VERSION ""

NS_ :

BS_:

BU_: ADAS ADASBUS_Virtual_ECU FCM GW PKC

BO_ 821 BCM_0x335: 8 GW
 SG_ BCM_335_CheckSum : 7|8@0+ (1,0) [0|255] ""  ADAS,FCM,PKC
 SG_ BCM_335_AliveCounter : 11|4@0+ (1,0) [0|14] ""  ADAS,FCM,PKC
 SG_ BCM_WiprInSrvPosn : 12|1@0+ (1,0) [0|1] ""  ADASBUS_Virtual_ECU
 SG_ BCM_IntLampTiSetSts : 15|3@0+ (1,0) [0|7] ""  ADASBUS_Virtual_ECU
 SG_ BCM_WaterPosnSnsrSwtSts : 16|1@0+ (1,0) [0|1] ""  ADASBUS_Virtual_ECU
 SG_ BCM_FrntFogLampOutpCmd : 17|1@0+ (1,0) [0|1] ""  ADAS
 SG_ BCM_LicPlateLampOutpCmd : 18|1@0+ (1,0) [0|1] ""  ADASBUS_Virtual_ECU
 SG_ BCM_EnaSts_ADB : 19|1@0+ (1,0) [0|1] ""  ADAS
 SG_ BCM_PwrSaveOutpCmd : 20|1@0+ (1,0) [0|1] ""  ADASBUS_Virtual_ECU
 SG_ BCM_ExtLampSwtSts : 23|3@0+ (1,0) [0|7] ""  ADAS,FCM
 SG_ BCM_HornOutpCmd : 24|1@0+ (1,0) [0|1] ""  ADASBUS_Virtual_ECU
 SG_ BCM_HornSwtSts : 25|1@0+ (1,0) [0|1] ""  ADASBUS_Virtual_ECU
 SG_ BCM_WelLampOutpCmd : 26|1@0+ (1,0) [0|1] ""  ADASBUS_Virtual_ECU
 SG_ BCM_FolwMeHomeSts : 27|1@0+ (1,0) [0|1] ""  ADASBUS_Virtual_ECU
 SG_ BCM_FrntFogLampSwtSts : 28|1@0+ (1,0) [0|1] ""  ADAS
 SG_ BCM_ReFogLampSwtSts : 29|1@0+ (1,0) [0|1] ""  ADAS,FCM
 SG_ BCM_ReWiprBackSwtSts : 30|1@0+ (1,0) [0|1] ""  ADAS
 SG_ BCM_RainClsSunroofSetSts : 31|1@0+ (1,0) [0|0] ""  ADASBUS_Virtual_ECU
 SG_ BCM_MirrLockAutoSetSts : 32|1@0+ (1,0) [0|1] ""  ADASBUS_Virtual_ECU
 SG_ BCM_FrntWshrOutpCmd : 33|1@0+ (1,0) [0|1] ""  ADASBUS_Virtual_ECU
 SG_ BCM_DangerAlrmLampSwtSts : 34|1@0+ (1,0) [0|1] ""  ADAS,PKC
 SG_ BCM_ReDefrstHeatgCmd : 35|1@0+ (1,0) [0|1] ""  ADASBUS_Virtual_ECU
 SG_ BCM_RvsLampOutpCmd : 36|1@0+ (1,0) [0|1] ""  ADAS
 SG_ BCM_IntLampOutpCmd : 37|1@0+ (1,0) [0|1] ""  ADASBUS_Virtual_ECU
 SG_ BCM_LeTrunLampOutpCmd : 38|1@0+ (1,0) [0|1] ""  ADAS
 SG_ BCM_RiTrunLampOutpCmd : 39|1@0+ (1,0) [0|1] ""  ADAS
 SG_ BCM_ReWiprOutpCmd : 40|1@0+ (1,0) [0|1] ""  ADAS
 SG_ BCM_ReWshrOutpCmd : 41|1@0+ (1,0) [0|1] ""  ADASBUS_Virtual_ECU
 SG_ BCM_BrkLampSwtSts : 42|1@0+ (1,0) [0|1] ""  ADAS
 SG_ BCM_HiBeamOutpCmd : 43|1@0+ (1,0) [0|1] ""  ADAS,FCM
 SG_ BCM_LoBeamOutpCmd : 44|1@0+ (1,0) [0|1] ""  ADAS,FCM
 SG_ BCM_PosnLampOutpCmd : 46|2@0+ (1,0) [0|3] ""  ADAS
 SG_ BCM_BrkLampOutpCmd : 47|1@0+ (1,0) [0|1] ""  ADAS
 SG_ BCM_ReFogLampOutpCmd : 48|1@0+ (1,0) [0|1] ""  ADAS
 SG_ BCM_FrntWiprSpd : 54|6@0+ (1,0) [0|63] "time/m"  ADAS,FCM
 SG_ BCM_EnaReq_ADB : 55|1@0+ (1,0) [0|1] ""  ADAS
 SG_ BCM_VehAmbBri : 63|8@0+ (100,0) [0|25400] "lx"  ADAS

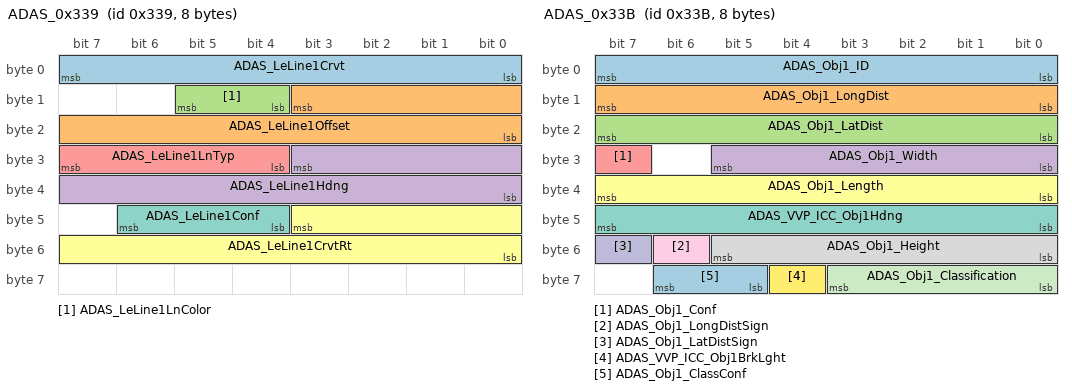
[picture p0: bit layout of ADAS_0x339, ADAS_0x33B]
BO_ 825 ADAS_0x339: 8 ADAS
 SG_ ADAS_LeLine1Crvt : 7|8@0+ (50,-3150) [-3150|3200] "m"  GW
 SG_ ADAS_LeLine1Offset : 11|12@0+ (0.0125,0) [0|50] "m"  GW
 SG_ ADAS_LeLine1LnColor : 13|2@0+ (1,0) [0|3] ""  GW
 SG_ ADAS_LeLine1Hdng : 27|12@0+ (0.05,0) [0|180] "deg"  GW
 SG_ ADAS_LeLine1LnTyp : 31|4@0+ (1,0) [0|15] ""  GW
 SG_ ADAS_LeLine1CrvtRt : 43|12@0+ (0.05,0) [0|180] "xx"  GW
 SG_ ADAS_LeLine1Conf : 46|3@0+ (1,0) [0|7] ""  GW

BO_ 827 ADAS_0x33B: 8 ADAS
 SG_ ADAS_Obj1_ID : 7|8@0+ (1,0) [0|255] ""  GW
 SG_ ADAS_Obj1_LongDist : 15|8@0+ (0.2,0) [0|51] "m"  GW
 SG_ ADAS_Obj1_LatDist : 23|8@0+ (0.2,0) [0|51] "m"  GW
 SG_ ADAS_Obj1_Width : 29|6@0+ (0.1,0) [0|6.3] "m"  GW
 SG_ ADAS_Obj1_Conf : 31|1@0+ (1,0) [0|1] ""  GW
 SG_ ADAS_Obj1_Length : 39|8@0+ (0.2,0) [0|50] "m"  GW
 SG_ ADAS_VVP_ICC_Obj1Hdng : 47|8@0+ (1.5,0) [0|360] "deg"  GW
 SG_ ADAS_Obj1_Height : 53|6@0+ (0.1,0) [0|6.3] "m"  GW
 SG_ ADAS_Obj1_LongDistSign : 54|1@0+ (1,0) [0|1] ""  GW
 SG_ ADAS_Obj1_LatDistSign : 55|1@0+ (1,0) [0|1] ""  GW
 SG_ ADAS_Obj1_Classification : 59|4@0+ (1,0) [0|15] ""  GW
 SG_ ADAS_VVP_ICC_Obj1BrkLght : 60|1@0+ (1,0) [0|1] ""  GW
 SG_ ADAS_Obj1_ClassConf : 62|2@0+ (1,0) [0|3] ""  GW

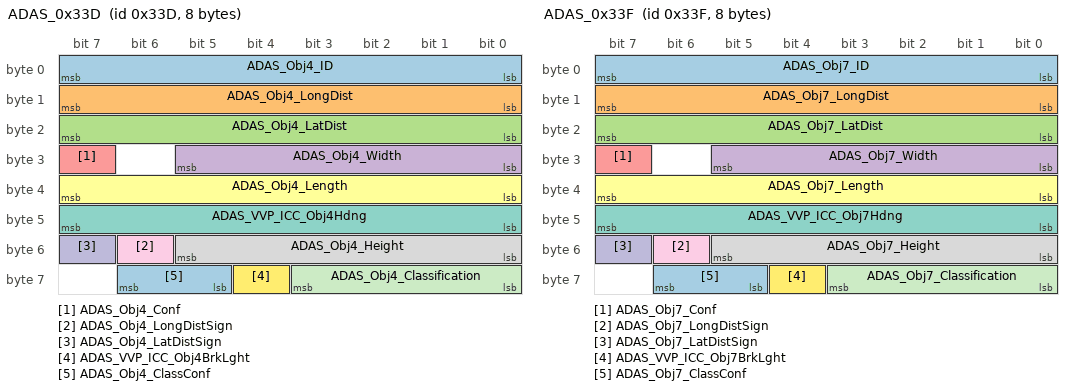
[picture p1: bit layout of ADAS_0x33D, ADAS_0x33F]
BO_ 829 ADAS_0x33D: 8 ADAS
 SG_ ADAS_Obj4_ID : 7|8@0+ (1,0) [0|255] ""  GW
 SG_ ADAS_Obj4_LongDist : 15|8@0+ (0.2,0) [0|51] "m"  GW
 SG_ ADAS_Obj4_LatDist : 23|8@0+ (0.2,0) [0|51] "m"  GW
 SG_ ADAS_Obj4_Width : 29|6@0+ (0.1,0) [0|6.3] "m"  GW
 SG_ ADAS_Obj4_Conf : 31|1@0+ (1,0) [0|1] ""  GW
 SG_ ADAS_Obj4_Length : 39|8@0+ (0.2,0) [0|50] "m"  GW
 SG_ ADAS_VVP_ICC_Obj4Hdng : 47|8@0+ (1.5,0) [0|360] "deg"  GW
 SG_ ADAS_Obj4_Height : 53|6@0+ (0.1,0) [0|6.3] "m"  GW
 SG_ ADAS_Obj4_LongDistSign : 54|1@0+ (1,0) [0|1] ""  GW
 SG_ ADAS_Obj4_LatDistSign : 55|1@0+ (1,0) [0|1] ""  GW
 SG_ ADAS_Obj4_Classification : 59|4@0+ (1,0) [0|15] ""  GW
 SG_ ADAS_VVP_ICC_Obj4BrkLght : 60|1@0+ (1,0) [0|1] ""  GW
 SG_ ADAS_Obj4_ClassConf : 62|2@0+ (1,0) [0|3] ""  GW

BO_ 831 ADAS_0x33F: 8 ADAS
 SG_ ADAS_Obj7_ID : 7|8@0+ (1,0) [0|255] ""  GW
 SG_ ADAS_Obj7_LongDist : 15|8@0+ (0.2,0) [0|51] "m"  GW
 SG_ ADAS_Obj7_LatDist : 23|8@0+ (0.2,0) [0|51] "m"  GW
 SG_ ADAS_Obj7_Width : 29|6@0+ (0.1,0) [0|6.3] "m"  GW
 SG_ ADAS_Obj7_Conf : 31|1@0+ (1,0) [0|1] ""  GW
 SG_ ADAS_Obj7_Length : 39|8@0+ (0.2,0) [0|50] "m"  GW
 SG_ ADAS_VVP_ICC_Obj7Hdng : 47|8@0+ (1.5,0) [0|360] "deg"  GW
 SG_ ADAS_Obj7_Height : 53|6@0+ (0.1,0) [0|6.3] "m"  GW
 SG_ ADAS_Obj7_LongDistSign : 54|1@0+ (1,0) [0|1] ""  GW
 SG_ ADAS_Obj7_LatDistSign : 55|1@0+ (1,0) [0|1] ""  GW
 SG_ ADAS_Obj7_Classification : 59|4@0+ (1,0) [0|15] ""  GW
 SG_ ADAS_VVP_ICC_Obj7BrkLght : 60|1@0+ (1,0) [0|1] ""  GW
 SG_ ADAS_Obj7_ClassConf : 62|2@0+ (1,0) [0|3] ""  GW

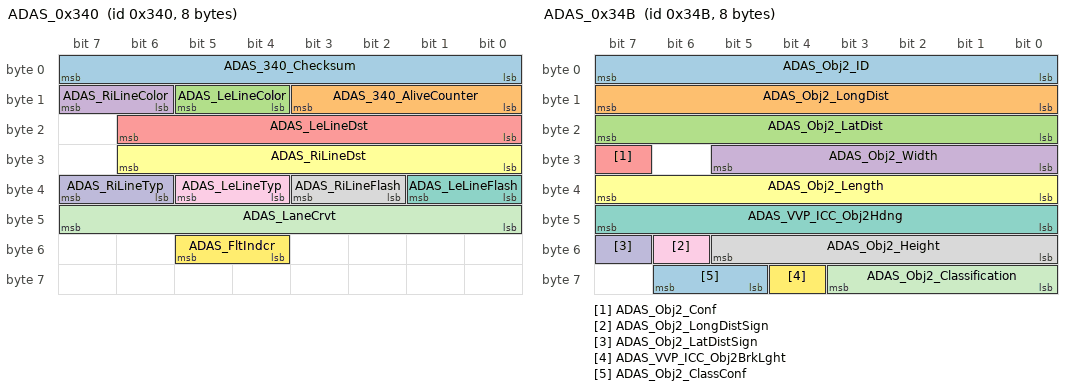
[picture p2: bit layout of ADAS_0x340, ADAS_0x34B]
BO_ 832 ADAS_0x340: 8 ADAS
 SG_ ADAS_340_Checksum : 7|8@0+ (1,0) [0|255] ""  GW
 SG_ ADAS_340_AliveCounter : 11|4@0+ (1,0) [0|14] ""  GW
 SG_ ADAS_LeLineColor : 13|2@0+ (1,0) [0|3] ""  GW
 SG_ ADAS_RiLineColor : 15|2@0+ (1,0) [0|3] ""  GW
 SG_ ADAS_LeLineDst : 22|7@0+ (0.1,-6.2) [-6.2|6.2] "m"  GW
 SG_ ADAS_RiLineDst : 30|7@0+ (0.1,-6.2) [-6.2|6.2] "m"  GW
 SG_ ADAS_LeLineFlash : 33|2@0+ (1,0) [0|3] ""  GW
 SG_ ADAS_RiLineFlash : 35|2@0+ (1,0) [0|3] ""  GW
 SG_ ADAS_LeLineTyp : 37|2@0+ (1,0) [0|3] ""  GW
 SG_ ADAS_RiLineTyp : 39|2@0+ (1,0) [0|3] ""  GW
 SG_ ADAS_LaneCrvt : 47|8@0+ (50,-3150) [-3150|3200] "m"  GW
 SG_ ADAS_FltIndcr : 53|2@0+ (1,0) [0|3] ""  GW

BO_ 834 ADAS_0x342: 8 ADAS
 SG_ ADAS_342_Checksum : 7|8@0+ (1,0) [0|255] ""  GW,PKC
 SG_ ADAS_342_AliveCounter : 11|4@0+ (1,0) [0|14] ""  GW,PKC
 SG_ ADAS_LatCtrl_LeTurnLampReq : 13|2@0+ (1,0) [0|3] ""  GW
 SG_ ADAS_LatCtrl_RiTurnLampReq : 15|2@0+ (1,0) [0|3] ""  GW
 SG_ ADAS_LatCtrl_HapticReq : 17|2@0+ (1,0) [0|3] ""  GW
 SG_ ADAS_LatCtrl_HzrdLampReq : 19|2@0+ (1,0) [0|3] ""  GW
 SG_ ADAS_VehMovDir : 21|2@0+ (1,0) [0|3] ""  GW,PKC
 SG_ ADAS_HOD_HandsOnWarnReq : 23|2@0+ (1,0) [0|1] ""  GW
 SG_ ADAS_DoorLockReq : 25|2@0+ (1,0) [0|3] ""  GW
 SG_ ADAS_AVASReq : 27|2@0+ (1,0) [0|3] ""  GW
 SG_ ADAS_RAPAvl : 28|1@0+ (1,0) [0|1] ""  GW,PKC
 SG_ ADAS_TPReplayAvl : 29|1@0+ (1,0) [0|1] ""  GW,PKC
 SG_ ADAS_TPReplaySuc : 30|1@0+ (1,0) [0|1] ""  GW,PKC
 SG_ ADAS_Sts_RAP : 34|3@0+ (1,0) [0|7] ""  GW,PKC
 SG_ ADAS_Sts_TP : 37|3@0+ (1,0) [0|7] ""  GW,PKC
 SG_ ADAS_ExtLightReq : 38|1@0+ (1,0) [0|1] ""  GW
 SG_ ADAS_HODSts : 42|3@0+ (1,0) [0|7] ""  GW

BO_ 835 BCM_0x343: 8 GW
 SG_ BCM_343_CheckSum : 7|8@0+ (1,0) [0|255] ""  ADAS,PKC
 SG_ BCM_343_AliveCounter : 11|4@0+ (1,0) [0|14] ""  ADAS,PKC
 SG_ BCM_RemReqFb : 13|2@0+ (1,0) [0|3] ""  ADASBUS_Virtual_ECU
 SG_ BCM_APASwSts : 15|2@0+ (1,0) [0|3] ""  ADAS
 SG_ BCM_FrntHoodLidSts : 16|1@0+ (1,0) [0|1] ""  ADAS,PKC
 SG_ BCM_SunroofAntipinchSts : 17|1@0+ (1,0) [0|1] ""  ADAS
 SG_ BCM_FrntDrDoorLockSts : 18|1@0+ (1,0) [0|1] ""  ADAS,PKC
 SG_ BCM_TrRelsSwtSts : 19|1@0+ (1,0) [0|1] ""  ADAS,PKC
 SG_ BCM_LockAllDoorCmd : 20|1@0+ (1,0) [0|1] ""  ADAS
 SG_ BCM_DrFrntDoorSts : 21|1@0+ (1,0) [0|1] ""  ADAS,PKC
 SG_ BCM_PasFrntDoorSts : 22|1@0+ (1,0) [0|1] ""  ADAS,PKC
 SG_ BCM_AntithftSts : 25|2@0+ (1,0) [0|3] ""  PKC
 SG_ BCM_CenLockSwtSts : 27|2@0+ (1,0) [0|3] ""  ADAS,PKC
 SG_ BCM_DoorUnlockSetFb : 28|1@0+ (1,0) [0|1] ""  ADASBUS_Virtual_ECU
 SG_ BCM_RiReDoorSts : 29|1@0+ (1,0) [0|1] ""  ADAS,PKC
 SG_ BCM_LeReDoorSts : 30|1@0+ (1,0) [0|1] ""  ADAS,PKC
 SG_ BCM_LeFrntWinSts : 31|1@0+ (1,0) [0|1] ""  ADAS,PKC
 SG_ BCM_RiFrntWinSts : 32|1@0+ (1,0) [0|1] ""  ADAS,PKC
 SG_ BCM_LeReWinSts : 33|1@0+ (1,0) [0|1] ""  ADAS,PKC
 SG_ BCM_RiReWinSt : 34|1@0+ (1,0) [0|1] ""  ADAS,PKC
 SG_ BCM_SunroofSts : 35|1@0+ (1,0) [0|1] ""  ADAS,PKC
 SG_ BCM_FolwMeSetStsFb : 38|3@0+ (1,0) [0|7] ""  ADASBUS_Virtual_ECU
 SG_ BCM_DrvrDoorUnlckOutpCmd : 39|1@0+ (1,0) [0|1] ""  ADASBUS_Virtual_ECU
 SG_ BCM_PassDoorUnlckOutpCmd : 40|1@0+ (1,0) [0|1] ""  ADASBUS_Virtual_ECU
 SG_ BCM_LeDRLOutpCmd : 41|1@0+ (1,0) [0|1] ""  ADASBUS_Virtual_ECU
 SG_ BCM_RiDRLOutpCmd : 42|1@0+ (1,0) [0|1] ""  ADASBUS_Virtual_ECU
 SG_ BCM_ArmedClsWinSetSts : 44|1@0+ (1,0) [0|1] ""  ADASBUS_Virtual_ECU
 SG_ BCM_OffAutoUnlckSetSts : 45|1@0+ (1,0) [0|1] ""  ADASBUS_Virtual_ECU
 SG_ BCM_WarnVbrnSts : 46|1@0+ (1,0) [0|1] ""  ADAS
 SG_ BCM_SunroofPosnInfo : 55|7@0+ (1,0) [0|127] "%"  PKC
 SG_ BCM_SunroofOpenAr : 56|1@0+ (1,0) [0|1] ""  ADASBUS_Virtual_ECU
 SG_ BCM_SteerWhlVbrnAlrmAvl : 58|2@0+ (1,0) [0|3] ""  ADAS
 SG_ BCM_SunroofRunngSts : 61|3@0+ (1,0) [0|7] ""  ADAS
 SG_ BCM_MirrCmd : 63|2@0+ (1,0) [0|3] ""  ADAS

BO_ 843 ADAS_0x34B: 8 ADAS
 SG_ ADAS_Obj2_ID : 7|8@0+ (1,0) [0|255] ""  GW
 SG_ ADAS_Obj2_LongDist : 15|8@0+ (0.2,0) [0|51] "m"  GW
 SG_ ADAS_Obj2_LatDist : 23|8@0+ (0.2,0) [0|51] "m"  GW
 SG_ ADAS_Obj2_Width : 29|6@0+ (0.1,0) [0|6.3] "m"  GW
 SG_ ADAS_Obj2_Conf : 31|1@0+ (1,0) [0|1] ""  GW
 SG_ ADAS_Obj2_Length : 39|8@0+ (0.2,0) [0|50] "m"  GW
 SG_ ADAS_VVP_ICC_Obj2Hdng : 47|8@0+ (1.5,0) [0|360] "deg"  GW
 SG_ ADAS_Obj2_Height : 53|6@0+ (0.1,0) [0|6.3] "m"  GW
 SG_ ADAS_Obj2_LongDistSign : 54|1@0+ (1,0) [0|1] ""  GW
 SG_ ADAS_Obj2_LatDistSign : 55|1@0+ (1,0) [0|1] ""  GW
 SG_ ADAS_Obj2_Classification : 59|4@0+ (1,0) [0|15] ""  GW
 SG_ ADAS_VVP_ICC_Obj2BrkLght : 60|1@0+ (1,0) [0|1] ""  GW
 SG_ ADAS_Obj2_ClassConf : 62|2@0+ (1,0) [0|3] ""  GW

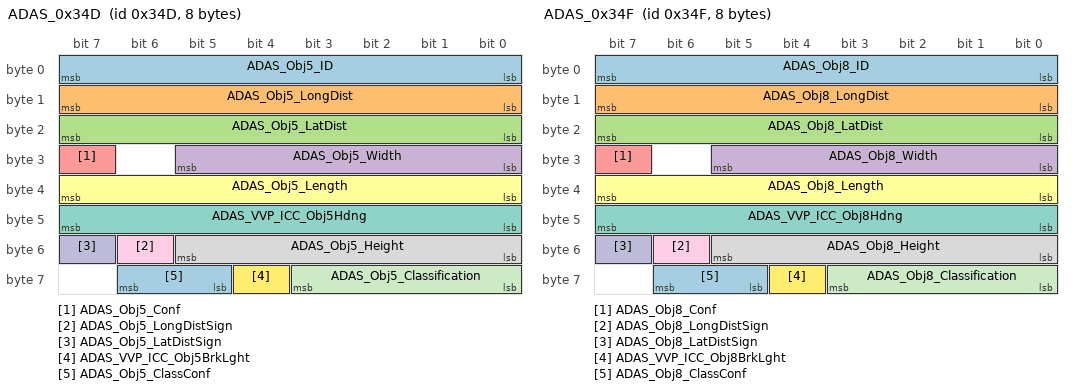
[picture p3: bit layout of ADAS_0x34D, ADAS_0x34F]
BO_ 845 ADAS_0x34D: 8 ADAS
 SG_ ADAS_Obj5_ID : 7|8@0+ (1,0) [0|255] ""  GW
 SG_ ADAS_Obj5_LongDist : 15|8@0+ (0.2,0) [0|51] "m"  GW
 SG_ ADAS_Obj5_LatDist : 23|8@0+ (0.2,0) [0|51] "m"  GW
 SG_ ADAS_Obj5_Width : 29|6@0+ (0.1,0) [0|6.3] "m"  GW
 SG_ ADAS_Obj5_Conf : 31|1@0+ (1,0) [0|1] ""  GW
 SG_ ADAS_Obj5_Length : 39|8@0+ (0.2,0) [0|50] "m"  GW
 SG_ ADAS_VVP_ICC_Obj5Hdng : 47|8@0+ (1.5,0) [0|360] "deg"  GW
 SG_ ADAS_Obj5_Height : 53|6@0+ (0.1,0) [0|6.3] "m"  GW
 SG_ ADAS_Obj5_LongDistSign : 54|1@0+ (1,0) [0|1] ""  GW
 SG_ ADAS_Obj5_LatDistSign : 55|1@0+ (1,0) [0|1] ""  GW
 SG_ ADAS_Obj5_Classification : 59|4@0+ (1,0) [0|15] ""  GW
 SG_ ADAS_VVP_ICC_Obj5BrkLght : 60|1@0+ (1,0) [0|1] ""  GW
 SG_ ADAS_Obj5_ClassConf : 62|2@0+ (1,0) [0|3] ""  GW

BO_ 847 ADAS_0x34F: 8 ADAS
 SG_ ADAS_Obj8_ID : 7|8@0+ (1,0) [0|255] ""  GW
 SG_ ADAS_Obj8_LongDist : 15|8@0+ (0.2,0) [0|51] "m"  GW
 SG_ ADAS_Obj8_LatDist : 23|8@0+ (0.2,0) [0|51] "m"  GW
 SG_ ADAS_Obj8_Width : 29|6@0+ (0.1,0) [0|6.3] "m"  GW
 SG_ ADAS_Obj8_Conf : 31|1@0+ (1,0) [0|1] ""  GW
 SG_ ADAS_Obj8_Length : 39|8@0+ (0.2,0) [0|50] "m"  GW
 SG_ ADAS_VVP_ICC_Obj8Hdng : 47|8@0+ (1.5,0) [0|360] "deg"  GW
 SG_ ADAS_Obj8_Height : 53|6@0+ (0.1,0) [0|6.3] "m"  GW
 SG_ ADAS_Obj8_LongDistSign : 54|1@0+ (1,0) [0|1] ""  GW
 SG_ ADAS_Obj8_LatDistSign : 55|1@0+ (1,0) [0|1] ""  GW
 SG_ ADAS_Obj8_Classification : 59|4@0+ (1,0) [0|15] ""  GW
 SG_ ADAS_VVP_ICC_Obj8BrkLght : 60|1@0+ (1,0) [0|1] ""  GW
 SG_ ADAS_Obj8_ClassConf : 62|2@0+ (1,0) [0|3] ""  GW

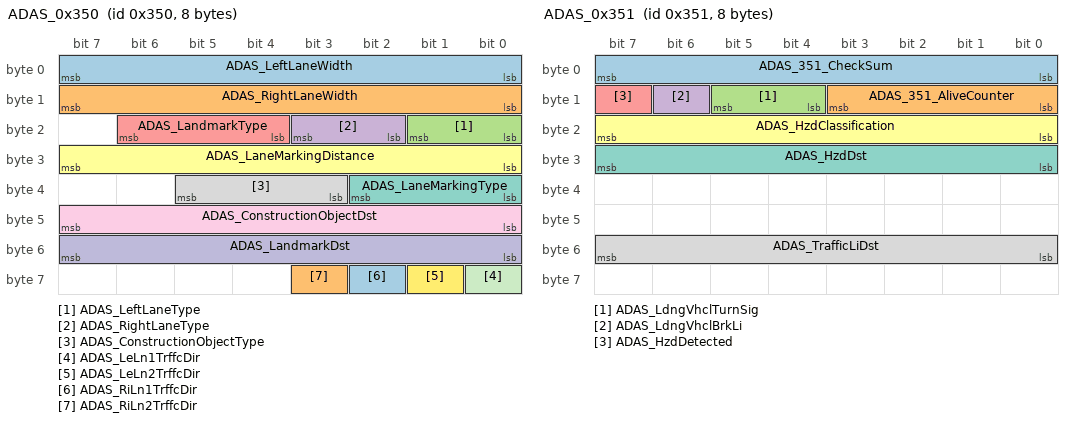
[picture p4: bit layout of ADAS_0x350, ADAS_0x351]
BO_ 848 ADAS_0x350: 8 ADAS
 SG_ ADAS_LeftLaneWidth : 7|8@0+ (0.1,0) [0|25.5] "m"  GW
 SG_ ADAS_RightLaneWidth : 15|8@0+ (0.1,0) [0|25.5] "m"  GW
 SG_ ADAS_LeftLaneType : 17|2@0+ (1,0) [0|3] ""  GW
 SG_ ADAS_RightLaneType : 19|2@0+ (1,0) [0|3] ""  GW
 SG_ ADAS_LandmarkType : 22|3@0+ (1,0) [0|7] ""  GW
 SG_ ADAS_LaneMarkingDistance : 31|8@0+ (1,0) [0|255] "m"  GW
 SG_ ADAS_LaneMarkingType : 34|3@0+ (1,0) [0|7] ""  GW
 SG_ ADAS_ConstructionObjectType : 37|3@0+ (1,0) [0|7] ""  GW
 SG_ ADAS_ConstructionObjectDst : 47|8@0+ (1,0) [0|255] "m"  GW
 SG_ ADAS_LandmarkDst : 55|8@0+ (1,0) [0|255] "m"  GW
 SG_ ADAS_LeLn1TrffcDir : 56|1@0+ (1,0) [0|1] ""  GW
 SG_ ADAS_LeLn2TrffcDir : 57|1@0+ (1,0) [0|1] ""  GW
 SG_ ADAS_RiLn1TrffcDir : 58|1@0+ (1,0) [0|1] ""  GW
 SG_ ADAS_RiLn2TrffcDir : 59|1@0+ (1,0) [0|1] ""  GW

BO_ 849 ADAS_0x351: 8 ADAS
 SG_ ADAS_351_CheckSum : 7|8@0+ (1,0) [0|255] ""  GW
 SG_ ADAS_351_AliveCounter : 11|4@0+ (1,0) [0|14] ""  GW
 SG_ ADAS_LdngVhclTurnSig : 13|2@0+ (1,0) [0|3] ""  GW
 SG_ ADAS_LdngVhclBrkLi : 14|1@0+ (1,0) [0|1] ""  GW
 SG_ ADAS_HzdDetected : 15|1@0+ (1,0) [0|1] ""  GW
 SG_ ADAS_HzdClassification : 23|8@0+ (1,0) [0|255] ""  GW
 SG_ ADAS_HzdDst : 31|8@0+ (1,0) [0|255] "m"  GW
 SG_ ADAS_TrafficLiDst : 55|8@0+ (1,0) [0|255] "m"  GW

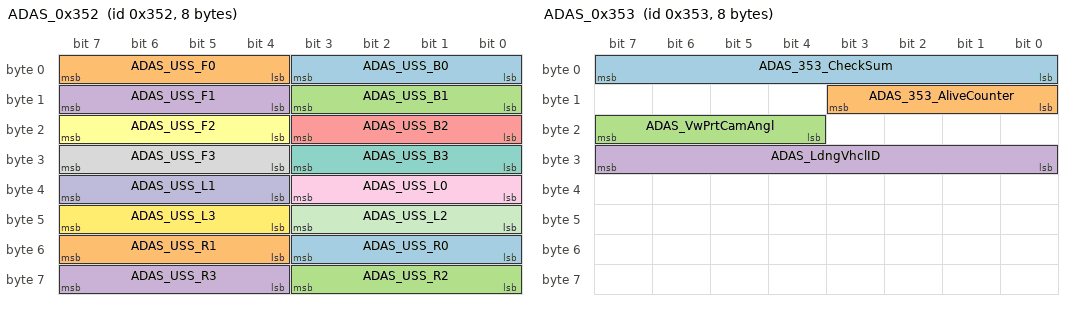
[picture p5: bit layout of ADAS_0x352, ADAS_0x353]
BO_ 850 ADAS_0x352: 8 ADAS
 SG_ ADAS_USS_B0 : 3|4@0+ (1,0) [0|15] ""  GW
 SG_ ADAS_USS_F0 : 7|4@0+ (1,0) [0|15] ""  GW
 SG_ ADAS_USS_B1 : 11|4@0+ (1,0) [0|15] ""  GW
 SG_ ADAS_USS_F1 : 15|4@0+ (1,0) [0|15] ""  GW
 SG_ ADAS_USS_B2 : 19|4@0+ (1,0) [0|15] ""  GW
 SG_ ADAS_USS_F2 : 23|4@0+ (1,0) [0|15] ""  GW
 SG_ ADAS_USS_B3 : 27|4@0+ (1,0) [0|15] ""  GW
 SG_ ADAS_USS_F3 : 31|4@0+ (1,0) [0|15] ""  GW
 SG_ ADAS_USS_L0 : 35|4@0+ (1,0) [0|15] ""  GW
 SG_ ADAS_USS_L1 : 39|4@0+ (1,0) [0|15] ""  GW
 SG_ ADAS_USS_L2 : 43|4@0+ (1,0) [0|15] ""  GW
 SG_ ADAS_USS_L3 : 47|4@0+ (1,0) [0|15] ""  GW
 SG_ ADAS_USS_R0 : 51|4@0+ (1,0) [0|15] ""  GW
 SG_ ADAS_USS_R1 : 55|4@0+ (1,0) [0|15] ""  GW
 SG_ ADAS_USS_R2 : 59|4@0+ (1,0) [0|15] ""  GW
 SG_ ADAS_USS_R3 : 63|4@0+ (1,0) [0|15] ""  GW

BO_ 851 ADAS_0x353: 8 ADAS
 SG_ ADAS_353_CheckSum : 7|8@0+ (1,0) [0|255] ""  GW
 SG_ ADAS_353_AliveCounter : 11|4@0+ (1,0) [0|14] ""  GW
 SG_ ADAS_VwPrtCamAngl : 23|4@0+ (1,0) [0|15] ""  GW
 SG_ ADAS_LdngVhclID : 31|8@0+ (1,0) [0|255] ""  GW

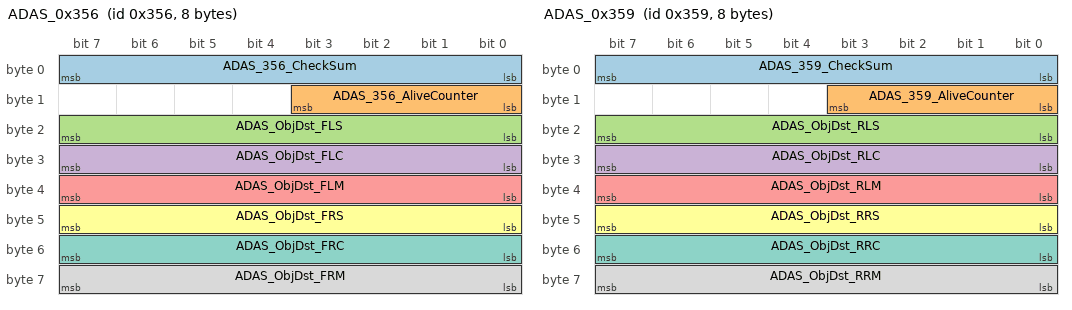
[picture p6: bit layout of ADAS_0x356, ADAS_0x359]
BO_ 854 ADAS_0x356: 8 ADAS
 SG_ ADAS_356_CheckSum : 7|8@0+ (1,0) [0|255] ""  GW
 SG_ ADAS_356_AliveCounter : 11|4@0+ (1,0) [0|14] ""  GW
 SG_ ADAS_ObjDst_FLS : 23|8@0+ (1,0) [0|255] "cm"  GW
 SG_ ADAS_ObjDst_FLC : 31|8@0+ (1,0) [0|255] "cm"  GW
 SG_ ADAS_ObjDst_FLM : 39|8@0+ (1,0) [0|255] "cm"  GW
 SG_ ADAS_ObjDst_FRS : 47|8@0+ (1,0) [0|255] "cm"  GW
 SG_ ADAS_ObjDst_FRC : 55|8@0+ (1,0) [0|255] "cm"  GW
 SG_ ADAS_ObjDst_FRM : 63|8@0+ (1,0) [0|255] "cm"  GW

BO_ 856 VCU_0x358: 8 GW
 SG_ VCU_358_CheckSum : 7|8@0+ (1,0) [0|255] ""  ADAS
 SG_ VCU_358_AliveCounter : 11|4@0+ (1,0) [0|14] ""  ADAS
 SG_ VCU_KickdwnFlg : 13|2@0+ (1,0) [0|3] ""  ADASBUS_Virtual_ECU
 SG_ VCU_EPedlEnaSig : 15|1@0+ (1,0) [0|1] ""  ADASBUS_Virtual_ECU
 SG_ VCU_ComLostFlt_ESP : 16|1@0+ (1,0) [0|1] ""  ADASBUS_Virtual_ECU
 SG_ VCU_ComFlt_iBooster : 17|1@0+ (1,0) [0|1] ""  ADASBUS_Virtual_ECU
 SG_ VCU_RegenLvlFb : 19|2@0+ (1,0) [0|3] ""  ADASBUS_Virtual_ECU
 SG_ VCU_AccelModFb : 21|2@0+ (1,0) [0|3] ""  ADASBUS_Virtual_ECU
 SG_ VCU_EPedlStsFb : 23|2@0+ (1,0) [0|3] ""  ADASBUS_Virtual_ECU
 SG_ VCU_CcTrgSpdDisp : 31|8@0+ (1,0) [0|255] ""  ADASBUS_Virtual_ECU
 SG_ VCU_Sts_CC_ICC : 35|4@0+ (1,0) [0|15] ""  ADASBUS_Virtual_ECU
 SG_ VCU_CCIconDisp : 38|3@0+ (1,0) [0|7] ""  ADASBUS_Virtual_ECU
 SG_ VCU_DispSpdUnit_CC : 39|1@0+ (1,0) [0|1] ""  ADASBUS_Virtual_ECU
 SG_ VCU_BoostEnStat : 43|4@0+ (1,0) [0|15] ""  ADASBUS_Virtual_ECU
 SG_ VCU_OTARdy_Fb : 45|2@0+ (1,0) [0|3] ""  ADASBUS_Virtual_ECU
 SG_ VCU_OTA_ECUInhb_Req : 47|2@0+ (1,0) [0|3] ""  ADAS,PKC
 SG_ VCU_OTAVehCdnChk_ASIL : 49|2@0+ (1,0) [0|3] ""  ADAS,FCM,PKC
 SG_ VCU_OTAVehInhb_ASIL_Fb : 51|2@0+ (1,0) [0|3] ""  ADAS,FCM,PKC

BO_ 857 ADAS_0x359: 8 ADAS
 SG_ ADAS_359_CheckSum : 7|8@0+ (1,0) [0|255] ""  GW
 SG_ ADAS_359_AliveCounter : 11|4@0+ (1,0) [0|14] ""  GW
 SG_ ADAS_ObjDst_RLS : 23|8@0+ (1,0) [0|255] "cm"  GW
 SG_ ADAS_ObjDst_RLC : 31|8@0+ (1,0) [0|255] "cm"  GW
 SG_ ADAS_ObjDst_RLM : 39|8@0+ (1,0) [0|255] "cm"  GW
 SG_ ADAS_ObjDst_RRS : 47|8@0+ (1,0) [0|255] "cm"  GW
 SG_ ADAS_ObjDst_RRC : 55|8@0+ (1,0) [0|255] "cm"  GW
 SG_ ADAS_ObjDst_RRM : 63|8@0+ (1,0) [0|255] "cm"  GW

BO_ 859 ICC_0x35B: 8 GW
 SG_ ICC_ViewReq : 15|4@0+ (1,0) [0|15] ""  ADAS
 SG_ ICC_ShowSts : 16|1@0+ (1,0) [0|1] ""  ADAS
 SG_ ICC_SVS_AutoVwBttnReq : 17|1@0+ (1,0) [0|1] ""  ADAS
 SG_ ICC_SVS_CamVwCnclReq : 18|1@0+ (1,0) [0|1] ""  ADAS
 SG_ ICC_AutomaticViewReq : 19|1@0+ (1,0) [0|1] ""  ADAS
 SG_ ICC_360FreeFloatingReq : 20|1@0+ (1,0) [0|1] ""  ADAS
 SG_ ICC_GraphicOverlayReq : 21|1@0+ (1,0) [0|1] ""  ADAS
 SG_ ICC_OperationType : 23|2@0+ (1,0) [0|3] ""  ADAS
 SG_ ICC_ZOOM_Start : 24|1@0+ (1,0) [0|1] ""  ADAS
 SG_ ICC_ZOOM_End : 25|1@0+ (1,0) [0|1] ""  ADAS
 SG_ ICC_ZOOM_ScalingFactor : 30|5@0+ (1,0) [0|31] ""  ADAS
 SG_ ICC_EnbLnChgAsst : 31|1@0+ (1,0) [0|1] ""  ADAS
 SG_ ICC_BSDSetting : 33|2@0+ (1,0) [0|3] ""  ADAS
 SG_ ICC_DOW_Setting : 35|2@0+ (1,0) [0|3] ""  ADAS
 SG_ ICC_DCAASetting : 37|2@0+ (1,0) [0|3] ""  ADAS
 SG_ ICC_APA_Setting : 39|2@0+ (1,0) [0|3] ""  ADAS
 SG_ ICC_APAParkSelect : 43|4@0+ (1,0) [0|15] ""  ADAS
 SG_ ICC_APAActivation : 44|1@0+ (1,0) [0|1] ""  ADAS
 SG_ ICC_APAParkInDirSetting : 45|1@0+ (1,0) [0|1] ""  ADAS
 SG_ ICC_APAParkOutDirSetting : 46|1@0+ (1,0) [0|1] ""  ADAS
 SG_ ICC_ParkAsstChmAlrt : 47|1@0+ (1,0) [0|1] ""  ADAS
 SG_ ICC_WSPPA_Setting : 49|2@0+ (1,0) [0|3] ""  ADAS
 SG_ ICC_AHBA_Setting : 50|1@0+ (1,0) [0|1] ""  ADAS
 SG_ ICC_APAParkOutAct : 52|2@0+ (1,0) [0|3] ""  ADAS
 SG_ ICC_SteerWhlVibrSet : 53|1@0+ (1,0) [0|1] ""  ADAS
 SG_ ICC_WarnTypeSetting : 55|2@0+ (1,0) [0|3] ""  ADAS
 SG_ ICC_LKA_SettingWrnTyp : 57|2@0+ (1,0) [0|3] ""  ADAS
 SG_ ICC_RAP_Setting : 59|2@0+ (1,0) [0|3] ""  ADAS
 SG_ ICC_TP_Setting : 61|2@0+ (1,0) [0|3] ""  ADAS
 SG_ ICC_BSD_Sensitivity : 63|2@0+ (1,0) [0|3] ""  ADAS

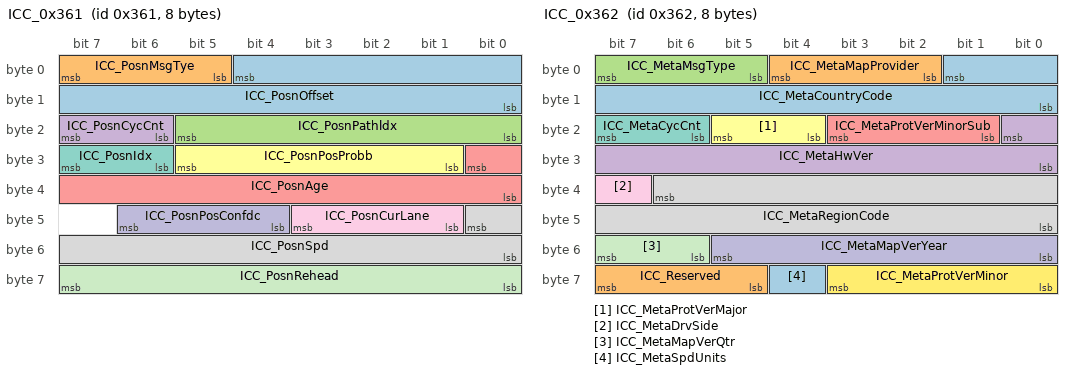
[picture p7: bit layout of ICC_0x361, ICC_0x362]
BO_ 865 ICC_0x361: 8 GW
 SG_ ICC_PosnOffset : 4|13@0+ (1,0) [0|8190] "m"  ADAS
 SG_ ICC_PosnMsgTye : 7|3@0+ (1,0) [0|7] ""  ADAS
 SG_ ICC_PosnPathldx : 21|6@0+ (1,0) [8|63] ""  ADAS
 SG_ ICC_PosnCycCnt : 23|2@0+ (1,0) [0|3] ""  ADAS
 SG_ ICC_PosnAge : 24|9@0+ (5,0) [0|2545] "ms"  ADAS
 SG_ ICC_PosnPosProbb : 29|5@0+ (3.333,0) [0|100] "%"  ADAS
 SG_ ICC_PosnIdx : 31|2@0+ (1,0) [0|3] ""  ADAS
 SG_ ICC_PosnSpd : 40|9@0+ (0.2,-12.8) [-12.8|89.2] "m/s"  ADAS
 SG_ ICC_PosnCurLane : 43|3@0+ (1,0) [0|7] ""  ADAS
 SG_ ICC_PosnPosConfdc : 46|3@0+ (1,0) [0|7] ""  ADAS
 SG_ ICC_PosnRehead : 63|8@0+ (1.417,0) [0|358.583] "degrees"  ADAS

BO_ 866 ICC_0x362: 8 GW
 SG_ ICC_MetaCountryCode : 1|10@0+ (1,0) [0|1023] ""  ADAS,FCM
 SG_ ICC_MetaMapProvider : 4|3@0+ (1,0) [0|7] "m"  ADAS
 SG_ ICC_MetaMsgType : 7|3@0+ (1,0) [0|7] ""  ADAS
 SG_ ICC_MetaHwVer : 16|9@0+ (1,0) [0|511] ""  ADAS
 SG_ ICC_MetaProtVerMinorSub : 19|3@0+ (1,0) [0|7] ""  ADAS
 SG_ ICC_MetaProtVerMajor : 21|2@0+ (1,0) [0|3] ""  ADAS
 SG_ ICC_MetaCycCnt : 23|2@0+ (1,0) [0|3] ""  ADAS
 SG_ ICC_MetaRegionCode : 38|15@0+ (1,0) [0|32767] ""  ADAS,FCM
 SG_ ICC_MetaDrvSide : 39|1@0+ (1,0) [0|1] ""  ADAS
 SG_ ICC_MetaMapVerYear : 53|6@0+ (1,2000) [2000|2063] ""  ADAS
 SG_ ICC_MetaMapVerQtr : 55|2@0+ (1,1) [1|3] ""  ADAS
 SG_ ICC_MetaProtVerMinor : 59|4@0+ (1,0) [0|15] ""  ADAS
 SG_ ICC_MetaSpdUnits : 60|1@0+ (1,0) [0|1] ""  ADAS
 SG_ ICC_Reserved : 63|3@0+ (1,0) [0|7] ""  ADAS

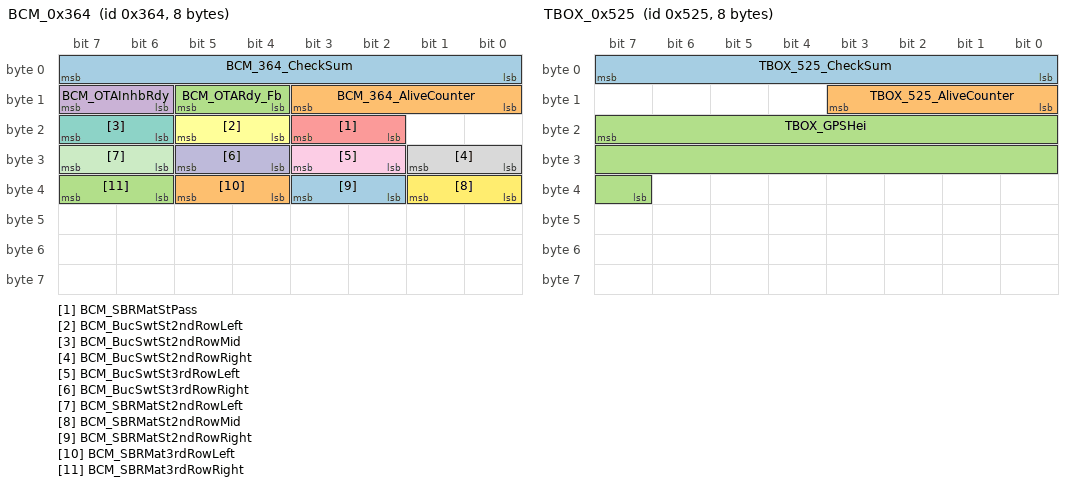
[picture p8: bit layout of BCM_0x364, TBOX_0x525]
BO_ 868 BCM_0x364: 8 GW
 SG_ BCM_364_CheckSum : 7|8@0+ (1,0) [0|255] ""  ADASBUS_Virtual_ECU
 SG_ BCM_364_AliveCounter : 11|4@0+ (1,0) [0|14] ""  ADASBUS_Virtual_ECU
 SG_ BCM_OTARdy_Fb : 13|2@0+ (1,0) [0|3] ""  ADASBUS_Virtual_ECU
 SG_ BCM_OTAInhbRdy : 15|2@0+ (1,0) [0|3] ""  ADASBUS_Virtual_ECU
 SG_ BCM_SBRMatStPass : 19|2@0+ (1,0) [0|3] ""  PKC
 SG_ BCM_BucSwtSt2ndRowLeft : 21|2@0+ (1,0) [0|3] ""  ADAS
 SG_ BCM_BucSwtSt2ndRowMid : 23|2@0+ (1,0) [0|3] ""  ADAS
 SG_ BCM_BucSwtSt2ndRowRight : 25|2@0+ (1,0) [0|3] ""  ADAS
 SG_ BCM_BucSwtSt3rdRowLeft : 27|2@0+ (1,0) [0|3] ""  ADASBUS_Virtual_ECU
 SG_ BCM_BucSwtSt3rdRowRight : 29|2@0+ (1,0) [0|3] ""  ADASBUS_Virtual_ECU
 SG_ BCM_SBRMatSt2ndRowLeft : 31|2@0+ (1,0) [0|3] ""  ADAS,PKC
 SG_ BCM_SBRMatSt2ndRowMid : 33|2@0+ (1,0) [0|3] ""  ADAS,PKC
 SG_ BCM_SBRMatSt2ndRowRight : 35|2@0+ (1,0) [0|3] ""  ADAS,PKC
 SG_ BCM_SBRMat3rdRowLeft : 37|2@0+ (1,0) [0|3] ""  ADAS
 SG_ BCM_SBRMat3rdRowRight : 39|2@0+ (1,0) [0|3] ""  ADAS

BO_ 883 ECC_0x373: 8 GW
 SG_ ECC_CrtSts : 3|4@0+ (1,0) [0|15] ""  ADASBUS_Virtual_ECU
 SG_ ECC_IninSts : 4|1@0+ (1,0) [0|1] ""  ADASBUS_Virtual_ECU
 SG_ ECC_PwrSysHeatMngtSts : 6|2@0+ (1,0) [0|3] ""  ADASBUS_Virtual_ECU
 SG_ ECC_ACSts : 7|1@0+ (1,0) [0|1] ""  ADASBUS_Virtual_ECU
 SG_ ECC_AirClnSts : 8|1@0+ (1,0) [0|1] ""  ADASBUS_Virtual_ECU
 SG_ ECC_WindSpdSts : 12|4@0+ (1,0) [0|15] ""  ADAS,FCM
 SG_ ECC_BackRowAirOutlModSts : 15|3@0+ (1,0) [0|7] ""  ADASBUS_Virtual_ECU
 SG_ ECC_DrvrTSetSts : 23|8@0+ (0.5,0) [0|127.5] ""  ADASBUS_Virtual_ECU
 SG_ ECC_PassTSetSts : 31|8@0+ (0.5,0) [0|127.5] ""  ADASBUS_Virtual_ECU
 SG_ ECC_HeatSts : 32|1@0+ (1,0) [0|1] ""  ADASBUS_Virtual_ECU
 SG_ ECC_AUTOSts : 33|1@0+ (1,0) [0|1] ""  ADASBUS_Virtual_ECU
 SG_ ECC_SYNCSts : 34|1@0+ (1,0) [0|1] ""  ADASBUS_Virtual_ECU
 SG_ ECC_InfoSysWrmColdDisp : 36|2@0+ (1,0) [0|3] ""  ADASBUS_Virtual_ECU
 SG_ ECC_CircSts : 37|1@0+ (1,0) [0|1] ""  ADASBUS_Virtual_ECU
 SG_ ECC_ParticleConcVld : 39|2@0+ (1,0) [0|3] ""  ADASBUS_Virtual_ECU
 SG_ ECC_OutdT : 47|8@0+ (0.5,-48) [-48|79.5] "Degree Celsius"  ADAS,FCM
 SG_ ECC_OutdTVld : 49|2@0+ (1,0) [0|3] ""  ADAS,FCM
 SG_ ECC_MaxFrntDefrst : 50|1@0+ (1,0) [0|1] ""  ADASBUS_Virtual_ECU
 SG_ ECC_HeatMngtSysFlt : 51|1@0+ (1,0) [0|1] ""  ADASBUS_Virtual_ECU
 SG_ ECC_HeatMngtFctLim : 52|1@0+ (1,0) [0|1] ""  ADASBUS_Virtual_ECU
 SG_ ECC_DrvrAirOutlMod : 55|3@0+ (1,0) [0|7] ""  ADASBUS_Virtual_ECU
 SG_ ECC_PassAirOutlMod : 58|3@0+ (1,0) [0|7] ""  ADASBUS_Virtual_ECU
 SG_ ECC_RemSts : 60|2@0+ (1,0) [0|3] ""  ADASBUS_Virtual_ECU
 SG_ ECC_OTAInhbRdy : 62|2@0+ (1,0) [0|3] ""  ADASBUS_Virtual_ECU

BO_ 1137 PLGM_0x471: 8 GW
 SG_ PLGM_UsrSetTrMaxHei : 7|8@0+ (1,0) [0|255] "%"  ADASBUS_Virtual_ECU
 SG_ PLGM_LeTrPosn : 15|8@0+ (1,0) [0|100] "%"  ADASBUS_Virtual_ECU
 SG_ PLGM_RiTrPosn : 23|8@0+ (1,0) [0|100] "%"  ADASBUS_Virtual_ECU
 SG_ PLGM_LiRemdngReq_BCM : 26|3@0+ (1,0) [0|7] ""  ADASBUS_Virtual_ECU
 SG_ PLGM_SoundRemdngReq_EHU : 29|3@0+ (1,0) [0|7] ""  ADASBUS_Virtual_ECU
 SG_ PLGM_FctEnaRes : 30|1@0+ (1,0) [0|1] ""  ADASBUS_Virtual_ECU
 SG_ PLGM_SysFltIndcn : 31|1@0+ (1,0) [0|1] ""  ADAS
 SG_ PLGM_TrActnHandCmd : 33|2@0+ (1,0) [0|3] ""  ADASBUS_Virtual_ECU
 SG_ PLGM_TrSwtStsIndcn : 36|3@0+ (1,0) [0|7] ""  ADAS,PKC
 SG_ PLGM_TrLtchStsIndcn : 39|3@0+ (1,0) [0|7] ""  ADAS,PKC
 SG_ PLGM_TrSwtTrigOpenReq : 40|1@0+ (1,0) [0|1] ""  PKC
 SG_ PLGM_OperMod : 42|2@0+ (1,0) [0|3] ""  ADASBUS_Virtual_ECU
 SG_ PLGM_TrSwtSts : 43|1@0+ (1,0) [0|1] ""  ADASBUS_Virtual_ECU
 SG_ PLGM_LimpHomeSts : 44|1@0+ (1,0) [0|1] ""  ADASBUS_Virtual_ECU
 SG_ PLGM_DrvrSwtSts : 45|1@0+ (1,0) [0|1] ""  ADASBUS_Virtual_ECU
 SG_ PLGM_TrInnrSwtSts : 47|2@0+ (1,0) [0|3] ""  ADASBUS_Virtual_ECU
 SG_ PLGM_AntipinchSts : 48|1@0+ (1,0) [0|1] ""  ADASBUS_Virtual_ECU
 SG_ PLGM_TrSts : 49|1@0+ (1,0) [0|1] ""  ADAS,PKC
 SG_ PLGM_OTAInhbRdy : 51|2@0+ (1,0) [0|3] ""  ADASBUS_Virtual_ECU
 SG_ PLGM_OTARdy_Fb : 53|2@0+ (1,0) [0|3] ""  ADASBUS_Virtual_ECU
 SG_ PLGM_Tindcn_NTC : 63|8@0+ (1,-40) [-40|100] "Degree Celsius"  ADASBUS_Virtual_ECU

BO_ 1153 ADAS_0x481: 8 ADAS
 SG_ ADAS_ECUUnexpectedRst : 0|1@0+ (1,0) [0|1] ""  GW
 SG_ ADAS_ChkBattVoltFlt : 1|1@0+ (1,0) [0|1] ""  GW
 SG_ ADAS_1V25UnderOrOverVolt : 2|1@0+ (1,0) [0|1] ""  GW
 SG_ ADAS_3V3UnderOrOverVolt : 3|1@0+ (1,0) [0|1] ""  GW
 SG_ ADAS_5V0UnderOrOverVolt : 4|1@0+ (1,0) [0|1] ""  GW
 SG_ ADAS_BusHwErr : 5|1@0+ (1,0) [0|1] ""  GW
 SG_ ADAS_BusHwErr_FCM : 6|1@0+ (1,0) [0|1] ""  GW
 SG_ ADAS_BusHwErr_MRR : 7|1@0+ (1,0) [0|1] ""  GW
 SG_ ADAS_BusHwErr_CMRR_FL : 8|1@0+ (1,0) [0|1] ""  GW
 SG_ ADAS_BusDiagHwErr_CMRR_FR : 9|1@0+ (1,0) [0|1] ""  GW
 SG_ ADAS_ChkInvldSig_FCM : 10|1@0+ (1,0) [0|1] ""  GW
 SG_ ADAS_ChkInvldSig_CMRR_RL : 11|1@0+ (1,0) [0|1] ""  GW
 SG_ ADAS_ChkInvldSig_CMRR_FR : 12|1@0+ (1,0) [0|1] ""  GW
 SG_ ADAS_ChkInvldSig_CMRR_FL : 13|1@0+ (1,0) [0|1] ""  GW
 SG_ ADAS_ChkInvldSig_CMRR_RR : 14|1@0+ (1,0) [0|1] ""  GW
 SG_ ADAS_ChkInvldSig_MRR : 15|1@0+ (1,0) [0|1] ""  GW
 SG_ ADAS_ChkInvldSig_ESP : 16|1@0+ (1,0) [0|1] ""  GW
 SG_ ADAS_ChkInvldSig_ACU : 17|1@0+ (1,0) [0|1] ""  GW
 SG_ ADAS_ChkInvldSig_EPS : 18|1@0+ (1,0) [0|1] ""  GW
 SG_ ADAS_ChkInvldSig_iBooster : 19|1@0+ (1,0) [0|1] ""  GW
 SG_ ADAS_ChkInvldSig_YRS : 20|1@0+ (1,0) [0|1] ""  GW
 SG_ ADAS_ChkInvldSig_BCM : 21|1@0+ (1,0) [0|1] ""  GW
 SG_ ADAS_ChkInvldSig_ECC : 22|1@0+ (1,0) [0|1] ""  GW
 SG_ ADAS_ChkInvldSig_TBOX : 23|1@0+ (1,0) [0|1] ""  GW
 SG_ ADAS_ChkInvldSig_MCU_F : 24|1@0+ (1,0) [0|1] ""  GW
 SG_ ADAS_ChkInvldSig_MCU_R : 25|1@0+ (1,0) [0|1] ""  GW
 SG_ ADAS_ChkInvldSig_PLGM : 26|1@0+ (1,0) [0|1] ""  GW
 SG_ ADAS_ChkInvldSig_CIM : 27|1@0+ (1,0) [0|1] ""  GW
 SG_ ADAS_ChkInvldSig_VCU : 28|1@0+ (1,0) [0|1] ""  GW
 SG_ ADAS_ChkInvldSig_ICC : 29|1@0+ (1,0) [0|1] ""  GW
 SG_ ADAS_ChkInvldSig_PEPS : 30|1@0+ (1,0) [0|1] ""  GW
 SG_ ADAS_ChkInvldSig_TPMS : 31|1@0+ (1,0) [0|1] ""  GW
 SG_ ADAS_ChkInvldSig_AVAP : 32|1@0+ (1,0) [0|1] ""  GW
 SG_ ADAS_ComE2EFlt : 33|1@0+ (1,0) [0|1] ""  GW
 SG_ ADAS_ComLostFlt_FCM : 34|1@0+ (1,0) [0|1] ""  GW
 SG_ ADAS_ComLostFlt_CMRR_RL : 35|1@0+ (1,0) [0|1] ""  GW
 SG_ ADAS_ComLostFlt_CMRR_FL : 36|1@0+ (1,0) [0|1] ""  GW
 SG_ ADAS_ComLostFlt_CMRR_RR : 37|1@0+ (1,0) [0|1] ""  GW
 SG_ ADAS_ComLostFlt_CMRR_FR : 38|1@0+ (1,0) [0|1] ""  GW
 SG_ ADAS_ComLostFlt_MRR : 39|1@0+ (1,0) [0|1] ""  GW
 SG_ ADAS_ComLostFlt_ESP : 40|1@0+ (1,0) [0|1] ""  GW
 SG_ ADAS_ComLostFlt_ACU : 41|1@0+ (1,0) [0|1] ""  GW
 SG_ ADAS_ComLostFlt_EPS : 42|1@0+ (1,0) [0|1] ""  GW
 SG_ ADAS_ComLostFlt_iBooster : 43|1@0+ (1,0) [0|1] ""  GW
 SG_ ADAS_ComLostFlt_YRS : 44|1@0+ (1,0) [0|1] ""  GW
 SG_ ADAS_ComLostFlt_BCM : 45|1@0+ (1,0) [0|1] ""  GW
 SG_ ADAS_ComLostFlt_ECC : 46|1@0+ (1,0) [0|1] ""  GW
 SG_ ADAS_ComLostFlt_TBOX : 47|1@0+ (1,0) [0|1] ""  GW
 SG_ ADAS_ComLostFlt_MCU_F : 48|1@0+ (1,0) [0|1] ""  GW
 SG_ ADAS_ComLostFlt_MCU_R : 49|1@0+ (1,0) [0|1] ""  GW
 SG_ ADAS_ComLostFlt_PLGM : 50|1@0+ (1,0) [0|1] ""  GW
 SG_ ADAS_ComLostFlt_CIM : 51|1@0+ (1,0) [0|1] ""  GW
 SG_ ADAS_ComLostFlt_VCU : 52|1@0+ (1,0) [0|1] ""  GW
 SG_ ADAS_ComLostFlt_ICC : 53|1@0+ (1,0) [0|1] ""  GW
 SG_ ADAS_ComLostFlt_PEPS : 54|1@0+ (1,0) [0|1] ""  GW
 SG_ ADAS_ComLostFlt_TPMS : 55|1@0+ (1,0) [0|1] ""  GW
 SG_ ADAS_ComLostFlt_AVAP : 56|1@0+ (1,0) [0|1] ""  GW
 SG_ ADAS_ChkPublicCANBusOff : 57|1@0+ (1,0) [0|1] ""  GW
 SG_ ADAS_MstRAMTestErr : 58|1@0+ (1,0) [0|1] ""  GW
 SG_ ADAS_MstNVRAMTestErr : 59|1@0+ (1,0) [0|1] ""  GW
 SG_ ADAS_NVMChipErr : 60|1@0+ (1,0) [0|1] ""  GW
 SG_ ADAS_NVMStructErr : 61|1@0+ (1,0) [0|1] ""  GW
 SG_ ADAS_MstWdgErr : 62|1@0+ (1,0) [0|1] ""  GW
 SG_ ADAS_MstSOPTErr : 63|1@0+ (1,0) [0|1] ""  GW

BO_ 1154 ADAS_0x482: 8 ADAS
 SG_ ADAS_MstHwstartupErr : 0|1@0+ (1,0) [0|1] ""  GW
 SG_ ADAS_MstHwCycTest : 1|1@0+ (1,0) [0|1] ""  GW
 SG_ ADAS_EOLCalOutOfRng : 2|1@0+ (1,0) [0|1] ""  GW
 SG_ ADAS_ECUTFlt : 3|1@0+ (1,0) [0|1] ""  GW
 SG_ ADAS_PwrModFlt : 4|1@0+ (1,0) [0|1] ""  GW
 SG_ ADAS_ComLostFlt_MFS : 5|1@0+ (1,0) [0|1] ""  GW
 SG_ ADAS_PrivateCANComE2EFlt_FCM : 6|1@0+ (1,0) [0|1] ""  GW
 SG_ ADAS_PrivateCANComE2EFlt_MRR : 7|1@0+ (1,0) [0|1] ""  GW
 SG_ ADAS_PrivateCANComE2EFlt_CMRR_FL : 8|1@0+ (1,0) [0|1] ""  GW
 SG_ ADAS_PrivateCANComE2EFlt_CMRR_FR : 9|1@0+ (1,0) [0|1] ""  GW
 SG_ ADAS_PrivateCANComE2EFlt_CMRR_RL : 10|1@0+ (1,0) [0|1] ""  GW
 SG_ ADAS_PrivateCANComE2EFlt_CMRR_RR : 11|1@0+ (1,0) [0|1] ""  GW
 SG_ ADAS_PrivateCANComLostFlt_FCM : 12|1@0+ (1,0) [0|1] ""  GW
 SG_ ADAS_PrivateCANComLostFlt_MRR : 13|1@0+ (1,0) [0|1] ""  GW
 SG_ ADAS_PrivateCANComLost_CMRR_FL : 14|1@0+ (1,0) [0|1] ""  GW
 SG_ ADAS_PrivateCANComLost_CMRR_FR : 15|1@0+ (1,0) [0|1] ""  GW
 SG_ ADAS_PrivateCANComLost_CMRR_RL : 16|1@0+ (1,0) [0|1] ""  GW
 SG_ ADAS_PrivateCANComLost_CMRR_RR : 17|1@0+ (1,0) [0|1] ""  GW
 SG_ ADAS_PERChkIntFltInfo : 18|1@0+ (1,0) [0|1] ""  GW
 SG_ ADAS_HWAActvFlg : 19|1@0+ (1,0) [0|1] ""  GW
 SG_ ADAS_HWASucFlg : 20|1@0+ (1,0) [0|1] ""  GW

BO_ 1159 FCM_0x487: 8 FCM
 SG_ FCM_ComLostFlt_ESP : 0|1@0+ (1,0) [0|1] ""  GW
 SG_ FCM_ComLostFlt_iBooster : 1|1@0+ (1,0) [0|1] ""  GW
 SG_ FCM_ComLostFlt_EPS : 2|1@0+ (1,0) [0|1] ""  GW
 SG_ FCM_ComLostFlt_YRS : 3|1@0+ (1,0) [0|1] ""  GW
 SG_ FCM_ComLostFlt_BCM : 4|1@0+ (1,0) [0|1] ""  GW
 SG_ FCM_ComLostFlt_ECC : 5|1@0+ (1,0) [0|1] ""  GW
 SG_ FCM_ComLostFlt_TBOX : 6|1@0+ (1,0) [0|1] ""  GW
 SG_ FCM_ComLostFlt_CIM : 7|1@0+ (1,0) [0|1] ""  GW
 SG_ FCM_ComLostFlt_ICC : 8|1@0+ (1,0) [0|1] ""  GW
 SG_ FCM_ComLostFlt_MRR : 9|1@0+ (1,0) [0|1] ""  GW
 SG_ FCM_ComLostFlt_PEPS : 10|1@0+ (1,0) [0|1] ""  GW
 SG_ FCM_ComLostFlt_ADAS : 11|1@0+ (1,0) [0|1] ""  GW
 SG_ FCM_ComE2EFlt : 12|1@0+ (1,0) [0|1] ""  GW
 SG_ FCM_ChkInvldSig_ESP : 13|1@0+ (1,0) [0|1] ""  GW
 SG_ FCM_ChkInvldSig_iBooster : 14|1@0+ (1,0) [0|1] ""  GW
 SG_ FCM_ChkInvldSig_EPS : 15|1@0+ (1,0) [0|1] ""  GW
 SG_ FCM_ChkInvldSig_YRS : 16|1@0+ (1,0) [0|1] ""  GW
 SG_ FCM_ChkInvldSig_CIM : 17|1@0+ (1,0) [0|1] ""  GW
 SG_ FCM_ChkInvldSig_ECC : 18|1@0+ (1,0) [0|1] ""  GW
 SG_ FCM_ChkInvldSig_PEPS : 19|1@0+ (1,0) [0|1] ""  GW
 SG_ FCM_ChkInvldSig_ICC : 20|1@0+ (1,0) [0|1] ""  GW
 SG_ FCM_ChkPrivateCANBusOff : 21|1@0+ (1,0) [0|1] ""  GW
 SG_ FCM_ChkPublicCANBusOff : 22|1@0+ (1,0) [0|1] ""  GW
 SG_ FCM_BattVoltBelowThd : 23|1@0+ (1,0) [0|1] ""  GW
 SG_ FCM_BattVoltOverThd : 24|1@0+ (1,0) [0|1] ""  GW
 SG_ FCM_CamBli : 25|1@0+ (1,0) [0|1] ""  GW
 SG_ FCM_ECUTmpHiTProtn : 26|1@0+ (1,0) [0|1] ""  GW
 SG_ FCM_IntCircOutpVoltBelowThd : 27|1@0+ (1,0) [0|1] ""  GW
 SG_ FCM_IntCircOutpVoltOverThd : 28|1@0+ (1,0) [0|1] ""  GW
 SG_ FCM_IntCircPrmntFlt : 29|1@0+ (1,0) [0|1] ""  GW
 SG_ FCM_MatchParaErr : 30|1@0+ (1,0) [0|1] ""  GW
 SG_ FCM_VehCfgInfoErr : 31|1@0+ (1,0) [0|1] ""  GW
 SG_ FCM_IntCircFlt : 32|1@0+ (1,0) [0|1] ""  GW
 SG_ FCM_DLCFlt_ESP : 33|1@0+ (1,0) [0|1] ""  GW
 SG_ FCM_DLCFlt_iBooster : 34|1@0+ (1,0) [0|1] ""  GW
 SG_ FCM_DLCFlt_EPS : 35|1@0+ (1,0) [0|1] ""  GW
 SG_ FCM_DLCFlt_YRS : 36|1@0+ (1,0) [0|1] ""  GW
 SG_ FCM_DLCFlt_BCM : 37|1@0+ (1,0) [0|1] ""  GW
 SG_ FCM_DLCFlt_ECC : 38|1@0+ (1,0) [0|1] ""  GW
 SG_ FCM_DLCFlt_TBOX : 39|1@0+ (1,0) [0|1] ""  GW
 SG_ FCM_DLCFlt_CIM : 40|1@0+ (1,0) [0|1] ""  GW
 SG_ FCM_DLCFlt_ICC : 41|1@0+ (1,0) [0|1] ""  GW
 SG_ FCM_DLCFlt_MRR : 42|1@0+ (1,0) [0|1] ""  GW
 SG_ FCM_DLCFlt_PEPS : 43|1@0+ (1,0) [0|1] ""  GW
 SG_ FCM_DLCFlt_ADAS : 44|1@0+ (1,0) [0|1] ""  GW
 SG_ FCM_OnlineCalOutOfRng : 45|1@0+ (1,0) [0|1] ""  GW
 SG_ FCM_IniCalOutOfRng : 46|1@0+ (1,0) [0|1] ""  GW
 SG_ FCM_IniCalTimeout : 47|1@0+ (1,0) [0|1] ""  GW
 SG_ FCM_NotCal : 48|1@0+ (1,0) [0|1] ""  GW
 SG_ FCM_OTARdy_Fb : 55|2@0+ (1,0) [0|3] ""  GW

BO_ 1300 MFS_0x514: 8 GW
 SG_ MFS_0x514_CheckSum : 7|8@0+ (1,0) [0|255] ""  ADAS
 SG_ MFS_0x514_AliveCounter : 11|4@0+ (1,0) [0|14] ""  ADAS
 SG_ MFS_LeBtnNorth : 13|2@0+ (1,0) [0|3] ""  ADAS
 SG_ MFS_LeBtnSouth : 15|2@0+ (1,0) [0|3] ""  ADAS
 SG_ MFS_LeBtnWest : 17|2@0+ (1,0) [0|3] ""  ADAS
 SG_ MFS_LeBtnEast : 19|2@0+ (1,0) [0|3] ""  ADAS
 SG_ MFS_LeRollUp : 22|3@0+ (1,0) [0|7] ""  ADAS
 SG_ MFS_LeRollDwn : 26|3@0+ (1,0) [0|7] ""  ADAS
 SG_ MFS_LeRollPress : 28|2@0+ (1,0) [0|3] ""  ADAS
 SG_ MFS_RiBtnNorth : 30|2@0+ (1,0) [0|3] ""  ADAS
 SG_ MFS_RiBtnSouth : 33|2@0+ (1,0) [0|3] ""  ADAS
 SG_ MFS_RiBtnWest : 35|2@0+ (1,0) [0|3] ""  ADAS
 SG_ MFS_RiBtnEast : 37|2@0+ (1,0) [0|3] ""  ADAS
 SG_ MFS_RiRollUp : 42|3@0+ (1,0) [0|7] ""  ADAS
 SG_ MFS_RiRollDwn : 45|3@0+ (1,0) [0|7] ""  ADAS
 SG_ MFS_RiRollPress : 47|2@0+ (1,0) [0|3] ""  ADAS
 SG_ MFS_Ri_Fail : 49|2@0+ (1,0) [0|3] ""  ADAS
 SG_ MFS_Le_Fail : 51|2@0+ (1,0) [0|3] ""  ADASBUS_Virtual_ECU

BO_ 1317 TBOX_0x525: 8 GW
 SG_ TBOX_525_CheckSum : 7|8@0+ (1,0) [0|255] ""  ADAS
 SG_ TBOX_525_AliveCounter : 11|4@0+ (1,0) [0|14] ""  ADAS
 SG_ TBOX_GPSHei : 23|17@0+ (0.1,-500) [-500|8000] "m"  ADAS

BO_ 1318 TBOX_0x526: 8 GW
 SG_ TBOX_GPSLongi : 7|32@0+ (1E-006,-180) [-180|179.999999] "deg"  ADAS
 SG_ TBOX_GPSLati : 39|32@0+ (1E-006,-90) [-90|90] "deg"  ADAS

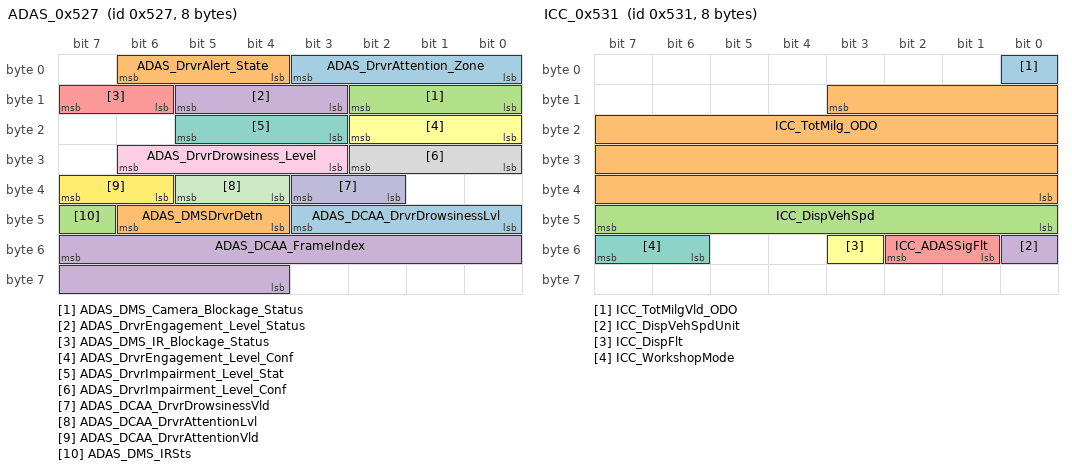
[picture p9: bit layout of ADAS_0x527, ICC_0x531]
BO_ 1319 ADAS_0x527: 8 ADAS
 SG_ ADAS_DrvrAttention_Zone : 3|4@0+ (1,0) [0|15] ""  GW
 SG_ ADAS_DrvrAlert_State : 6|3@0+ (1,0) [0|7] ""  GW
 SG_ ADAS_DMS_Camera_Blockage_Status : 10|3@0+ (1,0) [0|7] ""  GW
 SG_ ADAS_DrvrEngagement_Level_Status : 13|3@0+ (1,0) [0|7] ""  GW
 SG_ ADAS_DMS_IR_Blockage_Status : 15|2@0+ (1,0) [0|3] ""  GW
 SG_ ADAS_DrvrEngagement_Level_Conf : 18|3@0+ (1,0) [0|7] ""  GW
 SG_ ADAS_DrvrImpairment_Level_Stat : 21|3@0+ (1,0) [0|7] ""  GW
 SG_ ADAS_DrvrImpairment_Level_Conf : 26|3@0+ (1,0) [0|7] ""  GW
 SG_ ADAS_DrvrDrowsiness_Level : 30|4@0+ (1,0) [0|15] ""  GW
 SG_ ADAS_DCAA_DrvrDrowsinessVld : 35|2@0+ (1,0) [0|3] ""  GW
 SG_ ADAS_DCAA_DrvrAttentionLvl : 37|2@0+ (1,0) [0|3] ""  GW
 SG_ ADAS_DCAA_DrvrAttentionVld : 39|2@0+ (1,0) [0|3] ""  GW
 SG_ ADAS_DCAA_DrvrDrowsinessLvl : 43|4@0+ (1,0) [0|15] ""  GW
 SG_ ADAS_DMSDrvrDetn : 46|3@0+ (1,0) [0|7] ""  GW
 SG_ ADAS_DMS_IRSts : 47|1@0+ (1,0) [0|1] ""  GW
 SG_ ADAS_DCAA_FrameIndex : 55|12@0+ (1,0) [0|4095] ""  GW

BO_ 1322 ICC_0x52A: 8 GW
 SG_ ICC_0x52A_CheckSum : 7|8@0+ (1,0) [0|255] ""  ADAS,FCM
 SG_ ICC_0x52A_AliveCounter : 11|4@0+ (1,0) [0|14] ""  ADAS,FCM
 SG_ ICC_FACM_DynmcSenstvty : 12|1@0+ (1,0) [0|1] ""  ADAS
 SG_ ICC_UsrProfTiGapSet : 15|3@0+ (1,0) [0|7] ""  ADAS
 SG_ ICC_LKA_Setting : 17|2@0+ (1,0) [0|3] ""  ADAS
 SG_ ICC_FACM_Setting : 19|2@0+ (1,0) [0|3] ""  ADAS
 SG_ ICC_AEB_Sensitivity : 21|2@0+ (1,0) [0|3] ""  ADAS,FCM
 SG_ ICC_BACM_Setting : 23|2@0+ (1,0) [0|3] ""  ADAS
 SG_ ICC_BACM_Sensitivity : 25|2@0+ (1,0) [0|3] ""  ADAS
 SG_ ICC_AEB_JerkSetReq : 27|2@0+ (1,0) [0|3] ""  ADAS
 SG_ ICC_ActvStyGlblSetting : 28|1@0+ (1,0) [0|1] ""  ADAS
 SG_ ICC_TSR_Setting : 29|1@0+ (1,0) [0|1] ""  ADAS
 SG_ ICC_ESA_Setting : 30|1@0+ (1,0) [0|1] ""  ADAS
 SG_ ICC_ELKASteeringInterventionSet : 31|1@0+ (1,0) [0|1] ""  ADAS
 SG_ ICC_LaneTrajectorySetting : 32|1@0+ (1,0) [0|1] ""  ADAS
 SG_ ICC_ACCSwt : 34|2@0+ (1,0) [0|3] ""  ADAS
 SG_ ICC_ACCAutoSpdSts : 35|1@0+ (1,0) [0|1] ""  ADAS
 SG_ ICC_ACCSpdStepSize : 36|1@0+ (1,0) [0|1] ""  ADAS
 SG_ ICC_ACCFuncTyp : 39|3@0+ (1,0) [0|7] ""  ADAS
 SG_ ICC_ACCSpdLimOffs : 45|6@0+ (0.5,0) [0|31.5] ""  ADAS
 SG_ ICC_ACCSpdLimOffsTyp : 47|2@0+ (1,0) [0|3] ""  ADAS
 SG_ ICC_ACCTerrainSetting : 48|1@0+ (1,0) [0|1] ""  ADAS
 SG_ ICC_ACCTiGapCfm : 51|2@0+ (1,0) [0|3] ""  ADAS
 SG_ ICC_ISASetting : 54|3@0+ (1,0) [0|7] ""  ADAS
 SG_ ICC_FCTA_Sensitivity : 57|2@0+ (1,0) [0|3] ""  ADAS
 SG_ ICC_ISAWarnStopReq : 58|1@0+ (1,0) [0|1] ""  ADAS
 SG_ ICC_TLR_Setting : 61|3@0+ (1,0) [0|7] ""  ADAS
 SG_ ICC_FCTA_Setting : 63|2@0+ (1,0) [0|3] ""  ADAS

BO_ 1329 ICC_0x531: 8 GW
 SG_ ICC_TotMilgVld_ODO : 0|1@0+ (1,0) [0|1] ""  ADAS,FCM,PKC
 SG_ ICC_TotMilg_ODO : 11|28@0+ (0.01,0) [0|2000000] "km"  ADAS,FCM,PKC
 SG_ ICC_DispVehSpd : 47|8@0+ (1,0) [0|255] ""  ADAS,FCM,PKC
 SG_ ICC_DispVehSpdUnit : 48|1@0+ (1,0) [0|1] ""  ADAS,FCM,PKC
 SG_ ICC_ADASSigFlt : 50|2@0+ (1,0) [0|3] ""  ADAS,FCM,PKC
 SG_ ICC_DispFlt : 51|1@0+ (1,0) [0|1] ""  ADAS,FCM,PKC
 SG_ ICC_WorkshopMode : 55|2@0+ (1,0) [0|3] ""  ADAS

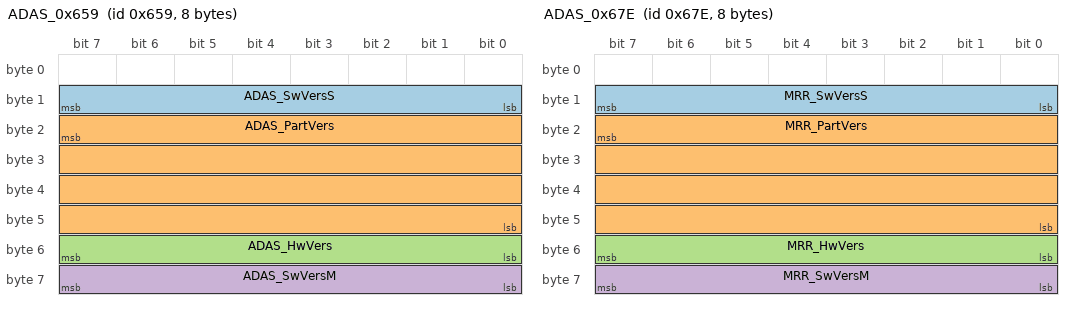
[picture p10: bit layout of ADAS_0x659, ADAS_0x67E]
BO_ 1625 ADAS_0x659: 8 ADAS
 SG_ ADAS_SwVersS : 15|8@0+ (1,0) [0|255] ""  GW
 SG_ ADAS_PartVers : 23|32@0+ (1,0) [0|4294967295] ""  GW
 SG_ ADAS_HwVers : 55|8@0+ (1,0) [0|255] ""  GW
 SG_ ADAS_SwVersM : 63|8@0+ (1,0) [0|255] ""  GW

BO_ 1662 ADAS_0x67E: 8 ADAS
 SG_ MRR_SwVersS : 15|8@0+ (1,0) [0|255] ""  GW
 SG_ MRR_PartVers : 23|32@0+ (1,0) [0|4294967295] ""  GW
 SG_ MRR_HwVers : 55|8@0+ (1,0) [0|255] ""  GW
 SG_ MRR_SwVersM : 63|8@0+ (1,0) [0|255] ""  GW

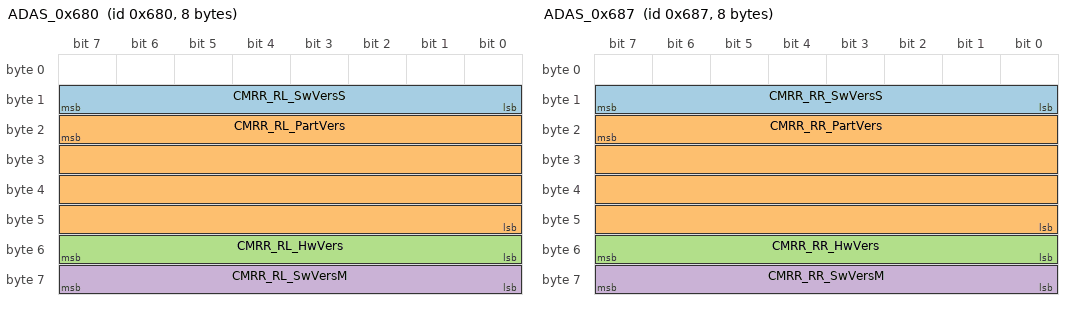
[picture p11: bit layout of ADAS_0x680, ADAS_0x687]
BO_ 1664 ADAS_0x680: 8 ADAS
 SG_ CMRR_RL_SwVersS : 15|8@0+ (1,0) [0|255] ""  GW
 SG_ CMRR_RL_PartVers : 23|32@0+ (1,0) [0|4294967295] ""  GW
 SG_ CMRR_RL_HwVers : 55|8@0+ (1,0) [0|255] ""  GW
 SG_ CMRR_RL_SwVersM : 63|8@0+ (1,0) [0|255] ""  GW

BO_ 1671 ADAS_0x687: 8 ADAS
 SG_ CMRR_RR_SwVersS : 15|8@0+ (1,0) [0|255] ""  GW
 SG_ CMRR_RR_PartVers : 23|32@0+ (1,0) [0|4294967295] ""  GW
 SG_ CMRR_RR_HwVers : 55|8@0+ (1,0) [0|255] ""  GW
 SG_ CMRR_RR_SwVersM : 63|8@0+ (1,0) [0|255] ""  GW

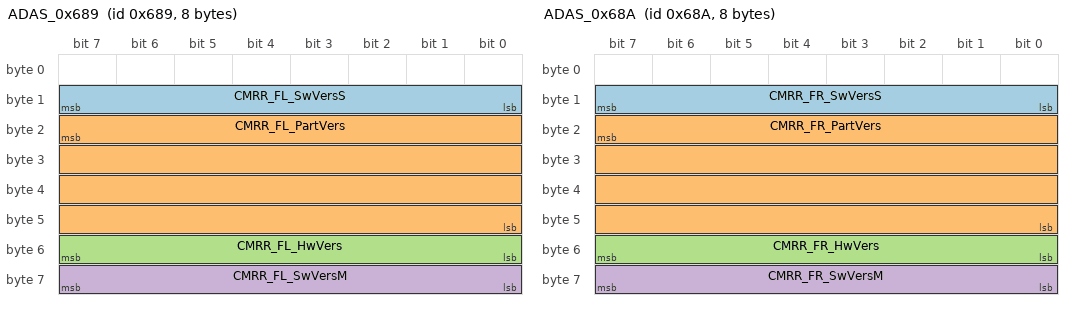
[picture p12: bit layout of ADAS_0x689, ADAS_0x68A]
BO_ 1673 ADAS_0x689: 8 ADAS
 SG_ CMRR_FL_SwVersS : 15|8@0+ (1,0) [0|255] ""  GW
 SG_ CMRR_FL_PartVers : 23|32@0+ (1,0) [0|4294967295] ""  GW
 SG_ CMRR_FL_HwVers : 55|8@0+ (1,0) [0|255] ""  GW
 SG_ CMRR_FL_SwVersM : 63|8@0+ (1,0) [0|255] ""  GW

BO_ 1674 ADAS_0x68A: 8 ADAS
 SG_ CMRR_FR_SwVersS : 15|8@0+ (1,0) [0|255] ""  GW
 SG_ CMRR_FR_PartVers : 23|32@0+ (1,0) [0|4294967295] ""  GW
 SG_ CMRR_FR_HwVers : 55|8@0+ (1,0) [0|255] ""  GW
 SG_ CMRR_FR_SwVersM : 63|8@0+ (1,0) [0|255] ""  GW

BA_DEF_ BO_  "GenMsgSendType" ENUM  "Cyclic","NotUsed","NotUsed","NotUsed","NotUsed","NotUsed","NotUsed","IfActive","NoMsgSendType";
BA_DEF_ BO_  "GenMsgCycleTime" INT 0 0;
BA_DEF_ SG_  "GenSigSendType" ENUM  "Cyclic","OnWrite","OnWriteWithRepetition","OnChange","OnChangeWithRepetition","IfActive","IfActiveWithRepetition","NoSigSendType";
BA_DEF_ BO_  "CANFD_BRS" ENUM  "0","1";
BA_DEF_ BO_  "VFrameFormat" ENUM  "StandardCAN","ExtendedCAN","reserved","reserved","reserved","reserved","reserved","reserved","reserved","reserved","reserved","reserved","reserved","reserved","StandardCAN_FD","ExtendedCAN_FD";
BA_DEF_ BO_  "GenMsgILSupport" ENUM  "No","Yes";
BA_DEF_DEF_  "GenMsgSendType" "Cyclic";
BA_DEF_DEF_  "GenMsgCycleTime" 0;
BA_DEF_DEF_  "GenSigSendType" "Cyclic";
BA_DEF_DEF_  "CANFD_BRS" "1";
BA_DEF_DEF_  "VFrameFormat" "StandardCAN";
BA_DEF_DEF_  "GenMsgILSupport" "Yes";
CM_ SG_ 821 BCM_335_CheckSum "BCM_335_Message checksum ( 0xD4)BCM_335_CheckSum";
CM_ SG_ 821 BCM_335_AliveCounter "BC_335_Message counterBCM_335_AliveCounter";
CM_ SG_ 821 BCM_WiprInSrvPosn "Whether the electronic wiper is in the service position";
CM_ SG_ 821 BCM_IntLampTiSetSts "Central control interior lamp door control delay time setting state";
CM_ SG_ 821 BCM_WaterPosnSnsrSwtSts "Condition of level sensor switch";
CM_ SG_ 821 BCM_FrntFogLampOutpCmd "Front fog lamp output command";
CM_ SG_ 821 BCM_LicPlateLampOutpCmd "License plate lamp output command";
CM_ SG_ 821 BCM_EnaSts_ADB "ADB enable";
CM_ SG_ 821 BCM_PwrSaveOutpCmd "Power saving output command";
CM_ SG_ 821 BCM_ExtLampSwtSts "Outside lamp switch status";
CM_ SG_ 821 BCM_HornOutpCmd "Horn output command";
CM_ SG_ 821 BCM_HornSwtSts "Horn switch state";
CM_ SG_ 821 BCM_WelLampOutpCmd "Approach lamp output command";
CM_ SG_ 821 BCM_FolwMeHomeSts "Follow me home state";
CM_ SG_ 821 BCM_FrntFogLampSwtSts "Front fog lamp switch state";
CM_ SG_ 821 BCM_ReFogLampSwtSts "Rear fog lamp switch state";
CM_ SG_ 821 BCM_ReWiprBackSwtSts "State of rear wiper return switch";
CM_ SG_ 821 BCM_RainClsSunroofSetSts "Central control screen closing sunroof setting state in rainy days";
CM_ SG_ 821 BCM_MirrLockAutoSetSts "Central control rearview mirror locking automatic folding setting state";
CM_ SG_ 821 BCM_FrntWshrOutpCmd "Front washing output command";
CM_ SG_ 821 BCM_DangerAlrmLampSwtSts "Hazard warning lamp switch state";
CM_ SG_ 821 BCM_ReDefrstHeatgCmd "Rear defrosting heating command";
CM_ SG_ 821 BCM_RvsLampOutpCmd "Reverse lamp output command";
CM_ SG_ 821 BCM_IntLampOutpCmd "Output state of internal lamp";
CM_ SG_ 821 BCM_LeTrunLampOutpCmd "Left turn signal lamp output command";
CM_ SG_ 821 BCM_RiTrunLampOutpCmd "Right turn signal lamp output command";
CM_ SG_ 821 BCM_ReWiprOutpCmd "Rear wiper output command";
CM_ SG_ 821 BCM_ReWshrOutpCmd "Rear washer output command";
CM_ SG_ 821 BCM_BrkLampSwtSts "Brake lamp switch state";
CM_ SG_ 821 BCM_HiBeamOutpCmd "High beam output command";
CM_ SG_ 821 BCM_LoBeamOutpCmd "Low beam output command";
CM_ SG_ 821 BCM_PosnLampOutpCmd "Position lamp output command";
CM_ SG_ 821 BCM_BrkLampOutpCmd "Brake lamp output command";
CM_ SG_ 821 BCM_ReFogLampOutpCmd "Rear fog lamp output command";
CM_ SG_ 821 BCM_FrntWiprSpd "Front wiper speed";
CM_ SG_ 821 BCM_EnaReq_ADB "ADB enable state feedback";
CM_ SG_ 821 BCM_VehAmbBri "Ambient light detection value output";
CM_ SG_ 825 ADAS_LeLine1Crvt "Real left lane 1 curvature (observed)";
CM_ SG_ 825 ADAS_LeLine1Offset "offset of the left lane line 1";
CM_ SG_ 825 ADAS_LeLine1LnColor "Real left lane line 1 color (observation)";
CM_ SG_ 825 ADAS_LeLine1Hdng "Heading of the left lane line 1";
CM_ SG_ 825 ADAS_LeLine1LnTyp "True left lane line 1 type (observed)";
CM_ SG_ 825 ADAS_LeLine1CrvtRt "Rate of curvature of the left lane line 1";
CM_ SG_ 825 ADAS_LeLine1Conf "Left lane line 1 confidence";
CM_ SG_ 827 ADAS_Obj1_ID "Object identifier. If ID is 0x0 no object is detected";
CM_ SG_ 827 ADAS_Obj1_LongDist "Object Longitudinal distance (0.2 m/bit measured on the car; the matrix says 0.5)";
CM_ SG_ 827 ADAS_Obj1_LatDist "Object Latitudinal distance (0.2 m/bit measured on the car; the matrix says 0.5)";
CM_ SG_ 827 ADAS_Obj1_Width "Object Width";
CM_ SG_ 827 ADAS_Obj1_Conf "Object Confidence level";
CM_ SG_ 827 ADAS_Obj1_Length "Object length";
CM_ SG_ 827 ADAS_VVP_ICC_Obj1Hdng "Object 1 Heading Angle";
CM_ SG_ 827 ADAS_Obj1_Height "Object height";
CM_ SG_ 827 ADAS_Obj1_LongDistSign "Object longitudinal Distance Signal";
CM_ SG_ 827 ADAS_Obj1_LatDistSign "Object Latitudinal Distance Signal";
CM_ SG_ 827 ADAS_Obj1_Classification "Object Calssification";
CM_ SG_ 827 ADAS_VVP_ICC_Obj1BrkLght "Object 1 brake light on / off";
CM_ SG_ 827 ADAS_Obj1_ClassConf "Object Classification Confidence";
CM_ SG_ 829 ADAS_Obj4_ID "Object identifier. If ID is 0x0 no object is detected";
CM_ SG_ 829 ADAS_Obj4_LongDist "Object Longitudinal distance (0.2 m/bit measured on the car; the matrix says 0.5)";
CM_ SG_ 829 ADAS_Obj4_LatDist "Object Latitudinal distance (0.2 m/bit measured on the car; the matrix says 0.5)";
CM_ SG_ 829 ADAS_Obj4_Width "Object Width";
CM_ SG_ 829 ADAS_Obj4_Conf "Object Confidence level";
CM_ SG_ 829 ADAS_Obj4_Length "Object length";
CM_ SG_ 829 ADAS_VVP_ICC_Obj4Hdng "Object 4 Heading Angle";
CM_ SG_ 829 ADAS_Obj4_Height "Object height";
CM_ SG_ 829 ADAS_Obj4_LongDistSign "Object longitudinal Distance Signal";
CM_ SG_ 829 ADAS_Obj4_LatDistSign "Object Latitudinal Distance Signal";
CM_ SG_ 829 ADAS_Obj4_Classification "Object Calssification";
CM_ SG_ 829 ADAS_VVP_ICC_Obj4BrkLght "Object 4 brake light on / off";
CM_ SG_ 829 ADAS_Obj4_ClassConf "Object Classification Confidence";
CM_ SG_ 831 ADAS_Obj7_ID "Object identifier. If ID is 0x0 no object is detected";
CM_ SG_ 831 ADAS_Obj7_LongDist "Object Longitudinal distance (0.2 m/bit measured on the car; the matrix says 0.5)";
CM_ SG_ 831 ADAS_Obj7_LatDist "Object Latitudinal distance (0.2 m/bit measured on the car; the matrix says 0.5)";
CM_ SG_ 831 ADAS_Obj7_Width "Object Width";
CM_ SG_ 831 ADAS_Obj7_Conf "Object Confidence level";
CM_ SG_ 831 ADAS_Obj7_Length "Object length";
CM_ SG_ 831 ADAS_VVP_ICC_Obj7Hdng "Object 7 Heading Angle";
CM_ SG_ 831 ADAS_Obj7_Height "Object height";
CM_ SG_ 831 ADAS_Obj7_LongDistSign "Object longitudinal Distance Signal";
CM_ SG_ 831 ADAS_Obj7_LatDistSign "Object Latitudinal Distance Signal";
CM_ SG_ 831 ADAS_Obj7_Classification "Object Calssification";
CM_ SG_ 831 ADAS_VVP_ICC_Obj7BrkLght "Object 7 brake light on / off";
CM_ SG_ 831 ADAS_Obj7_ClassConf "Object Classification Confidence";
CM_ SG_ 832 ADAS_340_Checksum "ADAS_340_Message checksum ( E2E data ID: 0x32)";
CM_ SG_ 832 ADAS_340_AliveCounter "ADAS340_Message CounterADAS_340_AliveCounter";
CM_ SG_ 832 ADAS_LeLineColor "Left lane line colorThe color of the left line.";
CM_ SG_ 832 ADAS_RiLineColor "Right lane line colorThe color of the Right line.";
CM_ SG_ 832 ADAS_LeLineDst "Distance from the ego vehicle to the left lane lineindicate the y distance between the leftline and the ego car center.";
CM_ SG_ 832 ADAS_RiLineDst "Distance from the ego vehicle to the right lane lineindicate the y distance between the Rightline and the ego car center.";
CM_ SG_ 832 ADAS_LeLineFlash "Flashing of left lane line";
CM_ SG_ 832 ADAS_RiLineFlash "Right lane flashing";
CM_ SG_ 832 ADAS_LeLineTyp "Left lane line typeThe type of the left line.";
CM_ SG_ 832 ADAS_RiLineTyp "Right lane line typeThe type of the Right line.";
CM_ SG_ 832 ADAS_LaneCrvt "Lane curvatureThe radium of the ego cars lane.";
CM_ SG_ 832 ADAS_FltIndcr "ADAS fault lamp indication (MRR/ADAS receive fault, hardware occlusion and fault of all functions, send this signal)";
CM_ SG_ 834 ADAS_342_Checksum "ADAS_342_Message checksum ( E2E data ID: 0x35)";
CM_ SG_ 834 ADAS_342_AliveCounter "ADAS342_Message CounterADAS_342_AliveCounter";
CM_ SG_ 834 ADAS_LatCtrl_LeTurnLampReq "Left turn lamp request";
CM_ SG_ 834 ADAS_LatCtrl_RiTurnLampReq "Right turn lamp request";
CM_ SG_ 834 ADAS_LatCtrl_HapticReq "Haptic request (EPS vibration)";
CM_ SG_ 834 ADAS_LatCtrl_HzrdLampReq "Hazard light activation";
CM_ SG_ 834 ADAS_VehMovDir "vehicle movment information so user is able to see the vehicle activities on the smartphone while using Remote Automated Parking function";
CM_ SG_ 834 ADAS_HOD_HandsOnWarnReq "Hands On Detection (HOD) hands on warning request (request driver to put hands on steering wheel)";
CM_ SG_ 834 ADAS_RAPAvl "RPA feature available status flag to PKC";
CM_ SG_ 834 ADAS_Sts_RAP "Remote Park Assist (RPA) feature status to PKC";
CM_ SG_ 834 ADAS_ExtLightReq "ADAS DC can request exterior light activation ";
CM_ SG_ 834 ADAS_HODSts "Hands On Detection (HOD) ";
CM_ SG_ 835 BCM_343_CheckSum "BCM3343_Message checksum ( 0xD7)BCM_343_CheckSum";
CM_ SG_ 835 BCM_343_AliveCounter "BCM3343_Message counterBCM_343_AliveCounter";
CM_ SG_ 835 BCM_RemReqFb "Remote request feedback";
CM_ SG_ 835 BCM_APASwSts "APA switch state";
CM_ SG_ 835 BCM_FrntHoodLidSts "Status of front engine hood";
CM_ SG_ 835 BCM_SunroofAntipinchSts "Sunroof anti-pinch state";
CM_ SG_ 835 BCM_FrntDrDoorLockSts "Driver door lock state";
CM_ SG_ 835 BCM_TrRelsSwtSts "State of micro switch of tail gate";
CM_ SG_ 835 BCM_LockAllDoorCmd "Four door locking output command";
CM_ SG_ 835 BCM_DrFrntDoorSts "Lock StATUS driver Door used as central lock information ";
CM_ SG_ 835 BCM_PasFrntDoorSts "Lock Status Passinger Front Door used as central lock information ";
CM_ SG_ 835 BCM_AntithftSts "Body anti-theft state";
CM_ SG_ 835 BCM_CenLockSwtSts "Central control lock switch state";
CM_ SG_ 835 BCM_DoorUnlockSetFb "Door unlocking setting feedback";
CM_ SG_ 835 BCM_RiReDoorSts "State of RR door";
CM_ SG_ 835 BCM_LeReDoorSts "State of left rear door";
CM_ SG_ 835 BCM_LeFrntWinSts "Opening and closing state of left front window";
CM_ SG_ 835 BCM_RiFrntWinSts "Opening and closing state of right front window";
CM_ SG_ 835 BCM_LeReWinSts "Opening and closing state of left rear window";
CM_ SG_ 835 BCM_RiReWinSt "Opening and closing state of right rear window";
CM_ SG_ 835 BCM_SunroofSts "Opening and closing status of sunroof";
CM_ SG_ 835 BCM_FolwMeSetStsFb "Follow me home setting status feedback";
CM_ SG_ 835 BCM_DrvrDoorUnlckOutpCmd "Driver door unlocking output command";
CM_ SG_ 835 BCM_PassDoorUnlckOutpCmd "Passenger door unlocking output command";
CM_ SG_ 835 BCM_LeDRLOutpCmd "Left daytime running lamp output command";
CM_ SG_ 835 BCM_RiDRLOutpCmd "Right daytime running lamp output command";
CM_ SG_ 835 BCM_ArmedClsWinSetSts "Central control screen control window setting state";
CM_ SG_ 835 BCM_OffAutoUnlckSetSts "Automatic unlocking setting state of central control flameout";
CM_ SG_ 835 BCM_WarnVbrnSts "BCM vibration alarm activated state";
CM_ SG_ 835 BCM_SunroofPosnInfo "Sunroof opening information";
CM_ SG_ 835 BCM_SunroofOpenAr "Sunroof opening area";
CM_ SG_ 835 BCM_SteerWhlVbrnAlrmAvl "Whether steering wheel vibration alarm is available";
CM_ SG_ 835 BCM_SunroofRunngSts "Sunroof operation state";
CM_ SG_ 835 BCM_MirrCmd "Exterior rearview mirror control";
CM_ SG_ 843 ADAS_Obj2_ID "Object identifier. If ID is 0x0 no object is detected";
CM_ SG_ 843 ADAS_Obj2_LongDist "Object Longitudinal distance (0.2 m/bit measured on the car; the matrix says 0.5)";
CM_ SG_ 843 ADAS_Obj2_LatDist "Object Latitudinal distance (0.2 m/bit measured on the car; the matrix says 0.5)";
CM_ SG_ 843 ADAS_Obj2_Width "Object Width";
CM_ SG_ 843 ADAS_Obj2_Conf "Object Confidence level";
CM_ SG_ 843 ADAS_Obj2_Length "Object length";
CM_ SG_ 843 ADAS_VVP_ICC_Obj2Hdng "Object 2 Heading Angle";
CM_ SG_ 843 ADAS_Obj2_Height "Object height";
CM_ SG_ 843 ADAS_Obj2_LongDistSign "Object longitudinal Distance Signal";
CM_ SG_ 843 ADAS_Obj2_LatDistSign "Object Latitudinal Distance Signal";
CM_ SG_ 843 ADAS_Obj2_Classification "Object Calssification";
CM_ SG_ 843 ADAS_VVP_ICC_Obj2BrkLght "Object 2 brake light on / off";
CM_ SG_ 843 ADAS_Obj2_ClassConf "Object Classification Confidence";
CM_ SG_ 845 ADAS_Obj5_ID "Object identifier. If ID is 0x0 no object is detected";
CM_ SG_ 845 ADAS_Obj5_LongDist "Object Longitudinal distance (0.2 m/bit measured on the car; the matrix says 0.5)";
CM_ SG_ 845 ADAS_Obj5_LatDist "Object Latitudinal distance (0.2 m/bit measured on the car; the matrix says 0.5)";
CM_ SG_ 845 ADAS_Obj5_Width "Object Width";
CM_ SG_ 845 ADAS_Obj5_Conf "Object Confidence level";
CM_ SG_ 845 ADAS_Obj5_Length "Object length";
CM_ SG_ 845 ADAS_VVP_ICC_Obj5Hdng "Object 5 Heading Angle";
CM_ SG_ 845 ADAS_Obj5_Height "Object height";
CM_ SG_ 845 ADAS_Obj5_LongDistSign "Object longitudinal Distance Signal";
CM_ SG_ 845 ADAS_Obj5_LatDistSign "Object Latitudinal Distance Signal";
CM_ SG_ 845 ADAS_Obj5_Classification "Object Calssification";
CM_ SG_ 845 ADAS_VVP_ICC_Obj5BrkLght "Object 5 brake light on / off";
CM_ SG_ 845 ADAS_Obj5_ClassConf "Object Classification Confidence";
CM_ SG_ 847 ADAS_Obj8_ID "Object identifier. If ID is 0x0 no object is detected";
CM_ SG_ 847 ADAS_Obj8_LongDist "Object Longitudinal distance (0.2 m/bit measured on the car; the matrix says 0.5)";
CM_ SG_ 847 ADAS_Obj8_LatDist "Object Latitudinal distance (0.2 m/bit measured on the car; the matrix says 0.5)";
CM_ SG_ 847 ADAS_Obj8_Width "Object Width";
CM_ SG_ 847 ADAS_Obj8_Conf "Object Confidence level";
CM_ SG_ 847 ADAS_Obj8_Length "Object length";
CM_ SG_ 847 ADAS_VVP_ICC_Obj8Hdng "Object 8 Heading Angle";
CM_ SG_ 847 ADAS_Obj8_Height "Object height";
CM_ SG_ 847 ADAS_Obj8_LongDistSign "Object longitudinal Distance Signal";
CM_ SG_ 847 ADAS_Obj8_LatDistSign "Object Latitudinal Distance Signal";
CM_ SG_ 847 ADAS_Obj8_Classification "Object Calssification";
CM_ SG_ 847 ADAS_VVP_ICC_Obj8BrkLght "Object 8 brake light on / off";
CM_ SG_ 847 ADAS_Obj8_ClassConf "Object Classification Confidence";
CM_ SG_ 848 ADAS_LeftLaneWidth "Estimated width of the lane to the left of the ego vehicle lane";
CM_ SG_ 848 ADAS_RightLaneWidth "Estimated width of the lane to the right of the ego vehicle lane";
CM_ SG_ 848 ADAS_LeftLaneType "Type of lane to the left of the ego vehicle lane, classifications to be defined";
CM_ SG_ 848 ADAS_RightLaneType "Type of lane to the right of the ego vehicle lane, classifications to be defined";
CM_ SG_ 848 ADAS_LandmarkType "Type of Landmark detected";
CM_ SG_ 848 ADAS_LaneMarkingDistance "Distance to the most significant lane markings";
CM_ SG_ 848 ADAS_LaneMarkingType "Type of lane marking, in order of significance";
CM_ SG_ 848 ADAS_ConstructionObjectType "Construction object type";
CM_ SG_ 848 ADAS_ConstructionObjectDst "Distance to construction object";
CM_ SG_ 848 ADAS_LandmarkDst "Distance to Landmark";
CM_ SG_ 849 ADAS_351_CheckSum "ADAS_351_Message Verification (E2E data ID: 0x38)";
CM_ SG_ 849 ADAS_351_AliveCounter "ESP 31A_Message counterESP_31A_AliveCounter";
CM_ SG_ 849 ADAS_LdngVhclTurnSig "turn signals for preceeding vehicle ";
CM_ SG_ 849 ADAS_LdngVhclBrkLi "brake lights for preceeding vehicle";
CM_ SG_ 849 ADAS_HzdDetected "Whether or not a hazard is detected";
CM_ SG_ 849 ADAS_HzdClassification "Hazard Classification, Magan and Fisker should collaborate on defining hazard classifications";
CM_ SG_ 849 ADAS_HzdDst "Hazard distance from Ego Vehicle";
CM_ SG_ 849 ADAS_TrafficLiDst "Distance to the most critical traffic light";
CM_ SG_ 850 ADAS_USS_B0 "USS Rear sector 0";
CM_ SG_ 850 ADAS_USS_F0 "USS Front sector 0";
CM_ SG_ 850 ADAS_USS_B1 "USS Rear sector 1";
CM_ SG_ 850 ADAS_USS_F1 "USS Front sector 1";
CM_ SG_ 850 ADAS_USS_B2 "USS Rear sector 2";
CM_ SG_ 850 ADAS_USS_F2 "USS Front sector 2";
CM_ SG_ 850 ADAS_USS_B3 "USS Rear sector 3";
CM_ SG_ 850 ADAS_USS_F3 "USS Front sector 3";
CM_ SG_ 850 ADAS_USS_L0 "USS Left sector 0";
CM_ SG_ 850 ADAS_USS_L1 "USS Left sector 1";
CM_ SG_ 850 ADAS_USS_L2 "USS Left sector 2";
CM_ SG_ 850 ADAS_USS_L3 "USS Left sector 3";
CM_ SG_ 850 ADAS_USS_R0 "USS Right sector 0";
CM_ SG_ 850 ADAS_USS_R1 "USS Right sector 1";
CM_ SG_ 850 ADAS_USS_R2 "USS Right sector 2";
CM_ SG_ 850 ADAS_USS_R3 "USS Right sector 3";
CM_ SG_ 851 ADAS_353_CheckSum "ADAS_353_Message Verification ( E2E data ID: 0x46 )";
CM_ SG_ 851 ADAS_353_AliveCounter "ADAS 353_Message counter";
CM_ SG_ 851 ADAS_VwPrtCamAngl "Virtual view camera angle";
CM_ SG_ 851 ADAS_LdngVhclID "Object ID of vehicle in front of ego vehicle (0 if no vehicle present within 50m)";
CM_ SG_ 854 ADAS_356_CheckSum "APA_356_Message Check (0x87)APA_356_CheckSum";
CM_ SG_ 854 ADAS_356_AliveCounter "APA_356APA_356_AliveCounter";
CM_ SG_ 854 ADAS_ObjDst_FLS "Front left obstacle distancePark Assistant Rear Left Side Object Distance.";
CM_ SG_ 854 ADAS_ObjDst_FLC "Obstacle distance of front left cornerPark Assistant Front Left Corne Object Distance.";
CM_ SG_ 854 ADAS_ObjDst_FLM "Front left middle obstacle distancePark Assistant Front Left Middle Object Distance.";
CM_ SG_ 854 ADAS_ObjDst_FRS "Distance between front right obstaclePark Assistant Front Right Side Object Distance.";
CM_ SG_ 854 ADAS_ObjDst_FRC "Obstacle distance of front right cornerPark Assistant Front Right Corner Object Distance.";
CM_ SG_ 854 ADAS_ObjDst_FRM "Front right middle obstacle distancePark Assistant Front Right Middle Object Distance.";
CM_ SG_ 856 VCU_358_CheckSum "VCU_0x358_Message Check (E2E data ID: 0x47)";
CM_ SG_ 856 VCU_358_AliveCounter "VCU_0x358_Message counter";
CM_ SG_ 856 VCU_KickdwnFlg "status of kickdown function ";
CM_ SG_ 856 VCU_EPedlEnaSig "E-Pedal enable signal (TBD if required)";
CM_ SG_ 856 VCU_ComLostFlt_ESP "VCU and ESP communication related faults";
CM_ SG_ 856 VCU_ComFlt_iBooster "VCU and iBooster communication failure_U101587_E03";
CM_ SG_ 856 VCU_RegenLvlFb "Coasting Mode settings (Off, Normal, high) feedback to ICC";
CM_ SG_ 856 VCU_AccelModFb "Acceleration Mode setting (Low/Mid/High) feedback to ICC";
CM_ SG_ 856 VCU_EPedlStsFb "Pedal Comport Setting (One Pedal Drive / Roll / Creep) feedback to ICC";
CM_ SG_ 856 VCU_CcTrgSpdDisp "Cruise Control Target Speed display";
CM_ SG_ 856 VCU_Sts_CC_ICC "ACC status";
CM_ SG_ 856 VCU_CCIconDisp "ACC icon color";
CM_ SG_ 856 VCU_DispSpdUnit_CC "CC display speed unit";
CM_ SG_ 856 VCU_BoostEnStat "Boost Enable Status";
CM_ SG_ 856 VCU_OTARdy_Fb "VCU OTA ready status feedback";
CM_ SG_ 856 VCU_OTA_ECUInhb_Req "VCU OTA inhibit request to ECUs";
CM_ SG_ 856 VCU_OTAVehCdnChk_ASIL "ASIL A group OTA vehicle condition check status";
CM_ SG_ 856 VCU_OTAVehInhb_ASIL_Fb "ASIL A group OTA vehicle Inhibit feedback";
CM_ SG_ 857 ADAS_359_CheckSum "APA_359_CheckSum (0x99)";
CM_ SG_ 857 ADAS_359_AliveCounter "APA_359_AliveCounter";
CM_ SG_ 857 ADAS_ObjDst_RLS "Rear left obstacle distancePark Assistant Rear Left Side Object Distance.";
CM_ SG_ 857 ADAS_ObjDst_RLC "Rear left corner obstacle distancePark Assistant Rear Left Corner Object Distance.";
CM_ SG_ 857 ADAS_ObjDst_RLM "Rear left middle obstacle distancePark Assistant Rear Left Middle Object Distance.";
CM_ SG_ 857 ADAS_ObjDst_RRS "Rear right obstacle distancePark Assistant Rear Right Side Object Distance.";
CM_ SG_ 857 ADAS_ObjDst_RRC "Obstacle distance of right rear cornerPark Assistant Rear Right Corner Object Distance.";
CM_ SG_ 857 ADAS_ObjDst_RRM "Rear right middle obstacle distancePark Assistant Rear Right Middle Object Distance.";
CM_ SG_ 859 ICC_ViewReq "Request from ICC to activates Surround View";
CM_ SG_ 859 ICC_SVS_AutoVwBttnReq "This signal incidates if the user selects automatic camera view";
CM_ SG_ 859 ICC_SVS_CamVwCnclReq "This signal incidates if the user presses the button to exit camera view.";
CM_ SG_ 859 ICC_AutomaticViewReq "To enable or disabled the automatic view from ICC setting menu";
CM_ SG_ 859 ICC_360FreeFloatingReq "To enable or disabled the automatic view from ICC setting menu";
CM_ SG_ 859 ICC_GraphicOverlayReq "To enable or disable viewing of graphic overlays presented in the LVDS viewport";
CM_ SG_ 859 ICC_OperationType "This signal conveys different types of user operations";
CM_ SG_ 859 ICC_ZOOM_Start "Zoom operations start status";
CM_ SG_ 859 ICC_ZOOM_End "Zoom operation end status";
CM_ SG_ 859 ICC_ZOOM_ScalingFactor "Floating point value between 0-32 to represent the amount of zoom";
CM_ SG_ 859 ICC_EnbLnChgAsst "Signal request for LCA activation in user settings";
CM_ SG_ 859 ICC_BSDSetting "Blind Spot Detection (BSD) user option setting";
CM_ SG_ 859 ICC_DOW_Setting "Door Open Warning (DOW) user options setting";
CM_ SG_ 859 ICC_DCAASetting "Driver Condition and Attention Assist (DCAA) user option setting";
CM_ SG_ 859 ICC_APA_Setting "Feature on/off setting";
CM_ SG_ 859 ICC_APAParkSelect "Status of slot selection by user through HMI";
CM_ SG_ 859 ICC_APAActivation "User can activte by pressing P button or voice. Pressing P button again cancels it.";
CM_ SG_ 859 ICC_APAParkInDirSetting "Parking in preference by user - vertical parking";
CM_ SG_ 859 ICC_APAParkOutDirSetting "Parking out preference by user - vertical parking";
CM_ SG_ 859 ICC_ParkAsstChmAlrt "Parking assist / APA audio aler preference by user ";
CM_ SG_ 859 ICC_WSPPA_Setting "Wheel scratch protection preference by user";
CM_ SG_ 859 ICC_APAParkOutAct "Signal indicating the Park Out maneuver is started";
CM_ SG_ 859 ICC_SteerWhlVibrSet "signal for steering wheel vibration selection on CID for LKA ";
CM_ SG_ 859 ICC_LKA_SettingWrnTyp "ICC setting signal for lane support";
CM_ SG_ 859 ICC_RAP_Setting "ICC setting to enable or disable the Remote Automated Parking (RAP). If enabled driver can control the RAP outside the vehicle (Feature in Standby).";
CM_ SG_ 859 ICC_TP_Setting "ICC setting to enable or disable the Trained Parking (TP). If enabled driver can control the TP outside the vehicle (Feature in Standby)";
CM_ SG_ 859 ICC_BSD_Sensitivity "Senstivity Setting for Blind Spot detection";
CM_ SG_ 865 ICC_PosnOffset "Position of the vehicle from the starting point of the pathOffset of current position from the current pathï¿½ï¿½s start point modulo 8191. Value 8191 is invalid.";
CM_ SG_ 865 ICC_PosnMsgTye "Identify the message as Position Message";
CM_ SG_ 865 ICC_PosnPathldx "Current Path index numberIndex of current path:If this number differs from the one transmitted in the previous POSITION message with Position Index = 0, the vehicle has left the original path; Indices 0-7 have special meaning:see sheet2 for details";
CM_ SG_ 865 ICC_PosnCycCnt "Loop counter of Position Message: Reconstructor can use this value to detect missing messagesCyclic counter of this message type:Reconstructor can use this value to detect missing messages";
CM_ SG_ 865 ICC_PosnPosProbb "Resolution should be 100/30 %";
CM_ SG_ 865 ICC_PosnSpd "Estimated speed of vehicle along Path";
CM_ SG_ 865 ICC_PosnCurLane "Current lane";
CM_ SG_ 865 ICC_PosnPosConfdc "Position confidence levelPosition confidence:this field contains Av2HP implementation specific values. Use 0 for highest confidence, 6 for lowest confidence. Value 7 means N/A";
CM_ SG_ 865 ICC_PosnRehead "Front direction relative to path. Resolution should be 360/254 degrees";
CM_ SG_ 866 ICC_MetaCountryCode "Country codeISO 3166-1 Release 2007-03 country code of current position;0 stands for unknown. Valid values are those specified by ISO 3166-1 numeric [14].";
CM_ SG_ 866 ICC_MetaMapProvider "Map providers of the current area (map tile, area, country...).";
CM_ SG_ 866 ICC_MetaMsgType "Identify the message bit";
CM_ SG_ 866 ICC_MetaHwVer "Hardware and/or software version of generator";
CM_ SG_ 866 ICC_MetaProtVerMinorSub "Secondary agreement sub-versionContains Minor protocol sub-version.";
CM_ SG_ 866 ICC_MetaProtVerMajor "Main agreement versionContains Major protocol version.";
CM_ SG_ 866 ICC_MetaCycCnt "This message type loop counter: The reconstructor can use this value to detect missing messagesCyclic counter of this message type:Reconstructor can use this value to detect missing messages.";
CM_ SG_ 866 ICC_MetaRegionCode "Area code0 stands for unknown, value 32767 means N/AAll other values are based on ISO 3166-2 [15] with the code mapping scheme.";
CM_ SG_ 866 ICC_MetaDrvSide "Driving direction";
CM_ SG_ 866 ICC_MetaMapVerYear "Map version (year)Please note if the whole map may be partitioned into parts that can be released on different times or even by different providers. In that case, value of this field may vary between messages. 63 stands for N/A";
CM_ SG_ 866 ICC_MetaMapVerQtr "Map version (quarter)Please note if the whole map may be partitioned into parts that can be released on different times or even by different providers. In that case, value if this field may vary between messages.";
CM_ SG_ 866 ICC_MetaProtVerMinor "Minor agreement version";
CM_ SG_ 866 ICC_MetaSpdUnits "Speed limit unit";
CM_ SG_ 866 ICC_Reserved "Reserved space";
CM_ SG_ 868 BCM_364_CheckSum "BCM_364_Message checksum (0xD3)BCM_364_CheckSum";
CM_ SG_ 868 BCM_364_AliveCounter "BCM_364_Message counterBCM_364_AliveCounter";
CM_ SG_ 868 BCM_OTARdy_Fb "BCM OTA ready status feedback";
CM_ SG_ 868 BCM_SBRMatStPass "SBR mat state of the passenger seat";
CM_ SG_ 868 BCM_BucSwtSt2ndRowLeft "Buckle switch state 2nd row left";
CM_ SG_ 868 BCM_BucSwtSt2ndRowMid "Buckle switch state 2nd row mid";
CM_ SG_ 868 BCM_BucSwtSt2ndRowRight "Buckle switch state 2nd row right";
CM_ SG_ 868 BCM_BucSwtSt3rdRowLeft "Buckle switch state 3rd row left";
CM_ SG_ 868 BCM_BucSwtSt3rdRowRight "Buckle switch state 3rd row right";
CM_ SG_ 868 BCM_SBRMatSt2ndRowLeft "SBR mat state 2nd row left";
CM_ SG_ 868 BCM_SBRMatSt2ndRowMid "SBR mat state 2nd row mid";
CM_ SG_ 868 BCM_SBRMatSt2ndRowRight "SBR mat state 2nd row right";
CM_ SG_ 868 BCM_SBRMat3rdRowLeft "SBR mat state 3rd row left";
CM_ SG_ 868 BCM_SBRMat3rdRowRight "SBR mat state 3rd row right";
CM_ SG_ 883 ECC_CrtSts "ECC current state";
CM_ SG_ 883 ECC_IninSts "ECC initialization state";
CM_ SG_ 883 ECC_PwrSysHeatMngtSts "Power system thermal management state";
CM_ SG_ 883 ECC_ACSts "A/C state";
CM_ SG_ 883 ECC_AirClnSts "Air purification state";
CM_ SG_ 883 ECC_WindSpdSts "Wind speed state";
CM_ SG_ 883 ECC_BackRowAirOutlModSts "Rear exhaust mode state";
CM_ SG_ 883 ECC_DrvrTSetSts "Main driving temperature setting state";
CM_ SG_ 883 ECC_PassTSetSts "Temperature setting state of front passenger";
CM_ SG_ 883 ECC_HeatSts "HEAT state";
CM_ SG_ 883 ECC_AUTOSts "A/C AUTO state";
CM_ SG_ 883 ECC_SYNCSts "SYNC state";
CM_ SG_ 883 ECC_InfoSysWrmColdDisp "Display of heating and cooling degree of entertainment system";
CM_ SG_ 883 ECC_CircSts "Cycle state";
CM_ SG_ 883 ECC_ParticleConcVld "Effective position of particle concentration";
CM_ SG_ 883 ECC_OutdT "Ambient temperature outside the vehicle";
CM_ SG_ 883 ECC_OutdTVld "Effective position of ambient temperature outside vehicle";
CM_ SG_ 883 ECC_MaxFrntDefrst "Max Front defrosting";
CM_ SG_ 883 ECC_HeatMngtSysFlt "Fault of thermal management system";
CM_ SG_ 883 ECC_HeatMngtFctLim "Requirement for Thermal Management Function of Occupant Compartment";
CM_ SG_ 883 ECC_DrvrAirOutlMod "Driver Air Outlet Mode";
CM_ SG_ 883 ECC_PassAirOutlMod "Front passenger air-out mode";
CM_ SG_ 883 ECC_RemSts "Operating status of remote A/C";
CM_ SG_ 883 ECC_OTAInhbRdy "OTA pre-condition and Inhibiting of all OTA relevant ECUs";
CM_ SG_ 1137 PLGM_UsrSetTrMaxHei "The maximum opening height of the rear door power set by the user (indicating that the stop height is set by the user. In the power mode, the height of the tailgate will not be greater than this value)Indicate customized maximum height.";
CM_ SG_ 1137 PLGM_LeTrPosn "Current height of the tailgate provided by the left stayIndicate the trunk position by percentage.";
CM_ SG_ 1137 PLGM_RiTrPosn "Current height of the tailgate provided by the right stayIndicate the trunk position by percentage.";
CM_ SG_ 1137 PLGM_LiRemdngReq_BCM "Turn signal lamp flashing requestReqeust to BCM for light reminding.";
CM_ SG_ 1137 PLGM_SoundRemdngReq_EHU "Speaker tone requestReqeust to ICC for sound reminding";
CM_ SG_ 1137 PLGM_FctEnaRes "Results of enable/disable of power function of stayIndicate if power lifing and closing function enabled or disabled.";
CM_ SG_ 1137 PLGM_SysFltIndcn "Power tailgate system faultyIndicate if PLG System failure happened., Including ECU,spindle and latch";
CM_ SG_ 1137 PLGM_TrSwtStsIndcn "Rear door switch state signalIndicate trunk status.";
CM_ SG_ 1137 PLGM_TrLtchStsIndcn "State signal of tail door lockIndicate latch status.";
CM_ SG_ 1137 PLGM_TrSwtTrigOpenReq "Rear door outside switch triggered opening requestWhen handle switch pressed, and trunk is fully closed, PLG send request to PEPS, and PEPS receive this signal to check key.";
CM_ SG_ 1137 PLGM_OperMod "Operating mode of controllerIndicate the working mode of PLG after end of line test.";
CM_ SG_ 1137 PLGM_TrSwtSts "State of tail door outer switchIndicate if handle switch is pressed or not.";
CM_ SG_ 1137 PLGM_LimpHomeSts "Limp home stateWhen trunk is open, if one of the spindle cannot work, PLG will stop driving spindles.";
CM_ SG_ 1137 PLGM_DrvrSwtSts "Driver side switch stateIndicate if driver switch is pressed or not.";
CM_ SG_ 1137 PLGM_TrInnrSwtSts "Rear door inner switch stateIndicate the operation to inner switch.";
CM_ SG_ 1137 PLGM_AntipinchSts "Anti-pinch state (whether anti-pinch occurs)Indicate if anti-pinch happened.";
CM_ SG_ 1137 PLGM_TrSts "Trunk state";
CM_ SG_ 1137 PLGM_OTARdy_Fb "PLGM OTA ready status feedback";
CM_ SG_ 1137 PLGM_Tindcn_NTC "Ambient temperature signal (the temperature detected by the temperature sensitive resistor in ECU, the default value of this signal is set to 110 ?)Indicate temperature detected by NTC on board.The default value set as 110?.";
CM_ SG_ 1153 ADAS_ECUUnexpectedRst "Unexpected reset of ADAS ECU_C12A005_E00";
CM_ SG_ 1153 ADAS_ChkBattVoltFlt "ADAS check battery voltage_U32201C_E00";
CM_ SG_ 1153 ADAS_1V25UnderOrOverVolt "ADAS 1V25 Undervoltage or Overvoltage fault_C12A116_E00";
CM_ SG_ 1153 ADAS_3V3UnderOrOverVolt "Undervoltage or Overvoltage Fault of ADAS 3V3_C12A216_E00";
CM_ SG_ 1153 ADAS_5V0UnderOrOverVolt "Undervoltage or Overvoltage Fault of ADAS 5V0_C12A316_E00";
CM_ SG_ 1153 ADAS_BusHwErr "ADASBUS bus hardware error_C12A409_E00";
CM_ SG_ 1153 ADAS_BusHwErr_FCM "Hardware error of ADAS and FCM communication bus_C12A509_E00";
CM_ SG_ 1153 ADAS_BusHwErr_MRR "Hardware error of ADAS and MRR communication bus_C12A609_E00";
CM_ SG_ 1153 ADAS_BusHwErr_CMRR_FL "Hardware error of ADAS and CMRR-FL communication bus_C12A709_E00";
CM_ SG_ 1153 ADAS_BusDiagHwErr_CMRR_FR "Hardware error of ADAS and CMRR-FR communication bus_C12A809_E00";
CM_ SG_ 1153 ADAS_ChkInvldSig_FCM "IDLE of ADAS check FCM signal_C12A986_E00";
CM_ SG_ 1153 ADAS_ChkInvldSig_CMRR_RL "The ADAS check CMRR-RL signal is invalid_C12AA86_E00";
CM_ SG_ 1153 ADAS_ChkInvldSig_CMRR_FR "The ADAS check CMRR-FR signal invalid_C12AB86_E00";
CM_ SG_ 1153 ADAS_ChkInvldSig_CMRR_FL "The ADAS test CMRR-FL signal invalid_C12AC86_E00";
CM_ SG_ 1153 ADAS_ChkInvldSig_CMRR_RR "The ADAS test CMRR-RR signal is invalid_C12AD86_E00";
CM_ SG_ 1153 ADAS_ChkInvldSig_MRR "The ADAS check MRR signal is invalid_C12AE86_E00";
CM_ SG_ 1153 ADAS_ChkInvldSig_ESP "The ADAS ESP signal invalid_C12AF86_E00";
CM_ SG_ 1153 ADAS_ChkInvldSig_ACU "The ADAS check ACU signal invalid_C12B086_E00";
CM_ SG_ 1153 ADAS_ChkInvldSig_EPS "The ADAS EPS signal invalid_C12B186_E00";
CM_ SG_ 1153 ADAS_ChkInvldSig_iBooster "The ADAS iBooster signal invalid_C12B286_E00";
CM_ SG_ 1153 ADAS_ChkInvldSig_YRS "IDLE of ADAS test YRS signal_C12B386_E00";
CM_ SG_ 1153 ADAS_ChkInvldSig_BCM "The ADAS check BCM signal invalid_C12B486_E00";
CM_ SG_ 1153 ADAS_ChkInvldSig_ECC "IDLE ADAS ECC signal_C12B586_E00";
CM_ SG_ 1153 ADAS_ChkInvldSig_TBOX "The ADAS check TBOX signal invalid_C12B686_E00";
CM_ SG_ 1153 ADAS_ChkInvldSig_MCU_F "The ADAS check MCU_F signal invalid_C12B786_E00";
CM_ SG_ 1153 ADAS_ChkInvldSig_MCU_R "The ADAS check MCU_R signal is invalid_C12B886_E00";
CM_ SG_ 1153 ADAS_ChkInvldSig_PLGM "The ADAS check PLG signal invalid C12B986_E00";
CM_ SG_ 1153 ADAS_ChkInvldSig_CIM "IDLE of ADAS CIM signal_C12BA86_E00";
CM_ SG_ 1153 ADAS_ChkInvldSig_VCU "The ADAS VCU signal invalid_C12BB86_E00";
CM_ SG_ 1153 ADAS_ChkInvldSig_ICC "IDLE ADAS IDLE ICC signal_C12BC86_E00";
CM_ SG_ 1153 ADAS_ChkInvldSig_PEPS "The ADAS PEPS signal invalid_C12BD86_E00";
CM_ SG_ 1153 ADAS_ChkInvldSig_TPMS "The ADAS TPMS signal invalid_C12BE86_E00";
CM_ SG_ 1153 ADAS_ChkInvldSig_AVAP "The ADAS check AVAP signal invalid_C12BF86_E00";
CM_ SG_ 1153 ADAS_ComE2EFlt "ADAS communication check fault_C12A608_E00";
CM_ SG_ 1153 ADAS_ComLostFlt_FCM "Fail loss of ADAS communication with FCM_U322187_E00";
CM_ SG_ 1153 ADAS_ComLostFlt_CMRR_RL "Fail loss of communication between ADAS and CMRR-RL_U322287_E00";
CM_ SG_ 1153 ADAS_ComLostFlt_CMRR_FL "Fail loss of communication between ADAS and CMRR-FL_U322387_E00";
CM_ SG_ 1153 ADAS_ComLostFlt_CMRR_RR "Fail loss of communication between ADAS and CMRR-RR_U322487_E00";
CM_ SG_ 1153 ADAS_ComLostFlt_CMRR_FR "Fail loss of communication between ADAS and CMRR-FR_U322587_E00";
CM_ SG_ 1153 ADAS_ComLostFlt_MRR "Fail loss of ADAS and MRR communication_U322687_E00";
CM_ SG_ 1153 ADAS_ComLostFlt_ESP "Failure of ADAS and ESP communication_U322787_E00";
CM_ SG_ 1153 ADAS_ComLostFlt_ACU "Lost communication between ADAS and ACU faila_U322887_E00";
CM_ SG_ 1153 ADAS_ComLostFlt_EPS "Lost communication between ADAS and EPS_U322987_E00";
CM_ SG_ 1153 ADAS_ComLostFlt_iBooster "Failure lost communication between ADAS and iBooster_U322A87_E00";
CM_ SG_ 1153 ADAS_ComLostFlt_YRS "Lost communication between ADAS and YRS faila_U322B87_E00";
CM_ SG_ 1153 ADAS_ComLostFlt_BCM "Failure lost communication between ADAS and BCM_U322C87_E00";
CM_ SG_ 1153 ADAS_ComLostFlt_ECC "Lost communication between ADAS and ECC_U322D87_E00";
CM_ SG_ 1153 ADAS_ComLostFlt_TBOX "Fail lost communication between ADAS and TBOX_U322F87_E00";
CM_ SG_ 1153 ADAS_ComLostFlt_MCU_F "Fail lost communication between ADAS and MCU_F_U134087_E00";
CM_ SG_ 1153 ADAS_ComLostFlt_MCU_R "Lost communication between ADAS and MCU_R fa_U134187_E00";
CM_ SG_ 1153 ADAS_ComLostFlt_PLGM "Lost communication between ADAS and PLG faila_U134287_E00";
CM_ SG_ 1153 ADAS_ComLostFlt_CIM "Lost communication between ADAS and CIM faila_U134387_E00";
CM_ SG_ 1153 ADAS_ComLostFlt_VCU "Lost communication between ADAS and VCU faila_U134487_E00";
CM_ SG_ 1153 ADAS_ComLostFlt_ICC "Failure of lost communication between ADAS and ICC_U134587_E00";
CM_ SG_ 1153 ADAS_ComLostFlt_PEPS "Failure of communication loss between ADAS and PEPS_U134687_E00";
CM_ SG_ 1153 ADAS_ComLostFlt_TPMS "Lost communication between ADAS and TPMS faila_U134787_E00";
CM_ SG_ 1153 ADAS_ComLostFlt_AVAP "Fail loss of communication between ADAS and AVAP_U134887_E00";
CM_ SG_ 1153 ADAS_ChkPublicCANBusOff "ADAS inspection unit CAN BUSOFF_U134988_E00";
CM_ SG_ 1153 ADAS_MstRAMTestErr "ADAS master controller RAM test error_C12C042_E00";
CM_ SG_ 1153 ADAS_MstNVRAMTestErr "ADAS master controller NVRAM test error_C12C043_E00";
CM_ SG_ 1153 ADAS_NVMChipErr "ADAS NVM chip error_C12C149_E00";
CM_ SG_ 1153 ADAS_NVMStructErr "Structure error of ADAS NVM_C12C176_E00";
CM_ SG_ 1153 ADAS_MstWdgErr "ADAS master controller watchdog error_C12C247_E00";
CM_ SG_ 1153 ADAS_MstSOPTErr "ADAS master controller SOPT error_C12C204_E00";
CM_ SG_ 1154 ADAS_MstHwstartupErr "ADAS master controller hardware start error_C12C249_E00";
CM_ SG_ 1154 ADAS_MstHwCycTest "ADAS master controller hardware cycle test error_C12200_E00";
CM_ SG_ 1154 ADAS_EOLCalOutOfRng "ADAS EOL calibration results overbound_C12C378_E00";
CM_ SG_ 1154 ADAS_ECUTFlt "ADAS ECU temperature anomaly C12C44B_E00";
CM_ SG_ 1154 ADAS_PwrModFlt "ADAS power supply mode abnormal_C12C501_E00";
CM_ SG_ 1154 ADAS_ComLostFlt_MFS "Failure of ADAS and MFS communication_U134987_E00";
CM_ SG_ 1154 ADAS_PrivateCANComE2EFlt_FCM "ADAS check of FCM private CAN communication check fault_U134A82_E00";
CM_ SG_ 1154 ADAS_PrivateCANComE2EFlt_MRR "ADAS check MRR private CAN communication check fault_U134B82_E00";
CM_ SG_ 1154 ADAS_PrivateCANComE2EFlt_CMRR_FL "ADAS check CMRR-FL private CAN communication check fault_U134C82_E00";
CM_ SG_ 1154 ADAS_PrivateCANComE2EFlt_CMRR_FR "ADAS check CMRR-FR private CAN communication check malfunction_U134D82_E00";
CM_ SG_ 1154 ADAS_PrivateCANComE2EFlt_CMRR_RL "ADAS check CMRR-RL private CAN communication check fault_U134F82_E00";
CM_ SG_ 1154 ADAS_PrivateCANComE2EFlt_CMRR_RR "ADAS check CMRR-RR private CAN communication check fault_U135082_E00";
CM_ SG_ 1154 ADAS_PrivateCANComLostFlt_FCM "Loss of ADAS and FCM private CAN communication_U134A87_E00";
CM_ SG_ 1154 ADAS_PrivateCANComLostFlt_MRR "Lost communication between ADAS and MRR private CAN_U134B87_E00";
CM_ SG_ 1154 ADAS_PrivateCANComLost_CMRR_FL "Loss of CAN communication between ADAS and CMRR-FL private_U134C87_E00";
CM_ SG_ 1154 ADAS_PrivateCANComLost_CMRR_FR "Loss of CAN communication between ADAS and CMRR-FR private_U134D87_E00";
CM_ SG_ 1154 ADAS_PrivateCANComLost_CMRR_RL "Loss of CAN communication between ADAS and CMRR-RL private_U134E87_E00";
CM_ SG_ 1154 ADAS_PrivateCANComLost_CMRR_RR "Lost CAN communication between ADAS and CMRR-RR private_U135087_E00";
CM_ SG_ 1154 ADAS_PERChkIntFltInfo "Internal fault detected by PER message_C12C768_E00";
CM_ SG_ 1154 ADAS_HWAActvFlg "HWA-Function activation flag_ADA0006_E03";
CM_ SG_ 1154 ADAS_HWASucFlg "HWA-Function Lane Change success flag_ADA0007_E03";
CM_ SG_ 1159 FCM_ComLostFlt_ESP "Malle_U30CF87_E00";
CM_ SG_ 1159 FCM_ComLostFlt_iBooster "Missed communication between FCM and iBooster_U30E287_E00";
CM_ SG_ 1159 FCM_ComLostFlt_EPS "FCM and EPS communication loss faila_U30CC87_E00";
CM_ SG_ 1159 FCM_ComLostFlt_YRS "Malfunction of loss of FCM and YRS communication_U30E387_E00";
CM_ SG_ 1159 FCM_ComLostFlt_BCM "Fail lost communication between FCM and BCM_U30C487_E00";
CM_ SG_ 1159 FCM_ComLostFlt_ECC "Lost communication between FCM and ECC_U30E487_E00";
CM_ SG_ 1159 FCM_ComLostFlt_TBOX "Fail loss of FCM and TBOX communication_U30D887_E00";
CM_ SG_ 1159 FCM_ComLostFlt_CIM "Fail loss of FCM and CIM communication_U30E587_E00";
CM_ SG_ 1159 FCM_ComLostFlt_ICC "Malfunction of lost communication between FCM and ICC_U30E687_E00";
CM_ SG_ 1159 FCM_ComLostFlt_MRR "Fail loss of FCM and MRR communication_U30EA87_E00";
CM_ SG_ 1159 FCM_ComLostFlt_PEPS "Missing communication failure between FCM and PEPS_U30E787_E00";
CM_ SG_ 1159 FCM_ComLostFlt_ADAS "Fail loss of communication between FCM and ADAS_U30EB87_E00";
CM_ SG_ 1159 FCM_ComE2EFlt "FCM communication check fault_C10E08_E00";
CM_ SG_ 1159 FCM_ChkInvldSig_ESP "The ESP signal of FCM is invalid_C10E586_E00";
CM_ SG_ 1159 FCM_ChkInvldSig_iBooster "The FCM iBooster signal invalid_C10E686_E00";
CM_ SG_ 1159 FCM_ChkInvldSig_EPS "The FCM check EPS signal invalid_C10E786_E00";
CM_ SG_ 1159 FCM_ChkInvldSig_YRS "The FCM check YRS signal invalid_C10E886_E00";
CM_ SG_ 1159 FCM_ChkInvldSig_CIM "Fail CIM signal detected by FCM_C10EA86_E00";
CM_ SG_ 1159 FCM_ChkInvldSig_ECC "The EC86_E00 EC86_C10";
CM_ SG_ 1159 FCM_ChkInvldSig_PEPS "The PEPS check signal of FCM is invalid_C10ED86_E00";
CM_ SG_ 1159 FCM_ChkInvldSig_ICC "The ICC signal detected by FCM is invalid_C10EB86_E00";
CM_ SG_ 1159 FCM_ChkPrivateCANBusOff "FCM check the private CAN bus shutdown_U30E888_E00";
CM_ SG_ 1159 FCM_ChkPublicCANBusOff "FCM check the public CAN bus shutdown_U30E988_E00";
CM_ SG_ 1159 FCM_BattVoltBelowThd "Low voltage of FCM inspection battery_C10E016_E00";
CM_ SG_ 1159 FCM_BattVoltOverThd "Overvoltage of FCM inspection battery_C10E017_E00";
CM_ SG_ 1159 FCM_CamBli "FCM camera occlusion_C10EF97_E00";
CM_ SG_ 1159 FCM_ECUTmpHiTProtn "FCM inspection ECU temporary high temperature protection_C10F098_E00";
CM_ SG_ 1159 FCM_IntCircOutpVoltBelowThd "FCM internal circuit output voltage low_C10F116_E00";
CM_ SG_ 1159 FCM_IntCircOutpVoltOverThd "FCM internal circuit output voltage H_C10F117_E00";
CM_ SG_ 1159 FCM_IntCircPrmntFlt "Permanent failure of FCM internal circuit_C10F149_E00";
CM_ SG_ 1159 FCM_MatchParaErr "FCM matching parameter incorrect_C10F262_E00";
CM_ SG_ 1159 FCM_VehCfgInfoErr "FCM Verify vehicle configuration information Error_C10F355_E00";
CM_ SG_ 1159 FCM_IntCircFlt "Fail internal FCM circuit_C10F449_E00";
CM_ SG_ 1159 FCM_DLCFlt_ESP "FCM Check ESP Data Length Code Fault_C10E581_E00";
CM_ SG_ 1159 FCM_DLCFlt_iBooster "FCM check iBooster data length code fault_C10E681_E00";
CM_ SG_ 1159 FCM_DLCFlt_EPS "FCM check EPS data length code fault_C10E781_E00";
CM_ SG_ 1159 FCM_DLCFlt_YRS "FCM Check YRS Data Length Coding Fault_C10E881_E00";
CM_ SG_ 1159 FCM_DLCFlt_BCM "FCM Check BCM Data Length Code Fault_C10E981_E00";
CM_ SG_ 1159 FCM_DLCFlt_ECC "FCM Verify ECC Data Length Coding Fault_C10EC81_E00";
CM_ SG_ 1159 FCM_DLCFlt_TBOX "FCM Check TBOX Data Length Code Fault_C10F581_E00";
CM_ SG_ 1159 FCM_DLCFlt_CIM "FCM Check CIM Data Length Code Fault_C10EA81_E00";
CM_ SG_ 1159 FCM_DLCFlt_ICC "FCM Check ICC Data Length Coding Fault_C10EB81_E00";
CM_ SG_ 1159 FCM_DLCFlt_MRR "FCM Check MRR Data Length Code Fault_C10F681_E00";
CM_ SG_ 1159 FCM_DLCFlt_PEPS "FCM Check PEPS Data Length Coding Fault_C10ED81_E00";
CM_ SG_ 1159 FCM_DLCFlt_ADAS "FCM Check ADAS Data Length Code Fault_C10F781_E00";
CM_ SG_ 1159 FCM_OnlineCalOutOfRng "FCM online calibration out of range_C10E384_E00";
CM_ SG_ 1159 FCM_IniCalOutOfRng "FCM initial calibration out of range_C10E385_E00";
CM_ SG_ 1159 FCM_IniCalTimeout "FCM initial calibration timeout_C10E363_E00";
CM_ SG_ 1159 FCM_NotCal "FCM uncalibration_C10E354_E00";
CM_ SG_ 1159 FCM_OTARdy_Fb "FCM OTA ready status feedback";
CM_ SG_ 1300 MFS_0x514_CheckSum "MFS_0x514_Message check (0xC5)_CheckSum";
CM_ SG_ 1300 MFS_0x514_AliveCounter "MFS_0x514_Message counterAliveCounter";
CM_ SG_ 1300 MFS_LeRollUp "Left roller (up)";
CM_ SG_ 1300 MFS_LeRollDwn "Left roller (roll-down)";
CM_ SG_ 1300 MFS_LeRollPress "Left roller (pressed)- Mute(press)";
CM_ SG_ 1300 MFS_RiBtnNorth "ACC on/off";
CM_ SG_ 1300 MFS_RiRollUp "Right roller (top rolling)";
CM_ SG_ 1300 MFS_RiRollDwn "Right roller (roll-down)";
CM_ SG_ 1300 MFS_RiRollPress "Right roller (pressed-OK,Confirm(press)";
CM_ SG_ 1300 MFS_Ri_Fail "Button Failure right buttons";
CM_ SG_ 1300 MFS_Le_Fail "Button Failure left buttons";
CM_ SG_ 1317 TBOX_525_CheckSum "TBOX_525_Message checksum (0xF9)TBOX_525_CheckSum";
CM_ SG_ 1317 TBOX_525_AliveCounter "TBOX_525_Message CounterTBOX_525_AliveCounterr";
CM_ SG_ 1317 TBOX_GPSHei "Altitude Height";
CM_ SG_ 1318 TBOX_GPSLongi "Longitude (the east longitude is positive and the west longitude is negative.)Longitude";
CM_ SG_ 1318 TBOX_GPSLati "Latitude (north is positive and south is negative.)Latitude";
CM_ SG_ 1319 ADAS_DrvrAttention_Zone "Signal to the vehicle indicating where the driver's attention is centered";
CM_ SG_ 1319 ADAS_DrvrAlert_State "Whether or not the IR LED is blocked";
CM_ SG_ 1319 ADAS_DMS_Camera_Blockage_Status "Signal to the vehicle indicating whether or not the driver is alert";
CM_ SG_ 1319 ADAS_DrvrEngagement_Level_Status "Engagement level of driver";
CM_ SG_ 1319 ADAS_DMS_IR_Blockage_Status "Whether or not the camera is blocked";
CM_ SG_ 1319 ADAS_DrvrEngagement_Level_Conf "Confidence of engagement level";
CM_ SG_ 1319 ADAS_DrvrImpairment_Level_Stat "Impairment level of driver";
CM_ SG_ 1319 ADAS_DrvrImpairment_Level_Conf "confidence of impairment level";
CM_ SG_ 1319 ADAS_DrvrDrowsiness_Level "Drowsiness level of driver";
CM_ SG_ 1319 ADAS_DCAA_DrvrDrowsinessVld "Driver Drowsiness level of confidence";
CM_ SG_ 1319 ADAS_DCAA_DrvrAttentionLvl "Driver level of Attention (no reference yet)";
CM_ SG_ 1319 ADAS_DCAA_DrvrAttentionVld "Driver level of attention confidence (no reference yet)";
CM_ SG_ 1319 ADAS_DCAA_DrvrDrowsinessLvl "Driver Drowsiness level based on Karolinska Scale";
CM_ SG_ 1319 ADAS_DMSDrvrDetn "DMS drivier detection";
CM_ SG_ 1319 ADAS_DMS_IRSts "DMS IR status";
CM_ SG_ 1319 ADAS_DCAA_FrameIndex "DCAA frame Index";
CM_ SG_ 1322 ICC_0x52A_CheckSum "ICC_0x52A_CheckSum (E2E Data ID: 0xF5)";
CM_ SG_ 1322 ICC_0x52A_AliveCounter "ICC_0x52A_AliveCounter";
CM_ SG_ 1322 ICC_FACM_DynmcSenstvty "This signal indicates if dynamic sensitivity is enabled by user";
CM_ SG_ 1322 ICC_UsrProfTiGapSet "Automatic Cruise Control (ACC) Time Gap Setting from ICC user profile";
CM_ SG_ 1322 ICC_LKA_Setting "RCTA Alert Type";
CM_ SG_ 1322 ICC_FACM_Setting "FACM setting";
CM_ SG_ 1322 ICC_AEB_Sensitivity "AEB Time Sensitivity Setting ";
CM_ SG_ 1322 ICC_BACM_Setting "BACM (Rear AEB and RCTB) On and Off";
CM_ SG_ 1322 ICC_BACM_Sensitivity "BACM (Rear AEB and RCTB) Time Sensitivity Setting ";
CM_ SG_ 1322 ICC_AEB_JerkSetReq "Enabling/disabling the AEB jerk by the driver";
CM_ SG_ 1322 ICC_ActvStyGlblSetting "Global setting to turn off all active safety features: AEB (forward and backward), LKA, ELKA, ESA";
CM_ SG_ 1322 ICC_TSR_Setting "To turn On and Off TSR feature settings";
CM_ SG_ 1322 ICC_ESA_Setting "To turn On and Off ESA feature settings";
CM_ SG_ 1322 ICC_ELKASteeringInterventionSet "ELKA Steering intervention on/off";
CM_ SG_ 1322 ICC_LaneTrajectorySetting "Turn the LCA trajectory display on or off";
CM_ SG_ 1322 ICC_ACCAutoSpdSts "ACC Auto Speed setting";
CM_ SG_ 1322 ICC_ACCSpdStepSize "Automatic Cruise Control (ACC) Speed setting step size";
CM_ SG_ 1322 ICC_ACCFuncTyp "Automatic Cruise Control (ACC) function type";
CM_ SG_ 1322 ICC_ACCSpdLimOffs "Automatic Cruise Control (ACC) speed limit offset value (percentage)";
CM_ SG_ 1322 ICC_ACCSpdLimOffsTyp "Automatic Cruise Control (ACC) speed limit offset type";
CM_ SG_ 1322 ICC_ACCTerrainSetting "Automatic Cruise Control (ACC) terrain setting";
CM_ SG_ 1322 ICC_ACCTiGapCfm "Automatic Cruise Control (ACC) Time Gap confirmation by driver";
CM_ SG_ 1322 ICC_ISASetting "ISA settings";
CM_ SG_ 1322 ICC_FCTA_Sensitivity "FCTA Sensitivity";
CM_ SG_ 1322 ICC_TLR_Setting "To turn On and Off TLR feature settings";
CM_ SG_ 1322 ICC_FCTA_Setting "FCTA Setting";
CM_ SG_ 1329 ICC_TotMilgVld_ODO "Effective bit of ODO total mileage";
CM_ SG_ 1329 ICC_TotMilg_ODO "ODO total mileage";
CM_ SG_ 1329 ICC_DispVehSpd "Display speed";
CM_ SG_ 1329 ICC_DispVehSpdUnit "Display vehicle speed unit";
CM_ SG_ 1329 ICC_ADASSigFlt "Instrument ADAS signal fault";
CM_ SG_ 1329 ICC_DispFlt "Instrument display failure";
CM_ SG_ 1329 ICC_WorkshopMode "Setting by customer over display before he wants to tow the vehicle (=Rescue (Workshop Mode)";
CM_ SG_ 1625 ADAS_SwVersS "The last two digits of ADAS software version number";
CM_ SG_ 1625 ADAS_PartVers "ADAS part number";
CM_ SG_ 1625 ADAS_HwVers "Two digits of ADAS hardware version number";
CM_ SG_ 1625 ADAS_SwVersM "last two digits of ADAS main software version number";
CM_ SG_ 1662 MRR_SwVersS "The second two digits of MRR software version number";
CM_ SG_ 1662 MRR_PartVers "MRR part number";
CM_ SG_ 1662 MRR_HwVers "First two digits of MRR hardware version number";
CM_ SG_ 1662 MRR_SwVersM "First two digits of MRR main software version number";
CM_ SG_ 1664 CMRR_RL_SwVersS "CMRR_RL software version number and two digits";
CM_ SG_ 1664 CMRR_RL_PartVers "CMRR_RL part number";
CM_ SG_ 1664 CMRR_RL_HwVers "CMRR_RL Hardware version two digits";
CM_ SG_ 1664 CMRR_RL_SwVersM "CMRR_RL major software version two digits";
CM_ SG_ 1671 CMRR_RR_SwVersS "CMRR_RR software version number and two digits";
CM_ SG_ 1671 CMRR_RR_PartVers "CMRR_RR part number";
CM_ SG_ 1671 CMRR_RR_HwVers "CMRR_RR Hardware version two digits";
CM_ SG_ 1671 CMRR_RR_SwVersM "CMRR_RR major software version two digits";
CM_ SG_ 1673 CMRR_FL_SwVersS "CMRR_FL software version number and two digits";
CM_ SG_ 1673 CMRR_FL_PartVers "CMRR_FL Part No.";
CM_ SG_ 1673 CMRR_FL_HwVers "CMRR_FL Hardware version two digits";
CM_ SG_ 1673 CMRR_FL_SwVersM "CMRR_FL major software version two digits";
CM_ SG_ 1674 CMRR_FR_SwVersS "CMRR_FR software version number and two digits";
CM_ SG_ 1674 CMRR_FR_PartVers "CMRR_FR part number";
CM_ SG_ 1674 CMRR_FR_HwVers "CMRR_FR hardware version two digits";
CM_ SG_ 1674 CMRR_FR_SwVersM "CMRR_FR major software version two digits";
BA_ "GenMsgCycleTime" BO_ 821 50;
BA_ "GenMsgCycleTime" BO_ 825 50;
BA_ "GenMsgCycleTime" BO_ 827 40;
BA_ "GenMsgCycleTime" BO_ 829 40;
BA_ "GenMsgCycleTime" BO_ 831 40;
BA_ "GenMsgCycleTime" BO_ 832 50;
BA_ "GenMsgCycleTime" BO_ 834 50;
BA_ "GenMsgCycleTime" BO_ 835 50;
BA_ "GenMsgCycleTime" BO_ 843 40;
BA_ "GenMsgCycleTime" BO_ 845 40;
BA_ "GenMsgCycleTime" BO_ 847 40;
BA_ "GenMsgCycleTime" BO_ 848 100;
BA_ "GenMsgCycleTime" BO_ 849 100;
BA_ "GenMsgCycleTime" BO_ 850 100;
BA_ "GenMsgCycleTime" BO_ 851 100;
BA_ "GenMsgCycleTime" BO_ 854 100;
BA_ "GenMsgCycleTime" BO_ 856 100;
BA_ "GenMsgCycleTime" BO_ 857 100;
BA_ "GenMsgCycleTime" BO_ 859 200;
BA_ "GenMsgCycleTime" BO_ 865 100;
BA_ "GenMsgCycleTime" BO_ 866 100;
BA_ "GenMsgCycleTime" BO_ 868 100;
BA_ "GenMsgCycleTime" BO_ 883 100;
BA_ "GenMsgCycleTime" BO_ 1137 100;
BA_ "GenMsgCycleTime" BO_ 1153 100;
BA_ "GenMsgCycleTime" BO_ 1154 100;
BA_ "GenMsgCycleTime" BO_ 1159 100;
BA_ "GenMsgCycleTime" BO_ 1300 50;
BA_ "GenMsgCycleTime" BO_ 1317 100;
BA_ "GenMsgCycleTime" BO_ 1318 100;
BA_ "GenMsgCycleTime" BO_ 1319 100;
BA_ "GenMsgCycleTime" BO_ 1322 200;
BA_ "GenMsgCycleTime" BO_ 1329 100;
BA_ "GenMsgCycleTime" BO_ 1625 1000;
BA_ "GenMsgCycleTime" BO_ 1662 1000;
BA_ "GenMsgCycleTime" BO_ 1664 1000;
BA_ "GenMsgCycleTime" BO_ 1671 1000;
BA_ "GenMsgCycleTime" BO_ 1673 1000;
BA_ "GenMsgCycleTime" BO_ 1674 1000;
VAL_ 821 BCM_WiprInSrvPosn 0 "No" 1 "Yes" ;
VAL_ 821 BCM_IntLampTiSetSts 0 "Not_Use" 1 "0" 2 "15" 3 "30" 4 "45" 5 "60" 6 "Reserved" 7 "Reserved" ;
VAL_ 821 BCM_WaterPosnSnsrSwtSts 0 "Inactive" 1 "Active" ;
VAL_ 821 BCM_FrntFogLampOutpCmd 0 "Off" 1 "On" ;
VAL_ 821 BCM_LicPlateLampOutpCmd 0 "Off" 1 "On" ;
VAL_ 821 BCM_EnaSts_ADB 0 "Inactive" 1 "Active" ;
VAL_ 821 BCM_PwrSaveOutpCmd 0 "Off" 1 "On" ;
VAL_ 821 BCM_ExtLampSwtSts 0 "Off" 1 "Auto" 2 "Position" 3 "Low_Beam" 4 "Reserved" 5 "Reserved" 6 "Reserved" 7 "Reserved" ;
VAL_ 821 BCM_HornOutpCmd 0 "Off" 1 "On" ;
VAL_ 821 BCM_HornSwtSts 0 "Off" 1 "On" ;
VAL_ 821 BCM_WelLampOutpCmd 0 "Off" 1 "On" ;
VAL_ 821 BCM_FolwMeHomeSts 0 "Inactive" 1 "Active" ;
VAL_ 821 BCM_FrntFogLampSwtSts 0 "Inactive" 1 "Active" ;
VAL_ 821 BCM_ReFogLampSwtSts 0 "Inactive" 1 "Active" ;
VAL_ 821 BCM_ReWiprBackSwtSts 0 "Inactive" 1 "Active" ;
VAL_ 821 BCM_RainClsSunroofSetSts 0 "Inactive" 1 "Active" ;
VAL_ 821 BCM_MirrLockAutoSetSts 0 "Off" 1 "On" ;
VAL_ 821 BCM_FrntWshrOutpCmd 0 "Off" 1 "On" ;
VAL_ 821 BCM_DangerAlrmLampSwtSts 0 "Off" 1 "On" ;
VAL_ 821 BCM_ReDefrstHeatgCmd 0 "Off" 1 "On" ;
VAL_ 821 BCM_RvsLampOutpCmd 0 "Off" 1 "On" ;
VAL_ 821 BCM_IntLampOutpCmd 0 "Off" 1 "On" ;
VAL_ 821 BCM_LeTrunLampOutpCmd 0 "Off" 1 "On" ;
VAL_ 821 BCM_RiTrunLampOutpCmd 0 "Off" 1 "On" ;
VAL_ 821 BCM_ReWiprOutpCmd 0 "Off" 1 "On" ;
VAL_ 821 BCM_ReWshrOutpCmd 0 "Off" 1 "On" ;
VAL_ 821 BCM_BrkLampSwtSts 0 "Inactive" 1 "Active" ;
VAL_ 821 BCM_HiBeamOutpCmd 0 "Off" 1 "On" ;
VAL_ 821 BCM_LoBeamOutpCmd 0 "Off" 1 "On" ;
VAL_ 821 BCM_PosnLampOutpCmd 0 "Off" 1 "Left_Park_On" 2 "Right_Park_On" 3 "All_On" ;
VAL_ 821 BCM_BrkLampOutpCmd 0 "Off" 1 "On" ;
VAL_ 821 BCM_ReFogLampOutpCmd 0 "Off" 1 "On" ;
VAL_ 821 BCM_EnaReq_ADB 0 "Inactive" 1 "Active" ;
VAL_ 821 BCM_VehAmbBri 254 "Maximum_value" 255 "Init.value/fault_value" ;
VAL_ 825 ADAS_LeLine1Crvt 63 "Straight_Lane" 127 "No_Display" ;
VAL_ 825 ADAS_LeLine1LnColor 0 "White" 1 "Yellow" 2 "Blue" 3 "Invalid" ;
VAL_ 825 ADAS_LeLine1LnTyp 0 "Unknown" 1 "SingleLine_Solid" 2 "SingleLine_dashed" 3 "SingleLine_BottsDots" 4 "DoubleLine_Solid_Dashed" 5 "DoubleLine_Dash_Dash" 6 "DoubleLine_Dash_Solid" 7 "DoubleLine_Solid_Solid" 8 "Road_Edge" 9 "Reserved" 10 "Reserved" 11 "Reserved" 12 "Reserved" 13 "Reserved" 14 "Reserved" 15 "Reserved" ;
VAL_ 825 ADAS_LeLine1Conf 0 "12_5_percent" 1 "25_percent" 2 "37_5_percent" 3 "50_percent" 4 "62_5_percent" 5 "75_percent" 6 "87_5_percent" 7 "100_percent" ;
VAL_ 827 ADAS_Obj1_ID 0 "No_Object_Detected" ;
VAL_ 827 ADAS_Obj1_Conf 0 "Low" 1 "High" ;
VAL_ 827 ADAS_Obj1_Height 0 "Toward_Ego_Vehicle" 1 "Awat_from_Ego_Vehicle" ;
VAL_ 827 ADAS_Obj1_LongDistSign 0 "Positive_Right" 1 "Negative_Left" ;
VAL_ 827 ADAS_Obj1_LatDistSign 0 "Positive_Right" 1 "Negative_Left" ;
VAL_ 827 ADAS_Obj1_Classification 0 "Car" 1 "Truck" 2 "Motorcycle" 3 "Bicycle" 4 "Pedestrian" 5 "Animal_(Not_implemented)" 6 "General_Object_Unknown_size" 7 "General_Object_Small" 8 "General_Object_Large" 9 "Reserved" 10 "Reserved" 11 "Reserved" 12 "Reserved" 13 "Reserved" 14 "Reserved" 15 "Reserved" ;
VAL_ 827 ADAS_VVP_ICC_Obj1BrkLght 0 "Off" 1 "On" ;
VAL_ 827 ADAS_Obj1_ClassConf 0 "25_percent" 1 "50_percent" 2 "75_percent" 3 "100_percent" ;
VAL_ 829 ADAS_Obj4_ID 0 "No_Object_Detected" ;
VAL_ 829 ADAS_Obj4_Conf 0 "Low" 1 "High" ;
VAL_ 829 ADAS_Obj4_Height 0 "Toward_Ego_Vehicle" 1 "Awat_from_Ego_Vehicle" ;
VAL_ 829 ADAS_Obj4_LongDistSign 0 "Positive_Right" 1 "Negative_Left" ;
VAL_ 829 ADAS_Obj4_LatDistSign 0 "Positive_Right" 1 "Negative_Left" ;
VAL_ 829 ADAS_Obj4_Classification 0 "Car" 1 "Truck" 2 "Motorcycle" 3 "Bicycle" 4 "Pedestrian" 5 "Animal_(Not_implemented)" 6 "General_Object_Unknown_size" 7 "General_Object_Small" 8 "General_Object_Large" 9 "Reserved" 10 "Reserved" 11 "Reserved" 12 "Reserved" 13 "Reserved" 14 "Reserved" 15 "Reserved" ;
VAL_ 829 ADAS_VVP_ICC_Obj4BrkLght 0 "Off" 1 "On" ;
VAL_ 829 ADAS_Obj4_ClassConf 0 "25_percent" 1 "50_percent" 2 "75_percent" 3 "100_percent" ;
VAL_ 831 ADAS_Obj7_ID 0 "No_Object_Detected" ;
VAL_ 831 ADAS_Obj7_Conf 0 "Low" 1 "High" ;
VAL_ 831 ADAS_Obj7_Height 0 "Toward_Ego_Vehicle" 1 "Awat_from_Ego_Vehicle" ;
VAL_ 831 ADAS_Obj7_LongDistSign 0 "Positive_Right" 1 "Negative_Left" ;
VAL_ 831 ADAS_Obj7_LatDistSign 0 "Positive_Right" 1 "Negative_Left" ;
VAL_ 831 ADAS_Obj7_Classification 0 "Car" 1 "Truck" 2 "Motorcycle" 3 "Bicycle" 4 "Pedestrian" 5 "Animal_(Not_implemented)" 6 "General_Object_Unknown_size" 7 "General_Object_Small" 8 "General_Object_Large" 9 "Reserved" 10 "Reserved" 11 "Reserved" 12 "Reserved" 13 "Reserved" 14 "Reserved" 15 "Reserved" ;
VAL_ 831 ADAS_VVP_ICC_Obj7BrkLght 0 "Off" 1 "On" ;
VAL_ 831 ADAS_Obj7_ClassConf 0 "25_percent" 1 "50_percent" 2 "75_percent" 3 "100_percent" ;
VAL_ 832 ADAS_LeLineColor 0 "Gray" 1 "White" 2 "Blue(Alc)" 3 "Red" ;
VAL_ 832 ADAS_RiLineColor 0 "Gray" 1 "White" 2 "Blue(Alc)" 3 "Red" ;
VAL_ 832 ADAS_LeLineDst 125 "Invalid" 126 "Invalid" 127 "Invalid" ;
VAL_ 832 ADAS_RiLineDst 125 "Invalid" 126 "Invalid" 127 "Invalid" ;
VAL_ 832 ADAS_LeLineFlash 0 "No_Flash" 1 "Flash" 2 "Reserved" 3 "Reserved" ;
VAL_ 832 ADAS_RiLineFlash 0 "No_Flash" 1 "Flash" 2 "Reserved" 3 "Reserved" ;
VAL_ 832 ADAS_LeLineTyp 0 "Default" 1 "Solid_Lane" 2 "Dashed_Lane(Alc)" 3 "Reserved" ;
VAL_ 832 ADAS_RiLineTyp 0 "Default" 1 "Solid_Lane" 2 "Dashed_Lane(Alc)" 3 "Reserved" ;
VAL_ 832 ADAS_LaneCrvt 63 "Straight_Lane" 127 "No_Display" ;
VAL_ 832 ADAS_FltIndcr 0 "Default" 1 "No_Fault" 2 "Fault" 3 "Dynamic_Calibration_Running" ;
VAL_ 834 ADAS_LatCtrl_LeTurnLampReq 0 "No_request" 1 "Request_On" 2 "Request_Off" 3 "Reserved" ;
VAL_ 834 ADAS_LatCtrl_RiTurnLampReq 0 "No_request" 1 "Request_On" 2 "Request_Off" 3 "Reserved" ;
VAL_ 834 ADAS_LatCtrl_HapticReq 0 "No_request" 1 "Haptic_warning" 2 "Reserved" 3 "Reserved" ;
VAL_ 834 ADAS_LatCtrl_HzrdLampReq 0 "No_hazard_warning" 1 "Hazard_warning_Request" 2 "Reserved" ;
VAL_ 834 ADAS_VehMovDir 0 "Not_moving" 1 "Moving_forwards" 2 "Moving_backwards" ;
VAL_ 834 ADAS_HOD_HandsOnWarnReq 0 "No_Req" 1 "Request_driver_hands-on_/_gentle" 2 "Request_driver_hands-on_/_firm" 3 "Request_driver_hands-on_/_urgent" ;
VAL_ 834 ADAS_DoorLockReq 0 "Inactive" 1 "No_request" 2 "Lock_Doors" 3 "Invalid" ;
VAL_ 834 ADAS_AVASReq 0 "Inactive" 1 "Tqurn_On_Sound" 2 "Turn_Off_Sound" 3 "Invalid" ;
VAL_ 834 ADAS_RAPAvl 0 "RAP_not_available" 1 "RAP_available" ;
VAL_ 834 ADAS_TPReplayAvl 0 "TP_Replay_not_available" 1 "TP_Replay_available" ;
VAL_ 834 ADAS_TPReplaySuc 0 "TP_Replay_failed" 1 "TP_Replay_completed" ;
VAL_ 834 ADAS_Sts_RAP 0 "off" 1 "init" 2 "standby" 3 "active" 4 "fault" ;
VAL_ 834 ADAS_Sts_TP 0 "Off" 1 "Init" 2 "Standby" 3 "Train" 4 "Replay" 5 "Fault" ;
VAL_ 834 ADAS_ExtLightReq 0 "No_request" 1 "activate_exterior_light" ;
VAL_ 834 ADAS_HODSts 0 "Invalid" 1 "Hands_On" 2 "Hands_Off" 3 "Energy_Saver" 4 "Not_Available" 5 "Reserved" 6 "Resrved" 7 "Reserved" ;
VAL_ 835 BCM_RemReqFb 0 "Idle" 1 "Successful" 2 "Failed" 3 "Processing" ;
VAL_ 835 BCM_APASwSts 0 "Not_active_Not_enabled" 1 "Active_enable" 2 "Reserved" 3 "Invalid" ;
VAL_ 835 BCM_FrntHoodLidSts 0 "Closed" 1 "Open" ;
VAL_ 835 BCM_SunroofAntipinchSts 0 "Inactive" 1 "Active" ;
VAL_ 835 BCM_FrntDrDoorLockSts 0 "Lock" 1 "Unlock" ;
VAL_ 835 BCM_TrRelsSwtSts 0 "Inactive" 1 "Active" ;
VAL_ 835 BCM_LockAllDoorCmd 0 "Inactive" 1 "Active" ;
VAL_ 835 BCM_DrFrntDoorSts 0 "Closed" 1 "Open" ;
VAL_ 835 BCM_PasFrntDoorSts 0 "Closed" 1 "Open" ;
VAL_ 835 BCM_AntithftSts 0 "Anti_Theft_system_Unset" 1 "Anti_Theft_system_Partially_Set" 2 "Anti_Theft_system_Set" 3 "Anti_Theft_alarm_triggered" ;
VAL_ 835 BCM_CenLockSwtSts 0 "Inactive" 1 "Unlock" 2 "Lock" 3 "Reserved" ;
VAL_ 835 BCM_DoorUnlockSetFb 0 "driver's_door" 1 "All_doors" ;
VAL_ 835 BCM_RiReDoorSts 0 "Closed" 1 "Open" ;
VAL_ 835 BCM_LeReDoorSts 0 "Closed" 1 "Open" ;
VAL_ 835 BCM_LeFrntWinSts 0 "Closed" 1 "Open" ;
VAL_ 835 BCM_RiFrntWinSts 0 "Closed" 1 "Open" ;
VAL_ 835 BCM_LeReWinSts 0 "Closed" 1 "Open" ;
VAL_ 835 BCM_RiReWinSt 0 "Closed" 1 "Open" ;
VAL_ 835 BCM_SunroofSts 0 "Closed" 1 "Open" ;
VAL_ 835 BCM_FolwMeSetStsFb 0 "Follow_Me_Closed" 1 "15" 2 "30" 3 "45" 4 "60" 5 "Reserved" 6 "Reserved" 7 "Reserved" ;
VAL_ 835 BCM_DrvrDoorUnlckOutpCmd 0 "Inactive" 1 "Active" ;
VAL_ 835 BCM_PassDoorUnlckOutpCmd 0 "Inactive" 1 "Active" ;
VAL_ 835 BCM_LeDRLOutpCmd 0 "Off" 1 "On" ;
VAL_ 835 BCM_RiDRLOutpCmd 0 "Off" 1 "On" ;
VAL_ 835 BCM_ArmedClsWinSetSts 0 "Inactive" 1 "Active" ;
VAL_ 835 BCM_OffAutoUnlckSetSts 0 "Inactive" 1 "Active" ;
VAL_ 835 BCM_WarnVbrnSts 0 "Not_Active" 1 "Active" ;
VAL_ 835 BCM_SunroofOpenAr 0 "Horizontal_sliding_zone" 1 "Vertical_inclined_zone" ;
VAL_ 835 BCM_SteerWhlVbrnAlrmAvl 0 "Available" 1 "Not_Available_available" 2 "Failure_failed" 3 "Reserved" ;
VAL_ 835 BCM_SunroofRunngSts 0 "Stopped" 1 "Opening_Tilt" 2 "Closing_Tilt" 3 "Opening_Slide" 4 "Closing_Slide" 5 "Reversing_(AP/Stall)" 6 "Moving_Uninitialized" 7 "Reserved" ;
VAL_ 835 BCM_MirrCmd 0 "Inactive" 1 "Fold" 2 "Unfold" 3 "Not_Used" ;
VAL_ 843 ADAS_Obj2_ID 0 "No_Object_Detected" ;
VAL_ 843 ADAS_Obj2_Conf 0 "Low" 1 "High" ;
VAL_ 843 ADAS_Obj2_Height 0 "Toward_Ego_Vehicle" 1 "Awat_from_Ego_Vehicle" ;
VAL_ 843 ADAS_Obj2_LongDistSign 0 "Positive_Right" 1 "Negative_Left" ;
VAL_ 843 ADAS_Obj2_LatDistSign 0 "Positive_Right" 1 "Negative_Left" ;
VAL_ 843 ADAS_Obj2_Classification 0 "Car" 1 "Truck" 2 "Motorcycle" 3 "Bicycle" 4 "Pedestrian" 5 "Animal_(Not_implemented)" 6 "General_Object_Unknown_size" 7 "General_Object_Small" 8 "General_Object_Large" 9 "Reserved" 10 "Reserved" 11 "Reserved" 12 "Reserved" 13 "Reserved" 14 "Reserved" 15 "Reserved" ;
VAL_ 843 ADAS_VVP_ICC_Obj2BrkLght 0 "Off" 1 "On" ;
VAL_ 843 ADAS_Obj2_ClassConf 0 "25_percent" 1 "50_percent" 2 "75_percent" 3 "100_percent" ;
VAL_ 845 ADAS_Obj5_ID 0 "No_Object_Detected" ;
VAL_ 845 ADAS_Obj5_Conf 0 "Low" 1 "High" ;
VAL_ 845 ADAS_Obj5_Height 0 "Toward_Ego_Vehicle" 1 "Awat_from_Ego_Vehicle" ;
VAL_ 845 ADAS_Obj5_LongDistSign 0 "Positive_Right" 1 "Negative_Left" ;
VAL_ 845 ADAS_Obj5_LatDistSign 0 "Positive_Right" 1 "Negative_Left" ;
VAL_ 845 ADAS_Obj5_Classification 0 "Car" 1 "Truck" 2 "Motorcycle" 3 "Bicycle" 4 "Pedestrian" 5 "Animal_(Not_implemented)" 6 "General_Object_Unknown_size" 7 "General_Object_Small" 8 "General_Object_Large" 9 "Reserved" 10 "Reserved" 11 "Reserved" 12 "Reserved" 13 "Reserved" 14 "Reserved" 15 "Reserved" ;
VAL_ 845 ADAS_VVP_ICC_Obj5BrkLght 0 "Off" 1 "On" ;
VAL_ 845 ADAS_Obj5_ClassConf 0 "25_percent" 1 "50_percent" 2 "75_percent" 3 "100_percent" ;
VAL_ 847 ADAS_Obj8_ID 0 "No_Object_Detected" ;
VAL_ 847 ADAS_Obj8_Conf 0 "Low" 1 "High" ;
VAL_ 847 ADAS_Obj8_Height 0 "Toward_Ego_Vehicle" 1 "Awat_from_Ego_Vehicle" ;
VAL_ 847 ADAS_Obj8_LongDistSign 0 "Positive_Right" 1 "Negative_Left" ;
VAL_ 847 ADAS_Obj8_LatDistSign 0 "Positive_Right" 1 "Negative_Left" ;
VAL_ 847 ADAS_Obj8_Classification 0 "Car" 1 "Truck" 2 "Motorcycle" 3 "Bicycle" 4 "Pedestrian" 5 "Animal_(Not_implemented)" 6 "General_Object_Unknown_size" 7 "General_Object_Small" 8 "General_Object_Large" 9 "Reserved" 10 "Reserved" 11 "Reserved" 12 "Reserved" 13 "Reserved" 14 "Reserved" 15 "Reserved" ;
VAL_ 847 ADAS_VVP_ICC_Obj8BrkLght 0 "Off" 1 "On" ;
VAL_ 847 ADAS_Obj8_ClassConf 0 "25_percent" 1 "50_percent" 2 "75_percent" 3 "100_percent" ;
VAL_ 848 ADAS_LeftLaneType 0 "Lane" 1 "Raod_Edge" 2 "Barrier" 3 "Exit" ;
VAL_ 848 ADAS_RightLaneType 0 "Lane" 1 "Raod_Edge" 2 "Barrier" 3 "Exit" ;
VAL_ 848 ADAS_LandmarkType 0 "Bridge" 1 "Tunnel" 2 "Tollbooth" 3 "Gate" 4 "Traffic_Light" ;
VAL_ 848 ADAS_LaneMarkingType 0 "Intersection_Stop_Line" 1 "Intersection_Crosswalk" 2 "Crosswalk" 3 "Bicycle_Lane" 4 "Carpool_Lane" ;
VAL_ 848 ADAS_ConstructionObjectType 0 "Barrel" 1 "Cone" 2 "Fishbone_Left" 3 "Fishbone_Right" 4 "Obstruction_Left" 5 "Obstruction_Right" ;
VAL_ 848 ADAS_LeLn1TrffcDir 0 "Oncoming_Traffic" 1 "Not_Oncoming" ;
VAL_ 848 ADAS_LeLn2TrffcDir 0 "Oncoming_Traffic" 1 "Not_Oncoming" ;
VAL_ 848 ADAS_RiLn1TrffcDir 0 "Oncoming_Traffic" 1 "Not_Oncoming" ;
VAL_ 848 ADAS_RiLn2TrffcDir 0 "Oncoming_Traffic" 1 "Not_Oncoming" ;
VAL_ 849 ADAS_LdngVhclTurnSig 0 "none" 1 "Right_Turn" 2 "Left_Turn" 3 "Hazard" ;
VAL_ 849 ADAS_LdngVhclBrkLi 0 "FALSE" 1 "TRUE" ;
VAL_ 849 ADAS_HzdDetected 0 "TRUE" 1 "FALSE" ;
VAL_ 850 ADAS_USS_B0 0 "Off" 1 "Zone_1" 2 "Zone_2" 3 "Zone_3" 4 "Zone_4" 5 "Zone_5" 6 "Zone_6" 7 "Zone_7" 8 "Zone_8" 9 "No_Obstacle_Detected" 10 "Unused" 11 "Unused" 12 "Unused" 13 "Unused" 14 "Unused" 15 "FAULT" ;
VAL_ 850 ADAS_USS_F0 0 "Off" 1 "Zone_1" 2 "Zone_2" 3 "Zone_3" 4 "Zone_4" 5 "Unused" 6 "Unused" 7 "Unused" 8 "Unused" 9 "No_Obstacle_Detected" 10 "Unused" 11 "Unused" 12 "Unused" 13 "Unused" 14 "Unused" 15 "FAULT" ;
VAL_ 850 ADAS_USS_B1 0 "Off" 1 "Zone_1" 2 "Zone_2" 3 "Zone_3" 4 "Zone_4" 5 "Zone_5" 6 "Zone_6" 7 "Zone_7" 8 "Zone_8" 9 "No_Obstacle_Detected" 10 "Unused" 11 "Unused" 12 "Unused" 13 "Unused" 14 "Unused" 15 "FAULT" ;
VAL_ 850 ADAS_USS_F1 0 "Off" 1 "Zone_1" 2 "Zone_2" 3 "Zone_3" 4 "Zone_4" 5 "Unused" 6 "Unused" 7 "Unused" 8 "Unused" 9 "No_Obstacle_Detected" 10 "Unused" 11 "Unused" 12 "Unused" 13 "Unused" 14 "Unused" 15 "FAULT" ;
VAL_ 850 ADAS_USS_B2 0 "Off" 1 "Zone_1" 2 "Zone_2" 3 "Zone_3" 4 "Zone_4" 5 "Zone_5" 6 "Zone_6" 7 "Zone_7" 8 "Zone_8" 9 "No_Obstacle_Detected" 10 "Unused" 11 "Unused" 12 "Unused" 13 "Unused" 14 "Unused" 15 "FAULT" ;
VAL_ 850 ADAS_USS_F2 0 "Off" 1 "Zone_1" 2 "Zone_2" 3 "Zone_3" 4 "Zone_4" 5 "Unused" 6 "Unused" 7 "Unused" 8 "Unused" 9 "No_Obstacle_Detected" 10 "Unused" 11 "Unused" 12 "Unused" 13 "Unused" 14 "Unused" 15 "FAULT" ;
VAL_ 850 ADAS_USS_B3 0 "Off" 1 "Zone_1" 2 "Zone_2" 3 "Zone_3" 4 "Zone_4" 5 "Zone_5" 6 "Zone_6" 7 "Zone_7" 8 "Zone_8" 9 "No_Obstacle_Detected" 10 "Unused" 11 "Unused" 12 "Unused" 13 "Unused" 14 "Unused" 15 "FAULT" ;
VAL_ 850 ADAS_USS_F3 0 "Off" 1 "Zone_1" 2 "Zone_2" 3 "Zone_3" 4 "Zone_4" 5 "Unused" 6 "Unused" 7 "Unused" 8 "Unused" 9 "No_Obstacle_Detected" 10 "Unused" 11 "Unused" 12 "Unused" 13 "Unused" 14 "Unused" 15 "FAULT" ;
VAL_ 850 ADAS_USS_L0 0 "Off" 1 "Zone_1" 2 "Zone_2" 3 "Zone_3" 4 "Zone_4" 5 "Unused" 6 "Unused" 7 "Unused" 8 "Unused" 9 "No_Obstacle_Detected" 10 "Unused" 11 "Unused" 12 "Unused" 13 "Unused" 14 "Unused" 15 "FAULT" ;
VAL_ 850 ADAS_USS_L1 0 "Off" 1 "Zone_1" 2 "Zone_2" 3 "Zone_3" 4 "Zone_4" 5 "Unused" 6 "Unused" 7 "Unused" 8 "Unused" 9 "No_Obstacle_Detected" 10 "Unused" 11 "Unused" 12 "Unused" 13 "Unused" 14 "Unused" 15 "FAULT" ;
VAL_ 850 ADAS_USS_L2 0 "Off" 1 "Zone_1" 2 "Zone_2" 3 "Zone_3" 4 "Zone_4" 5 "Unused" 6 "Unused" 7 "Unused" 8 "Unused" 9 "No_Obstacle_Detected" 10 "Unused" 11 "Unused" 12 "Unused" 13 "Unused" 14 "Unused" 15 "FAULT" ;
VAL_ 850 ADAS_USS_L3 0 "Off" 1 "Zone_1" 2 "Zone_2" 3 "Zone_3" 4 "Zone_4" 5 "Unused" 6 "Unused" 7 "Unused" 8 "Unused" 9 "No_Obstacle_Detected" 10 "Unused" 11 "Unused" 12 "Unused" 13 "Unused" 14 "Unused" 15 "FAULT" ;
VAL_ 850 ADAS_USS_R0 0 "Off" 1 "Zone_1" 2 "Zone_2" 3 "Zone_3" 4 "Zone_4" 5 "Unused" 6 "Unused" 7 "Unused" 8 "Unused" 9 "No_Obstacle_Detected" 10 "Unused" 11 "Unused" 12 "Unused" 13 "Unused" 14 "Unused" 15 "FAULT" ;
VAL_ 850 ADAS_USS_R1 0 "Off" 1 "Zone_1" 2 "Zone_2" 3 "Zone_3" 4 "Zone_4" 5 "Unused" 6 "Unused" 7 "Unused" 8 "Unused" 9 "No_Obstacle_Detected" 10 "Unused" 11 "Unused" 12 "Unused" 13 "Unused" 14 "Unused" 15 "FAULT" ;
VAL_ 850 ADAS_USS_R2 0 "Off" 1 "Zone_1" 2 "Zone_2" 3 "Zone_3" 4 "Zone_4" 5 "Unused" 6 "Unused" 7 "Unused" 8 "Unused" 9 "No_Obstacle_Detected" 10 "Unused" 11 "Unused" 12 "Unused" 13 "Unused" 14 "Unused" 15 "FAULT" ;
VAL_ 850 ADAS_USS_R3 0 "Off" 1 "Zone_1" 2 "Zone_2" 3 "Zone_3" 4 "Zone_4" 5 "Unused" 6 "Unused" 7 "Unused" 8 "Unused" 9 "No_Obstacle_Detected" 10 "Unused" 11 "Unused" 12 "Unused" 13 "Unused" 14 "Unused" 15 "FAULT" ;
VAL_ 851 ADAS_VwPrtCamAngl 0 "Default" 1 "Normal_driving_angle_1" 2 "Normal_driving_angle_2" 3 "Normal_driving_angle_3" 4 "Turning_angle_1" 5 "Turning_angle_2" 6 "Turning_angle_3" 7 "Parking_angle_1" 8 "Parking_angle_2" 9 "Parking_angle_3" 10 "0xF:_Reserved" ;
VAL_ 854 ADAS_ObjDst_FLS 255 "No_Object" ;
VAL_ 854 ADAS_ObjDst_FLC 255 "No_Object" ;
VAL_ 854 ADAS_ObjDst_FLM 255 "No_Object" ;
VAL_ 854 ADAS_ObjDst_FRS 255 "No_Object" ;
VAL_ 854 ADAS_ObjDst_FRC 255 "No_Object" ;
VAL_ 854 ADAS_ObjDst_FRM 255 "No_Object" ;
VAL_ 856 VCU_KickdwnFlg 0 "Inactive" 1 "Active" 3 "Invalid" ;
VAL_ 856 VCU_EPedlEnaSig 0 "Not_enabled" 1 "Enable" ;
VAL_ 856 VCU_ComLostFlt_ESP 0 "Normal" 1 "Abnormal" ;
VAL_ 856 VCU_ComFlt_iBooster 0 "Normal" 1 "Abnormal" ;
VAL_ 856 VCU_RegenLvlFb 0 "Off" 1 "Normal" 2 "High" 3 "Invalid" ;
VAL_ 856 VCU_AccelModFb 0 "Low" 1 "Medium_" 2 "High" 3 "Invalid" ;
VAL_ 856 VCU_EPedlStsFb 0 "OnePedalDrive" 1 "Roll" 2 "Creep" 3 "Invalid" ;
VAL_ 856 VCU_CcTrgSpdDisp 255 "no_display" ;
VAL_ 856 VCU_Sts_CC_ICC 0 "Off" 1 "Initialization" 2 "Standby" 3 "Active" 4 "Override" 5 "Reserved" 6 "Reserved" 7 "Deactivation_brake" 8 "Deactivation_other" 9 "Failure_reversible" 10 "Failure_irreversible" 11 "Reserved" 12 "Reserved" 13 "Reserved" 14 "Reserved" 15 "Reserved" ;
VAL_ 856 VCU_CCIconDisp 0 "No_Display" 1 "White" 2 "Green" 3 "Fault" 4 "Reserved" 5 "Reserved" 6 "Reserved" 7 "Reserved" ;
VAL_ 856 VCU_DispSpdUnit_CC 0 "KMH" 1 "MPH" ;
VAL_ 856 VCU_BoostEnStat 0 "Default" 1 "Boost_unavailable:_Max_activation_number_exceeded" 2 "Boost_unavailable:_Drive_Mode" 3 "Boost_unavailable:_EDU_Coolant_Inlet_Temperature" 4 "Boost_unavailable:_EDU_Coolant_Flow" 5 "Boost_unavailable:_EDU_Stator/_Rotor_Temperature" 6 "Boost_unavailable:_EDU_Decoupling_Unit_open" 7 "Boost_unavailable:_Battery_limitation" 8 "Boost_available" 9 "Boost_active" 10 "Boost_unavailable:_vehicle_not_in_standstil" 11 "Boost_unavailable:_multiple_causes" 15 "invalid" ;
VAL_ 856 VCU_OTARdy_Fb 0 "Initial" 1 "Ready" 2 "Not_Ready" 3 "Invalid" ;
VAL_ 856 VCU_OTA_ECUInhb_Req 0 "Init" 1 "Inhibit_Request" 2 "No_Inhibit_request" 3 "Invalid" ;
VAL_ 856 VCU_OTAVehCdnChk_ASIL 0 "OTA_veh_cond_not_ok" 1 "OTA_veh_cond_ok" 2 "Fault" 3 "Invalid" ;
VAL_ 856 VCU_OTAVehInhb_ASIL_Fb 0 "Inhibition_not_ok" 1 "Inhibition_ok" 2 "Reserved" 3 "Invalid" ;
VAL_ 857 ADAS_ObjDst_RLS 255 "No_Object" ;
VAL_ 857 ADAS_ObjDst_RLC 255 "No_Object" ;
VAL_ 857 ADAS_ObjDst_RLM 255 "No_Object" ;
VAL_ 857 ADAS_ObjDst_RRS 255 "No_Object" ;
VAL_ 857 ADAS_ObjDst_RRC 255 "No_Object" ;
VAL_ 857 ADAS_ObjDst_RRM 255 "No_Object" ;
VAL_ 859 ICC_ViewReq 0 "None" 1 "Front_Normal_View" 2 "Left_Flank_3D_view" 3 "Right_Flank_3D_View" 4 "Rear_Normal_View" 5 "Curb_View_or_split_view" 6 "360_View_or_3D_Freefloating_view" 7 "Front_Cross_Path_View" 8 "Rear_Cross_Path_View" 9 "Reserved" 10 "Reserved" 11 "Reserved" 12 "Reserved" 13 "Reserved" 14 "Reserved" 15 "Reserved" ;
VAL_ 859 ICC_ShowSts 0 "Not_Show" 1 "Show" ;
VAL_ 859 ICC_SVS_AutoVwBttnReq 0 "Auto_camera_view_not_requested" 1 "Auto_camera_view_requested" ;
VAL_ 859 ICC_SVS_CamVwCnclReq 0 "Camera__view_port_exit_button_not_pressed" 1 "Camera__view_port_exit_button_pressed" ;
VAL_ 859 ICC_AutomaticViewReq 0 "Off" 1 "On" ;
VAL_ 859 ICC_360FreeFloatingReq 0 "Off" 1 "On" ;
VAL_ 859 ICC_GraphicOverlayReq 0 "Off" 1 "On" ;
VAL_ 859 ICC_OperationType 0 "No_Request" 1 "PINCH_ZOOM" 2 "QUICK_ZOOM_(double_tap)" 3 "PAN_(swipe)" ;
VAL_ 859 ICC_ZOOM_Start 0 "NO" 1 "Yes" ;
VAL_ 859 ICC_ZOOM_End 0 "NO" 1 "Yes" ;
VAL_ 859 ICC_EnbLnChgAsst 0 "Auto_steer_not_enabled" 1 "Auto_steer_enabled" ;
VAL_ 859 ICC_BSDSetting 0 "OFF" 1 "ON_with_Visual" 2 "ON_with_visual_and_audio" 3 "ON_with_visual_and_audio_and_Steering_Wheel_Vibration" ;
VAL_ 859 ICC_DOW_Setting 0 "OFF" 1 "ON_with_Visual" 2 "ON_with_visual_and_audio" 3 "Reserved" ;
VAL_ 859 ICC_DCAASetting 0 "OFF" 1 "ON" 2 "Reserved" 3 "Reserved" ;
VAL_ 859 ICC_APA_Setting 0 "Coded_off_(not_equipped)" 1 "Off_(by_user)" 2 "Enabled" 3 "Reserved" ;
VAL_ 859 ICC_APAParkSelect 0 "Slot_not_selected" 1 "Slot_1" 2 "Slot_2" 3 "Slot_3" 4 "Slot_4" 5 "Slot_5" 6 "Slot_6" 7 "Resreved" 8 "Resreved" 9 "Resreved" 10 "Resreved" 11 "Resreved" 12 "Resreved" 13 "Resreved" 14 "Resreved" 15 "Resreved" ;
VAL_ 859 ICC_APAActivation 0 "Cancel" 1 "On" ;
VAL_ 859 ICC_APAParkInDirSetting 0 "Nose-in" 1 "Back-in" ;
VAL_ 859 ICC_APAParkOutDirSetting 0 "Right" 1 "Left" ;
VAL_ 859 ICC_ParkAsstChmAlrt 0 "Off" 1 "On" ;
VAL_ 859 ICC_WSPPA_Setting 0 "No_curb_protection" 1 "Warning_only" 2 "Braking_intervention" 3 "Reserved" ;
VAL_ 859 ICC_AHBA_Setting 0 "Off" 1 "On" ;
VAL_ 859 ICC_APAParkOutAct 0 "No_request" 1 "Request" ;
VAL_ 859 ICC_SteerWhlVibrSet 0 "Off" 1 "On" ;
VAL_ 859 ICC_WarnTypeSetting 0 "OFF" 1 "ON_with_Visual" 2 "ON_with_visual_and_audio" 3 "ON_with_visual_and_audio_and_Steering_Wheel_Vibration" ;
VAL_ 859 ICC_LKA_SettingWrnTyp 0 "Audio_Visual_and_Haptic" 1 "Visual_and_Audio" 2 "Reserved" 3 "Reserved" ;
VAL_ 859 ICC_RAP_Setting 0 "Remote_Automated_Parking_Disabled" 1 "Remote_Automated_Parking_Enabled" 2 "Reserved" 3 "Reserved" ;
VAL_ 859 ICC_TP_Setting 0 "Trained_Parking_Disabled" 1 "Trained_Parking_Enabled" 2 "Reserved" 3 "Reserved" ;
VAL_ 859 ICC_BSD_Sensitivity 0 "Normal" 1 "Early" 2 "Late_or_reduced" 3 "Reserved" ;
VAL_ 865 ICC_PosnOffset 8191 "Invalid" ;
VAL_ 865 ICC_PosnMsgTye 0 "System_Specific" 1 "Position" 2 "Segment" 3 "Stub" 4 "Profile_Short" 5 "Profile_Long" 6 "Meta-data" 7 "Reserved" ;
VAL_ 865 ICC_PosnAge 0 "0~2545ms" 1 "0~2545ms" 2 "0~2545ms" 3 "0~2545ms" 4 "0~2545ms" 5 "0~2545ms" 6 "0~2545ms" 7 "0~2545ms" 8 "0~2545ms" 9 "0~2545ms" 10 "0~2545ms" 11 "0~2545ms" 12 "0~2545ms" 13 "0~2545ms" 14 "0~2545ms" 15 "0~2545ms" 16 "0~2545ms" 17 "0~2545ms" 18 "0~2545ms" 19 "0~2545ms" 20 "0~2545ms" 21 "0~2545ms" 22 "0~2545ms" 23 "0~2545ms" 24 "0~2545ms" 25 "0~2545ms" 26 "0~2545ms" 27 "0~2545ms" 28 "0~2545ms" 29 "0~2545ms" 30 "0~2545ms" 31 "0~2545ms" 32 "0~2545ms" 33 "0~2545ms" 34 "0~2545ms" 35 "0~2545ms" 36 "0~2545ms" 37 "0~2545ms" 38 "0~2545ms" 39 "0~2545ms" 40 "0~2545ms" 41 "0~2545ms" 42 "0~2545ms" 43 "0~2545ms" 44 "0~2545ms" 45 "0~2545ms" 46 "0~2545ms" 47 "0~2545ms" 48 "0~2545ms" 49 "0~2545ms" 50 "0~2545ms" 51 "0~2545ms" 52 "0~2545ms" 53 "0~2545ms" 54 "0~2545ms" 55 "0~2545ms" 56 "0~2545ms" 57 "0~2545ms" 58 "0~2545ms" 59 "0~2545ms" 60 "0~2545ms" 61 "0~2545ms" 62 "0~2545ms" 63 "0~2545ms" 64 "0~2545ms" 65 "0~2545ms" 66 "0~2545ms" 67 "0~2545ms" 68 "0~2545ms" 69 "0~2545ms" 70 "0~2545ms" 71 "0~2545ms" 72 "0~2545ms" 73 "0~2545ms" 74 "0~2545ms" 75 "0~2545ms" 76 "0~2545ms" 77 "0~2545ms" 78 "0~2545ms" 79 "0~2545ms" 80 "0~2545ms" 81 "0~2545ms" 82 "0~2545ms" 83 "0~2545ms" 84 "0~2545ms" 85 "0~2545ms" 86 "0~2545ms" 87 "0~2545ms" 88 "0~2545ms" 89 "0~2545ms" 90 "0~2545ms" 91 "0~2545ms" 92 "0~2545ms" 93 "0~2545ms" 94 "0~2545ms" 95 "0~2545ms" 96 "0~2545ms" 97 "0~2545ms" 98 "0~2545ms" 99 "0~2545ms" 100 "0~2545ms" 101 "0~2545ms" 102 "0~2545ms" 103 "0~2545ms" 104 "0~2545ms" 105 "0~2545ms" 106 "0~2545ms" 107 "0~2545ms" 108 "0~2545ms" 109 "0~2545ms" 110 "0~2545ms" 111 "0~2545ms" 112 "0~2545ms" 113 "0~2545ms" 114 "0~2545ms" 115 "0~2545ms" 116 "0~2545ms" 117 "0~2545ms" 118 "0~2545ms" 119 "0~2545ms" 120 "0~2545ms" 121 "0~2545ms" 122 "0~2545ms" 123 "0~2545ms" 124 "0~2545ms" 125 "0~2545ms" 126 "0~2545ms" 127 "0~2545ms" 128 "0~2545ms" 129 "0~2545ms" 130 "0~2545ms" 131 "0~2545ms" 132 "0~2545ms" 133 "0~2545ms" 134 "0~2545ms" 135 "0~2545ms" 136 "0~2545ms" 137 "0~2545ms" 138 "0~2545ms" 139 "0~2545ms" 140 "0~2545ms" 141 "0~2545ms" 142 "0~2545ms" 143 "0~2545ms" 144 "0~2545ms" 145 "0~2545ms" 146 "0~2545ms" 147 "0~2545ms" 148 "0~2545ms" 149 "0~2545ms" 150 "0~2545ms" 151 "0~2545ms" 152 "0~2545ms" 153 "0~2545ms" 154 "0~2545ms" 155 "0~2545ms" 156 "0~2545ms" 157 "0~2545ms" 158 "0~2545ms" 159 "0~2545ms" 160 "0~2545ms" 161 "0~2545ms" 162 "0~2545ms" 163 "0~2545ms" 164 "0~2545ms" 165 "0~2545ms" 166 "0~2545ms" 167 "0~2545ms" 168 "0~2545ms" 169 "0~2545ms" 170 "0~2545ms" 171 "0~2545ms" 172 "0~2545ms" 173 "0~2545ms" 174 "0~2545ms" 175 "0~2545ms" 176 "0~2545ms" 177 "0~2545ms" 178 "0~2545ms" 179 "0~2545ms" 180 "0~2545ms" 181 "0~2545ms" 182 "0~2545ms" 183 "0~2545ms" 184 "0~2545ms" 185 "0~2545ms" 186 "0~2545ms" 187 "0~2545ms" 188 "0~2545ms" 189 "0~2545ms" 190 "0~2545ms" 191 "0~2545ms" 192 "0~2545ms" 193 "0~2545ms" 194 "0~2545ms" 195 "0~2545ms" 196 "0~2545ms" 197 "0~2545ms" 198 "0~2545ms" 199 "0~2545ms" 200 "0~2545ms" 201 "0~2545ms" 202 "0~2545ms" 203 "0~2545ms" 204 "0~2545ms" 205 "0~2545ms" 206 "0~2545ms" 207 "0~2545ms" 208 "0~2545ms" 209 "0~2545ms" 210 "0~2545ms" 211 "0~2545ms" 212 "0~2545ms" 213 "0~2545ms" 214 "0~2545ms" 215 "0~2545ms" 216 "0~2545ms" 217 "0~2545ms" 218 "0~2545ms" 219 "0~2545ms" 220 "0~2545ms" 221 "0~2545ms" 222 "0~2545ms" 223 "0~2545ms" 224 "0~2545ms" 225 "0~2545ms" 226 "0~2545ms" 227 "0~2545ms" 228 "0~2545ms" 229 "0~2545ms" 230 "0~2545ms" 231 "0~2545ms" 232 "0~2545ms" 233 "0~2545ms" 234 "0~2545ms" 235 "0~2545ms" 236 "0~2545ms" 237 "0~2545ms" 238 "0~2545ms" 239 "0~2545ms" 240 "0~2545ms" 241 "0~2545ms" 242 "0~2545ms" 243 "0~2545ms" 244 "0~2545ms" 245 "0~2545ms" 246 "0~2545ms" 247 "0~2545ms" 248 "0~2545ms" 249 "0~2545ms" 250 "0~2545ms" 251 "0~2545ms" 252 "0~2545ms" 253 "0~2545ms" 254 "0~2545ms" 255 "0~2545ms" 256 "0~2545ms" 257 "0~2545ms" 258 "0~2545ms" 259 "0~2545ms" 260 "0~2545ms" 261 "0~2545ms" 262 "0~2545ms" 263 "0~2545ms" 264 "0~2545ms" 265 "0~2545ms" 266 "0~2545ms" 267 "0~2545ms" 268 "0~2545ms" 269 "0~2545ms" 270 "0~2545ms" 271 "0~2545ms" 272 "0~2545ms" 273 "0~2545ms" 274 "0~2545ms" 275 "0~2545ms" 276 "0~2545ms" 277 "0~2545ms" 278 "0~2545ms" 279 "0~2545ms" 280 "0~2545ms" 281 "0~2545ms" 282 "0~2545ms" 283 "0~2545ms" 284 "0~2545ms" 285 "0~2545ms" 286 "0~2545ms" 287 "0~2545ms" 288 "0~2545ms" 289 "0~2545ms" 290 "0~2545ms" 291 "0~2545ms" 292 "0~2545ms" 293 "0~2545ms" 294 "0~2545ms" 295 "0~2545ms" 296 "0~2545ms" 297 "0~2545ms" 298 "0~2545ms" 299 "0~2545ms" 300 "0~2545ms" 301 "0~2545ms" 302 "0~2545ms" 303 "0~2545ms" 304 "0~2545ms" 305 "0~2545ms" 306 "0~2545ms" 307 "0~2545ms" 308 "0~2545ms" 309 "0~2545ms" 310 "0~2545ms" 311 "0~2545ms" 312 "0~2545ms" 313 "0~2545ms" 314 "0~2545ms" 315 "0~2545ms" 316 "0~2545ms" 317 "0~2545ms" 318 "0~2545ms" 319 "0~2545ms" 320 "0~2545ms" 321 "0~2545ms" 322 "0~2545ms" 323 "0~2545ms" 324 "0~2545ms" 325 "0~2545ms" 326 "0~2545ms" 327 "0~2545ms" 328 "0~2545ms" 329 "0~2545ms" 330 "0~2545ms" 331 "0~2545ms" 332 "0~2545ms" 333 "0~2545ms" 334 "0~2545ms" 335 "0~2545ms" 336 "0~2545ms" 337 "0~2545ms" 338 "0~2545ms" 339 "0~2545ms" 340 "0~2545ms" 341 "0~2545ms" 342 "0~2545ms" 343 "0~2545ms" 344 "0~2545ms" 345 "0~2545ms" 346 "0~2545ms" 347 "0~2545ms" 348 "0~2545ms" 349 "0~2545ms" 350 "0~2545ms" 351 "0~2545ms" 352 "0~2545ms" 353 "0~2545ms" 354 "0~2545ms" 355 "0~2545ms" 356 "0~2545ms" 357 "0~2545ms" 358 "0~2545ms" 359 "0~2545ms" 360 "0~2545ms" 361 "0~2545ms" 362 "0~2545ms" 363 "0~2545ms" 364 "0~2545ms" 365 "0~2545ms" 366 "0~2545ms" 367 "0~2545ms" 368 "0~2545ms" 369 "0~2545ms" 370 "0~2545ms" 371 "0~2545ms" 372 "0~2545ms" 373 "0~2545ms" 374 "0~2545ms" 375 "0~2545ms" 376 "0~2545ms" 377 "0~2545ms" 378 "0~2545ms" 379 "0~2545ms" 380 "0~2545ms" 381 "0~2545ms" 382 "0~2545ms" 383 "0~2545ms" 384 "0~2545ms" 385 "0~2545ms" 386 "0~2545ms" 387 "0~2545ms" 388 "0~2545ms" 389 "0~2545ms" 390 "0~2545ms" 391 "0~2545ms" 392 "0~2545ms" 393 "0~2545ms" 394 "0~2545ms" 395 "0~2545ms" 396 "0~2545ms" 397 "0~2545ms" 398 "0~2545ms" 399 "0~2545ms" 400 "0~2545ms" 401 "0~2545ms" 402 "0~2545ms" 403 "0~2545ms" 404 "0~2545ms" 405 "0~2545ms" 406 "0~2545ms" 407 "0~2545ms" 408 "0~2545ms" 409 "0~2545ms" 410 "0~2545ms" 411 "0~2545ms" 412 "0~2545ms" 413 "0~2545ms" 414 "0~2545ms" 415 "0~2545ms" 416 "0~2545ms" 417 "0~2545ms" 418 "0~2545ms" 419 "0~2545ms" 420 "0~2545ms" 421 "0~2545ms" 422 "0~2545ms" 423 "0~2545ms" 424 "0~2545ms" 425 "0~2545ms" 426 "0~2545ms" 427 "0~2545ms" 428 "0~2545ms" 429 "0~2545ms" 430 "0~2545ms" 431 "0~2545ms" 432 "0~2545ms" 433 "0~2545ms" 434 "0~2545ms" 435 "0~2545ms" 436 "0~2545ms" 437 "0~2545ms" 438 "0~2545ms" 439 "0~2545ms" 440 "0~2545ms" 441 "0~2545ms" 442 "0~2545ms" 443 "0~2545ms" 444 "0~2545ms" 445 "0~2545ms" 446 "0~2545ms" 447 "0~2545ms" 448 "0~2545ms" 449 "0~2545ms" 450 "0~2545ms" 451 "0~2545ms" 452 "0~2545ms" 453 "0~2545ms" 454 "0~2545ms" 455 "0~2545ms" 456 "0~2545ms" 457 "0~2545ms" 458 "0~2545ms" 459 "0~2545ms" 460 "0~2545ms" 461 "0~2545ms" 462 "0~2545ms" 463 "0~2545ms" 464 "0~2545ms" 465 "0~2545ms" 466 "0~2545ms" 467 "0~2545ms" 468 "0~2545ms" 469 "0~2545ms" 470 "0~2545ms" 471 "0~2545ms" 472 "0~2545ms" 473 "0~2545ms" 474 "0~2545ms" 475 "0~2545ms" 476 "0~2545ms" 477 "0~2545ms" 478 "0~2545ms" 479 "0~2545ms" 480 "0~2545ms" 481 "0~2545ms" 482 "0~2545ms" 483 "0~2545ms" 484 "0~2545ms" 485 "0~2545ms" 486 "0~2545ms" 487 "0~2545ms" 488 "0~2545ms" 489 "0~2545ms" 490 "0~2545ms" 491 "0~2545ms" 492 "0~2545ms" 493 "0~2545ms" 494 "0~2545ms" 495 "0~2545ms" 496 "0~2545ms" 497 "0~2545ms" 498 "0~2545ms" 499 "0~2545ms" 500 "0~2545ms" 501 "0~2545ms" 502 "0~2545ms" 503 "0~2545ms" 504 "0~2545ms" 505 "0~2545ms" 506 "0~2545ms" 507 "0~2545ms" 508 "0~2545ms" 509 "0~2545ms" 510 ">2545ms" 511 "Invalid" ;
VAL_ 865 ICC_PosnPosProbb 0 "unknown" 31 "Invalid" ;
VAL_ 865 ICC_PosnSpd 0 "ï¿½ï¿½_-12.8_m/s_?" 1 "-12.6_-0.2_m/s" 2 "-12.6_-0.2_m/s" 3 "-12.6_-0.2_m/s" 4 "-12.6_-0.2_m/s" 5 "-12.6_-0.2_m/s" 6 "-12.6_-0.2_m/s" 7 "-12.6_-0.2_m/s" 8 "-12.6_-0.2_m/s" 9 "-12.6_-0.2_m/s" 10 "-12.6_-0.2_m/s" 11 "-12.6_-0.2_m/s" 12 "-12.6_-0.2_m/s" 13 "-12.6_-0.2_m/s" 14 "-12.6_-0.2_m/s" 15 "-12.6_-0.2_m/s" 16 "-12.6_-0.2_m/s" 17 "-12.6_-0.2_m/s" 18 "-12.6_-0.2_m/s" 19 "-12.6_-0.2_m/s" 20 "-12.6_-0.2_m/s" 21 "-12.6_-0.2_m/s" 22 "-12.6_-0.2_m/s" 23 "-12.6_-0.2_m/s" 24 "-12.6_-0.2_m/s" 25 "-12.6_-0.2_m/s" 26 "-12.6_-0.2_m/s" 27 "-12.6_-0.2_m/s" 28 "-12.6_-0.2_m/s" 29 "-12.6_-0.2_m/s" 30 "-12.6_-0.2_m/s" 31 "-12.6_-0.2_m/s" 32 "-12.6_-0.2_m/s" 33 "-12.6_-0.2_m/s" 34 "-12.6_-0.2_m/s" 35 "-12.6_-0.2_m/s" 36 "-12.6_-0.2_m/s" 37 "-12.6_-0.2_m/s" 38 "-12.6_-0.2_m/s" 39 "-12.6_-0.2_m/s" 40 "-12.6_-0.2_m/s" 41 "-12.6_-0.2_m/s" 42 "-12.6_-0.2_m/s" 43 "-12.6_-0.2_m/s" 44 "-12.6_-0.2_m/s" 45 "-12.6_-0.2_m/s" 46 "-12.6_-0.2_m/s" 47 "-12.6_-0.2_m/s" 48 "-12.6_-0.2_m/s" 49 "-12.6_-0.2_m/s" 50 "-12.6_-0.2_m/s" 51 "-12.6_-0.2_m/s" 52 "-12.6_-0.2_m/s" 53 "-12.6_-0.2_m/s" 54 "-12.6_-0.2_m/s" 55 "-12.6_-0.2_m/s" 56 "-12.6_-0.2_m/s" 57 "-12.6_-0.2_m/s" 58 "-12.6_-0.2_m/s" 59 "-12.6_-0.2_m/s" 60 "-12.6_-0.2_m/s" 61 "-12.6_-0.2_m/s" 62 "-12.6_-0.2_m/s" 63 "-12.6_-0.2_m/s" 64 "Standing_still" 65 "+0.2+89.0_m/s_?" 66 "+0.2+89.0_m/s_?" 67 "+0.2+89.0_m/s_?" 68 "+0.2+89.0_m/s_?" 69 "+0.2+89.0_m/s_?" 70 "+0.2+89.0_m/s_?" 71 "+0.2+89.0_m/s_?" 72 "+0.2+89.0_m/s_?" 73 "+0.2+89.0_m/s_?" 74 "+0.2+89.0_m/s_?" 75 "+0.2+89.0_m/s_?" 76 "+0.2+89.0_m/s_?" 77 "+0.2+89.0_m/s_?" 78 "+0.2+89.0_m/s_?" 79 "+0.2+89.0_m/s_?" 80 "+0.2+89.0_m/s_?" 81 "+0.2+89.0_m/s_?" 82 "+0.2+89.0_m/s_?" 83 "+0.2+89.0_m/s_?" 84 "+0.2+89.0_m/s_?" 85 "+0.2+89.0_m/s_?" 86 "+0.2+89.0_m/s_?" 87 "+0.2+89.0_m/s_?" 88 "+0.2+89.0_m/s_?" 89 "+0.2+89.0_m/s_?" 90 "+0.2+89.0_m/s_?" 91 "+0.2+89.0_m/s_?" 92 "+0.2+89.0_m/s_?" 93 "+0.2+89.0_m/s_?" 94 "+0.2+89.0_m/s_?" 95 "+0.2+89.0_m/s_?" 96 "+0.2+89.0_m/s_?" 97 "+0.2+89.0_m/s_?" 98 "+0.2+89.0_m/s_?" 99 "+0.2+89.0_m/s_?" 100 "+0.2+89.0_m/s_?" 101 "+0.2+89.0_m/s_?" 102 "+0.2+89.0_m/s_?" 103 "+0.2+89.0_m/s_?" 104 "+0.2+89.0_m/s_?" 105 "+0.2+89.0_m/s_?" 106 "+0.2+89.0_m/s_?" 107 "+0.2+89.0_m/s_?" 108 "+0.2+89.0_m/s_?" 109 "+0.2+89.0_m/s_?" 110 "+0.2+89.0_m/s_?" 111 "+0.2+89.0_m/s_?" 112 "+0.2+89.0_m/s_?" 113 "+0.2+89.0_m/s_?" 114 "+0.2+89.0_m/s_?" 115 "+0.2+89.0_m/s_?" 116 "+0.2+89.0_m/s_?" 117 "+0.2+89.0_m/s_?" 118 "+0.2+89.0_m/s_?" 119 "+0.2+89.0_m/s_?" 120 "+0.2+89.0_m/s_?" 121 "+0.2+89.0_m/s_?" 122 "+0.2+89.0_m/s_?" 123 "+0.2+89.0_m/s_?" 124 "+0.2+89.0_m/s_?" 125 "+0.2+89.0_m/s_?" 126 "+0.2+89.0_m/s_?" 127 "+0.2+89.0_m/s_?" 128 "+0.2+89.0_m/s_?" 129 "+0.2+89.0_m/s_?" 130 "+0.2+89.0_m/s_?" 131 "+0.2+89.0_m/s_?" 132 "+0.2+89.0_m/s_?" 133 "+0.2+89.0_m/s_?" 134 "+0.2+89.0_m/s_?" 135 "+0.2+89.0_m/s_?" 136 "+0.2+89.0_m/s_?" 137 "+0.2+89.0_m/s_?" 138 "+0.2+89.0_m/s_?" 139 "+0.2+89.0_m/s_?" 140 "+0.2+89.0_m/s_?" 141 "+0.2+89.0_m/s_?" 142 "+0.2+89.0_m/s_?" 143 "+0.2+89.0_m/s_?" 144 "+0.2+89.0_m/s_?" 145 "+0.2+89.0_m/s_?" 146 "+0.2+89.0_m/s_?" 147 "+0.2+89.0_m/s_?" 148 "+0.2+89.0_m/s_?" 149 "+0.2+89.0_m/s_?" 150 "+0.2+89.0_m/s_?" 151 "+0.2+89.0_m/s_?" 152 "+0.2+89.0_m/s_?" 153 "+0.2+89.0_m/s_?" 154 "+0.2+89.0_m/s_?" 155 "+0.2+89.0_m/s_?" 156 "+0.2+89.0_m/s_?" 157 "+0.2+89.0_m/s_?" 158 "+0.2+89.0_m/s_?" 159 "+0.2+89.0_m/s_?" 160 "+0.2+89.0_m/s_?" 161 "+0.2+89.0_m/s_?" 162 "+0.2+89.0_m/s_?" 163 "+0.2+89.0_m/s_?" 164 "+0.2+89.0_m/s_?" 165 "+0.2+89.0_m/s_?" 166 "+0.2+89.0_m/s_?" 167 "+0.2+89.0_m/s_?" 168 "+0.2+89.0_m/s_?" 169 "+0.2+89.0_m/s_?" 170 "+0.2+89.0_m/s_?" 171 "+0.2+89.0_m/s_?" 172 "+0.2+89.0_m/s_?" 173 "+0.2+89.0_m/s_?" 174 "+0.2+89.0_m/s_?" 175 "+0.2+89.0_m/s_?" 176 "+0.2+89.0_m/s_?" 177 "+0.2+89.0_m/s_?" 178 "+0.2+89.0_m/s_?" 179 "+0.2+89.0_m/s_?" 180 "+0.2+89.0_m/s_?" 181 "+0.2+89.0_m/s_?" 182 "+0.2+89.0_m/s_?" 183 "+0.2+89.0_m/s_?" 184 "+0.2+89.0_m/s_?" 185 "+0.2+89.0_m/s_?" 186 "+0.2+89.0_m/s_?" 187 "+0.2+89.0_m/s_?" 188 "+0.2+89.0_m/s_?" 189 "+0.2+89.0_m/s_?" 190 "+0.2+89.0_m/s_?" 191 "+0.2+89.0_m/s_?" 192 "+0.2+89.0_m/s_?" 193 "+0.2+89.0_m/s_?" 194 "+0.2+89.0_m/s_?" 195 "+0.2+89.0_m/s_?" 196 "+0.2+89.0_m/s_?" 197 "+0.2+89.0_m/s_?" 198 "+0.2+89.0_m/s_?" 199 "+0.2+89.0_m/s_?" 200 "+0.2+89.0_m/s_?" 201 "+0.2+89.0_m/s_?" 202 "+0.2+89.0_m/s_?" 203 "+0.2+89.0_m/s_?" 204 "+0.2+89.0_m/s_?" 205 "+0.2+89.0_m/s_?" 206 "+0.2+89.0_m/s_?" 207 "+0.2+89.0_m/s_?" 208 "+0.2+89.0_m/s_?" 209 "+0.2+89.0_m/s_?" 210 "+0.2+89.0_m/s_?" 211 "+0.2+89.0_m/s_?" 212 "+0.2+89.0_m/s_?" 213 "+0.2+89.0_m/s_?" 214 "+0.2+89.0_m/s_?" 215 "+0.2+89.0_m/s_?" 216 "+0.2+89.0_m/s_?" 217 "+0.2+89.0_m/s_?" 218 "+0.2+89.0_m/s_?" 219 "+0.2+89.0_m/s_?" 220 "+0.2+89.0_m/s_?" 221 "+0.2+89.0_m/s_?" 222 "+0.2+89.0_m/s_?" 223 "+0.2+89.0_m/s_?" 224 "+0.2+89.0_m/s_?" 225 "+0.2+89.0_m/s_?" 226 "+0.2+89.0_m/s_?" 227 "+0.2+89.0_m/s_?" 228 "+0.2+89.0_m/s_?" 229 "+0.2+89.0_m/s_?" 230 "+0.2+89.0_m/s_?" 231 "+0.2+89.0_m/s_?" 232 "+0.2+89.0_m/s_?" 233 "+0.2+89.0_m/s_?" 234 "+0.2+89.0_m/s_?" 235 "+0.2+89.0_m/s_?" 236 "+0.2+89.0_m/s_?" 237 "+0.2+89.0_m/s_?" 238 "+0.2+89.0_m/s_?" 239 "+0.2+89.0_m/s_?" 240 "+0.2+89.0_m/s_?" 241 "+0.2+89.0_m/s_?" 242 "+0.2+89.0_m/s_?" 243 "+0.2+89.0_m/s_?" 244 "+0.2+89.0_m/s_?" 245 "+0.2+89.0_m/s_?" 246 "+0.2+89.0_m/s_?" 247 "+0.2+89.0_m/s_?" 248 "+0.2+89.0_m/s_?" 249 "+0.2+89.0_m/s_?" 250 "+0.2+89.0_m/s_?" 251 "+0.2+89.0_m/s_?" 252 "+0.2+89.0_m/s_?" 253 "+0.2+89.0_m/s_?" 254 "+0.2+89.0_m/s_?" 255 "+0.2+89.0_m/s_?" 256 "+0.2+89.0_m/s_?" 257 "+0.2+89.0_m/s_?" 258 "+0.2+89.0_m/s_?" 259 "+0.2+89.0_m/s_?" 260 "+0.2+89.0_m/s_?" 261 "+0.2+89.0_m/s_?" 262 "+0.2+89.0_m/s_?" 263 "+0.2+89.0_m/s_?" 264 "+0.2+89.0_m/s_?" 265 "+0.2+89.0_m/s_?" 266 "+0.2+89.0_m/s_?" 267 "+0.2+89.0_m/s_?" 268 "+0.2+89.0_m/s_?" 269 "+0.2+89.0_m/s_?" 270 "+0.2+89.0_m/s_?" 271 "+0.2+89.0_m/s_?" 272 "+0.2+89.0_m/s_?" 273 "+0.2+89.0_m/s_?" 274 "+0.2+89.0_m/s_?" 275 "+0.2+89.0_m/s_?" 276 "+0.2+89.0_m/s_?" 277 "+0.2+89.0_m/s_?" 278 "+0.2+89.0_m/s_?" 279 "+0.2+89.0_m/s_?" 280 "+0.2+89.0_m/s_?" 281 "+0.2+89.0_m/s_?" 282 "+0.2+89.0_m/s_?" 283 "+0.2+89.0_m/s_?" 284 "+0.2+89.0_m/s_?" 285 "+0.2+89.0_m/s_?" 286 "+0.2+89.0_m/s_?" 287 "+0.2+89.0_m/s_?" 288 "+0.2+89.0_m/s_?" 289 "+0.2+89.0_m/s_?" 290 "+0.2+89.0_m/s_?" 291 "+0.2+89.0_m/s_?" 292 "+0.2+89.0_m/s_?" 293 "+0.2+89.0_m/s_?" 294 "+0.2+89.0_m/s_?" 295 "+0.2+89.0_m/s_?" 296 "+0.2+89.0_m/s_?" 297 "+0.2+89.0_m/s_?" 298 "+0.2+89.0_m/s_?" 299 "+0.2+89.0_m/s_?" 300 "+0.2+89.0_m/s_?" 301 "+0.2+89.0_m/s_?" 302 "+0.2+89.0_m/s_?" 303 "+0.2+89.0_m/s_?" 304 "+0.2+89.0_m/s_?" 305 "+0.2+89.0_m/s_?" 306 "+0.2+89.0_m/s_?" 307 "+0.2+89.0_m/s_?" 308 "+0.2+89.0_m/s_?" 309 "+0.2+89.0_m/s_?" 310 "+0.2+89.0_m/s_?" 311 "+0.2+89.0_m/s_?" 312 "+0.2+89.0_m/s_?" 313 "+0.2+89.0_m/s_?" 314 "+0.2+89.0_m/s_?" 315 "+0.2+89.0_m/s_?" 316 "+0.2+89.0_m/s_?" 317 "+0.2+89.0_m/s_?" 318 "+0.2+89.0_m/s_?" 319 "+0.2+89.0_m/s_?" 320 "+0.2+89.0_m/s_?" 321 "+0.2+89.0_m/s_?" 322 "+0.2+89.0_m/s_?" 323 "+0.2+89.0_m/s_?" 324 "+0.2+89.0_m/s_?" 325 "+0.2+89.0_m/s_?" 326 "+0.2+89.0_m/s_?" 327 "+0.2+89.0_m/s_?" 328 "+0.2+89.0_m/s_?" 329 "+0.2+89.0_m/s_?" 330 "+0.2+89.0_m/s_?" 331 "+0.2+89.0_m/s_?" 332 "+0.2+89.0_m/s_?" 333 "+0.2+89.0_m/s_?" 334 "+0.2+89.0_m/s_?" 335 "+0.2+89.0_m/s_?" 336 "+0.2+89.0_m/s_?" 337 "+0.2+89.0_m/s_?" 338 "+0.2+89.0_m/s_?" 339 "+0.2+89.0_m/s_?" 340 "+0.2+89.0_m/s_?" 341 "+0.2+89.0_m/s_?" 342 "+0.2+89.0_m/s_?" 343 "+0.2+89.0_m/s_?" 344 "+0.2+89.0_m/s_?" 345 "+0.2+89.0_m/s_?" 346 "+0.2+89.0_m/s_?" 347 "+0.2+89.0_m/s_?" 348 "+0.2+89.0_m/s_?" 349 "+0.2+89.0_m/s_?" 350 "+0.2+89.0_m/s_?" 351 "+0.2+89.0_m/s_?" 352 "+0.2+89.0_m/s_?" 353 "+0.2+89.0_m/s_?" 354 "+0.2+89.0_m/s_?" 355 "+0.2+89.0_m/s_?" 356 "+0.2+89.0_m/s_?" 357 "+0.2+89.0_m/s_?" 358 "+0.2+89.0_m/s_?" 359 "+0.2+89.0_m/s_?" 360 "+0.2+89.0_m/s_?" 361 "+0.2+89.0_m/s_?" 362 "+0.2+89.0_m/s_?" 363 "+0.2+89.0_m/s_?" 364 "+0.2+89.0_m/s_?" 365 "+0.2+89.0_m/s_?" 366 "+0.2+89.0_m/s_?" 367 "+0.2+89.0_m/s_?" 368 "+0.2+89.0_m/s_?" 369 "+0.2+89.0_m/s_?" 370 "+0.2+89.0_m/s_?" 371 "+0.2+89.0_m/s_?" 372 "+0.2+89.0_m/s_?" 373 "+0.2+89.0_m/s_?" 374 "+0.2+89.0_m/s_?" 375 "+0.2+89.0_m/s_?" 376 "+0.2+89.0_m/s_?" 377 "+0.2+89.0_m/s_?" 378 "+0.2+89.0_m/s_?" 379 "+0.2+89.0_m/s_?" 380 "+0.2+89.0_m/s_?" 381 "+0.2+89.0_m/s_?" 382 "+0.2+89.0_m/s_?" 383 "+0.2+89.0_m/s_?" 384 "+0.2+89.0_m/s_?" 385 "+0.2+89.0_m/s_?" 386 "+0.2+89.0_m/s_?" 387 "+0.2+89.0_m/s_?" 388 "+0.2+89.0_m/s_?" 389 "+0.2+89.0_m/s_?" 390 "+0.2+89.0_m/s_?" 391 "+0.2+89.0_m/s_?" 392 "+0.2+89.0_m/s_?" 393 "+0.2+89.0_m/s_?" 394 "+0.2+89.0_m/s_?" 395 "+0.2+89.0_m/s_?" 396 "+0.2+89.0_m/s_?" 397 "+0.2+89.0_m/s_?" 398 "+0.2+89.0_m/s_?" 399 "+0.2+89.0_m/s_?" 400 "+0.2+89.0_m/s_?" 401 "+0.2+89.0_m/s_?" 402 "+0.2+89.0_m/s_?" 403 "+0.2+89.0_m/s_?" 404 "+0.2+89.0_m/s_?" 405 "+0.2+89.0_m/s_?" 406 "+0.2+89.0_m/s_?" 407 "+0.2+89.0_m/s_?" 408 "+0.2+89.0_m/s_?" 409 "+0.2+89.0_m/s_?" 410 "+0.2+89.0_m/s_?" 411 "+0.2+89.0_m/s_?" 412 "+0.2+89.0_m/s_?" 413 "+0.2+89.0_m/s_?" 414 "+0.2+89.0_m/s_?" 415 "+0.2+89.0_m/s_?" 416 "+0.2+89.0_m/s_?" 417 "+0.2+89.0_m/s_?" 418 "+0.2+89.0_m/s_?" 419 "+0.2+89.0_m/s_?" 420 "+0.2+89.0_m/s_?" 421 "+0.2+89.0_m/s_?" 422 "+0.2+89.0_m/s_?" 423 "+0.2+89.0_m/s_?" 424 "+0.2+89.0_m/s_?" 425 "+0.2+89.0_m/s_?" 426 "+0.2+89.0_m/s_?" 427 "+0.2+89.0_m/s_?" 428 "+0.2+89.0_m/s_?" 429 "+0.2+89.0_m/s_?" 430 "+0.2+89.0_m/s_?" 431 "+0.2+89.0_m/s_?" 432 "+0.2+89.0_m/s_?" 433 "+0.2+89.0_m/s_?" 434 "+0.2+89.0_m/s_?" 435 "+0.2+89.0_m/s_?" 436 "+0.2+89.0_m/s_?" 437 "+0.2+89.0_m/s_?" 438 "+0.2+89.0_m/s_?" 439 "+0.2+89.0_m/s_?" 440 "+0.2+89.0_m/s_?" 441 "+0.2+89.0_m/s_?" 442 "+0.2+89.0_m/s_?" 443 "+0.2+89.0_m/s_?" 444 "+0.2+89.0_m/s_?" 445 "+0.2+89.0_m/s_?" 446 "+0.2+89.0_m/s_?" 447 "+0.2+89.0_m/s_?" 448 "+0.2+89.0_m/s_?" 449 "+0.2+89.0_m/s_?" 450 "+0.2+89.0_m/s_?" 451 "+0.2+89.0_m/s_?" 452 "+0.2+89.0_m/s_?" 453 "+0.2+89.0_m/s_?" 454 "+0.2+89.0_m/s_?" 455 "+0.2+89.0_m/s_?" 456 "+0.2+89.0_m/s_?" 457 "+0.2+89.0_m/s_?" 458 "+0.2+89.0_m/s_?" 459 "+0.2+89.0_m/s_?" 460 "+0.2+89.0_m/s_?" 461 "+0.2+89.0_m/s_?" 462 "+0.2+89.0_m/s_?" 463 "+0.2+89.0_m/s_?" 464 "+0.2+89.0_m/s_?" 465 "+0.2+89.0_m/s_?" 466 "+0.2+89.0_m/s_?" 467 "+0.2+89.0_m/s_?" 468 "+0.2+89.0_m/s_?" 469 "+0.2+89.0_m/s_?" 470 "+0.2+89.0_m/s_?" 471 "+0.2+89.0_m/s_?" 472 "+0.2+89.0_m/s_?" 473 "+0.2+89.0_m/s_?" 474 "+0.2+89.0_m/s_?" 475 "+0.2+89.0_m/s_?" 476 "+0.2+89.0_m/s_?" 477 "+0.2+89.0_m/s_?" 478 "+0.2+89.0_m/s_?" 479 "+0.2+89.0_m/s_?" 480 "+0.2+89.0_m/s_?" 481 "+0.2+89.0_m/s_?" 482 "+0.2+89.0_m/s_?" 483 "+0.2+89.0_m/s_?" 484 "+0.2+89.0_m/s_?" 485 "+0.2+89.0_m/s_?" 486 "+0.2+89.0_m/s_?" 487 "+0.2+89.0_m/s_?" 488 "+0.2+89.0_m/s_?" 489 "+0.2+89.0_m/s_?" 490 "+0.2+89.0_m/s_?" 491 "+0.2+89.0_m/s_?" 492 "+0.2+89.0_m/s_?" 493 "+0.2+89.0_m/s_?" 494 "+0.2+89.0_m/s_?" 495 "+0.2+89.0_m/s_?" 496 "+0.2+89.0_m/s_?" 497 "+0.2+89.0_m/s_?" 498 "+0.2+89.0_m/s_?" 499 "+0.2+89.0_m/s_?" 500 "+0.2+89.0_m/s_?" 501 "+0.2+89.0_m/s_?" 502 "+0.2+89.0_m/s_?" 503 "+0.2+89.0_m/s_?" 504 "+0.2+89.0_m/s_?" 505 "+0.2+89.0_m/s_?" 506 "+0.2+89.0_m/s_?" 507 "+0.2+89.0_m/s_?" 508 "+0.2+89.0_m/s_?" 509 "+0.2+89.0_m/s_?" 510 "ï¿½ï¿½_+89.2_m/s_?" 511 "Invalid" ;
VAL_ 865 ICC_PosnCurLane 0 "Unknown" 1 "Emergency_lane" 2 "Single-lane_road" 3 "Left-most_lane" 4 "Right-most_lane" 5 "One_of_middle_lanes_on_road_with_three_or_more_lanes" 6 "Reserved" 7 "Invalid" ;
VAL_ 865 ICC_PosnPosConfdc 7 "Invalid" ;
VAL_ 865 ICC_PosnRehead 0 "In_Path_Direction" 1 "1.417_Degrees_Right" 2 "Right_From_Path_Direction" 3 "Right_From_Path_Direction" 4 "Right_From_Path_Direction" 5 "Right_From_Path_Direction" 6 "Right_From_Path_Direction" 7 "Right_From_Path_Direction" 8 "Right_From_Path_Direction" 9 "Right_From_Path_Direction" 10 "Right_From_Path_Direction" 11 "Right_From_Path_Direction" 12 "Right_From_Path_Direction" 13 "Right_From_Path_Direction" 14 "Right_From_Path_Direction" 15 "Right_From_Path_Direction" 16 "Right_From_Path_Direction" 17 "Right_From_Path_Direction" 18 "Right_From_Path_Direction" 19 "Right_From_Path_Direction" 20 "Right_From_Path_Direction" 21 "Right_From_Path_Direction" 22 "Right_From_Path_Direction" 23 "Right_From_Path_Direction" 24 "Right_From_Path_Direction" 25 "Right_From_Path_Direction" 26 "Right_From_Path_Direction" 27 "Right_From_Path_Direction" 28 "Right_From_Path_Direction" 29 "Right_From_Path_Direction" 30 "Right_From_Path_Direction" 31 "Right_From_Path_Direction" 32 "Right_From_Path_Direction" 33 "Right_From_Path_Direction" 34 "Right_From_Path_Direction" 35 "Right_From_Path_Direction" 36 "Right_From_Path_Direction" 37 "Right_From_Path_Direction" 38 "Right_From_Path_Direction" 39 "Right_From_Path_Direction" 40 "Right_From_Path_Direction" 41 "Right_From_Path_Direction" 42 "Right_From_Path_Direction" 43 "Right_From_Path_Direction" 44 "Right_From_Path_Direction" 45 "Right_From_Path_Direction" 46 "Right_From_Path_Direction" 47 "Right_From_Path_Direction" 48 "Right_From_Path_Direction" 49 "Right_From_Path_Direction" 50 "Right_From_Path_Direction" 51 "Right_From_Path_Direction" 52 "Right_From_Path_Direction" 53 "Right_From_Path_Direction" 54 "Right_From_Path_Direction" 55 "Right_From_Path_Direction" 56 "Right_From_Path_Direction" 57 "Right_From_Path_Direction" 58 "Right_From_Path_Direction" 59 "Right_From_Path_Direction" 60 "Right_From_Path_Direction" 61 "Right_From_Path_Direction" 62 "Right_From_Path_Direction" 63 "Right_From_Path_Direction" 64 "Right_From_Path_Direction" 65 "Right_From_Path_Direction" 66 "Right_From_Path_Direction" 67 "Right_From_Path_Direction" 68 "Right_From_Path_Direction" 69 "Right_From_Path_Direction" 70 "Right_From_Path_Direction" 71 "Right_From_Path_Direction" 72 "Right_From_Path_Direction" 73 "Right_From_Path_Direction" 74 "Right_From_Path_Direction" 75 "Right_From_Path_Direction" 76 "Right_From_Path_Direction" 77 "Right_From_Path_Direction" 78 "Right_From_Path_Direction" 79 "Right_From_Path_Direction" 80 "Right_From_Path_Direction" 81 "Right_From_Path_Direction" 82 "Right_From_Path_Direction" 83 "Right_From_Path_Direction" 84 "Right_From_Path_Direction" 85 "Right_From_Path_Direction" 86 "Right_From_Path_Direction" 87 "Right_From_Path_Direction" 88 "Right_From_Path_Direction" 89 "Right_From_Path_Direction" 90 "Right_From_Path_Direction" 91 "Right_From_Path_Direction" 92 "Right_From_Path_Direction" 93 "Right_From_Path_Direction" 94 "Right_From_Path_Direction" 95 "Right_From_Path_Direction" 96 "Right_From_Path_Direction" 97 "Right_From_Path_Direction" 98 "Right_From_Path_Direction" 99 "Right_From_Path_Direction" 100 "Right_From_Path_Direction" 101 "Right_From_Path_Direction" 102 "Right_From_Path_Direction" 103 "Right_From_Path_Direction" 104 "Right_From_Path_Direction" 105 "Right_From_Path_Direction" 106 "Right_From_Path_Direction" 107 "Right_From_Path_Direction" 108 "Right_From_Path_Direction" 109 "Right_From_Path_Direction" 110 "Right_From_Path_Direction" 111 "Right_From_Path_Direction" 112 "Right_From_Path_Direction" 113 "Right_From_Path_Direction" 114 "Right_From_Path_Direction" 115 "Right_From_Path_Direction" 116 "Right_From_Path_Direction" 117 "Right_From_Path_Direction" 118 "Right_From_Path_Direction" 119 "Right_From_Path_Direction" 120 "Right_From_Path_Direction" 121 "Right_From_Path_Direction" 122 "Right_From_Path_Direction" 123 "Right_From_Path_Direction" 124 "Right_From_Path_Direction" 125 "Right_From_Path_Direction" 126 "178.583_Degrees_Right" 127 "Opposite_Direction" 128 "178.583_Degrees_Left_(181.417_Degrees_Right)+R[6]C" 129 "Left_From_Path_Direction" 130 "Left_From_Path_Direction" 131 "Left_From_Path_Direction" 132 "Left_From_Path_Direction" 133 "Left_From_Path_Direction" 134 "Left_From_Path_Direction" 135 "Left_From_Path_Direction" 136 "Left_From_Path_Direction" 137 "Left_From_Path_Direction" 138 "Left_From_Path_Direction" 139 "Left_From_Path_Direction" 140 "Left_From_Path_Direction" 141 "Left_From_Path_Direction" 142 "Left_From_Path_Direction" 143 "Left_From_Path_Direction" 144 "Left_From_Path_Direction" 145 "Left_From_Path_Direction" 146 "Left_From_Path_Direction" 147 "Left_From_Path_Direction" 148 "Left_From_Path_Direction" 149 "Left_From_Path_Direction" 150 "Left_From_Path_Direction" 151 "Left_From_Path_Direction" 152 "Left_From_Path_Direction" 153 "Left_From_Path_Direction" 154 "Left_From_Path_Direction" 155 "Left_From_Path_Direction" 156 "Left_From_Path_Direction" 157 "Left_From_Path_Direction" 158 "Left_From_Path_Direction" 159 "Left_From_Path_Direction" 160 "Left_From_Path_Direction" 161 "Left_From_Path_Direction" 162 "Left_From_Path_Direction" 163 "Left_From_Path_Direction" 164 "Left_From_Path_Direction" 165 "Left_From_Path_Direction" 166 "Left_From_Path_Direction" 167 "Left_From_Path_Direction" 168 "Left_From_Path_Direction" 169 "Left_From_Path_Direction" 170 "Left_From_Path_Direction" 171 "Left_From_Path_Direction" 172 "Left_From_Path_Direction" 173 "Left_From_Path_Direction" 174 "Left_From_Path_Direction" 175 "Left_From_Path_Direction" 176 "Left_From_Path_Direction" 177 "Left_From_Path_Direction" 178 "Left_From_Path_Direction" 179 "Left_From_Path_Direction" 180 "Left_From_Path_Direction" 181 "Left_From_Path_Direction" 182 "Left_From_Path_Direction" 183 "Left_From_Path_Direction" 184 "Left_From_Path_Direction" 185 "Left_From_Path_Direction" 186 "Left_From_Path_Direction" 187 "Left_From_Path_Direction" 188 "Left_From_Path_Direction" 189 "Left_From_Path_Direction" 190 "Left_From_Path_Direction" 191 "Left_From_Path_Direction" 192 "Left_From_Path_Direction" 193 "Left_From_Path_Direction" 194 "Left_From_Path_Direction" 195 "Left_From_Path_Direction" 196 "Left_From_Path_Direction" 197 "Left_From_Path_Direction" 198 "Left_From_Path_Direction" 199 "Left_From_Path_Direction" 200 "Left_From_Path_Direction" 201 "Left_From_Path_Direction" 202 "Left_From_Path_Direction" 203 "Left_From_Path_Direction" 204 "Left_From_Path_Direction" 205 "Left_From_Path_Direction" 206 "Left_From_Path_Direction" 207 "Left_From_Path_Direction" 208 "Left_From_Path_Direction" 209 "Left_From_Path_Direction" 210 "Left_From_Path_Direction" 211 "Left_From_Path_Direction" 212 "Left_From_Path_Direction" 213 "Left_From_Path_Direction" 214 "Left_From_Path_Direction" 215 "Left_From_Path_Direction" 216 "Left_From_Path_Direction" 217 "Left_From_Path_Direction" 218 "Left_From_Path_Direction" 219 "Left_From_Path_Direction" 220 "Left_From_Path_Direction" 221 "Left_From_Path_Direction" 222 "Left_From_Path_Direction" 223 "Left_From_Path_Direction" 224 "Left_From_Path_Direction" 225 "Left_From_Path_Direction" 226 "Left_From_Path_Direction" 227 "Left_From_Path_Direction" 228 "Left_From_Path_Direction" 229 "Left_From_Path_Direction" 230 "Left_From_Path_Direction" 231 "Left_From_Path_Direction" 232 "Left_From_Path_Direction" 233 "Left_From_Path_Direction" 234 "Left_From_Path_Direction" 235 "Left_From_Path_Direction" 236 "Left_From_Path_Direction" 237 "Left_From_Path_Direction" 238 "Left_From_Path_Direction" 239 "Left_From_Path_Direction" 240 "Left_From_Path_Direction" 241 "Left_From_Path_Direction" 242 "Left_From_Path_Direction" 243 "Left_From_Path_Direction" 244 "Left_From_Path_Direction" 245 "Left_From_Path_Direction" 246 "Left_From_Path_Direction" 247 "Left_From_Path_Direction" 248 "Left_From_Path_Direction" 249 "Left_From_Path_Direction" 250 "Left_From_Path_Direction" 251 "Left_From_Path_Direction" 252 "Left_From_Path_Direction" 253 "1.417_Degrees_left_(358.583_Degrees_Right)" 254 "Unknown" 255 "Invalid" ;
VAL_ 866 ICC_MetaMapProvider 0 "Unknown" 1 "Nokia_HERE_(NAVTEQ)" 2 "TomTom_(Tele_Atlas)" 3 "Zenrin" 4 "IPC" 5 "NavInfo" 6 "Other" 7 "N/A" ;
VAL_ 866 ICC_MetaMsgType 0 "System_Specific" 1 "Position" 2 "Segment" 3 "Stub" 4 "Profile_Short" 5 "Profile_Long" 6 "Meta-data" 7 "Reserved" ;
VAL_ 866 ICC_MetaHwVer 0 "Unknown" ;
VAL_ 866 ICC_MetaDrvSide 0 "Driving_Side_Left" 1 "Driving_Side_Right_Default_is_0x1" ;
VAL_ 866 ICC_MetaSpdUnits 0 "Kilometers_Per_Hour_(km/h)" 1 "Miles_Per_Hour_(mph)_Default_is_0" ;
VAL_ 868 BCM_OTARdy_Fb 0 "Initial" 1 "Ready" 2 "Not_Ready" 3 "Invalid" ;
VAL_ 868 BCM_OTAInhbRdy 0 "Initial" 1 "Inhibit" 2 "Not_Inhibit" 3 "Invalid" ;
VAL_ 868 BCM_SBRMatStPass 0 "Seat_not_occupied" 1 "Seat_occupied" 2 "Fault" 3 "Invalid" ;
VAL_ 868 BCM_BucSwtSt2ndRowLeft 0 "Buckled" 1 "Not_buckled" 2 "Fault" 3 "Invalid" ;
VAL_ 868 BCM_BucSwtSt2ndRowMid 0 "Buckled" 1 "Not_buckled" 2 "Fault" 3 "Invalid" ;
VAL_ 868 BCM_BucSwtSt2ndRowRight 0 "Buckled" 1 "Not_buckled" 2 "Fault" 3 "Invalid" ;
VAL_ 868 BCM_BucSwtSt3rdRowLeft 0 "Buckled" 1 "Not_buckled" 2 "Fault" 3 "Invalid" ;
VAL_ 868 BCM_BucSwtSt3rdRowRight 0 "Buckled" 1 "Not_buckled" 2 "Fault" 3 "Invalid" ;
VAL_ 868 BCM_SBRMatSt2ndRowLeft 0 "Seat_not_occupied" 1 "Seat_occupied" 2 "Fault" 3 "Invalid" ;
VAL_ 868 BCM_SBRMatSt2ndRowMid 0 "Seat_not_occupied" 1 "Seat_occupied" 2 "Fault" 3 "Invalid" ;
VAL_ 868 BCM_SBRMatSt2ndRowRight 0 "Seat_not_occupied" 1 "Seat_occupied" 2 "Fault" 3 "Invalid" ;
VAL_ 868 BCM_SBRMat3rdRowLeft 0 "Seat_not_occupied" 1 "Seat_occupied" 2 "Fault" 3 "Invalid" ;
VAL_ 868 BCM_SBRMat3rdRowRight 0 "Seat_not_occupied" 1 "Seat_occupied" 2 "Fault" 3 "Invalid" ;
VAL_ 883 ECC_CrtSts 0 "Load_initialization" 1 "Low-voltage_state" 2 "Local_high_voltage_state" 3 "Local_charge_state" 4 "Remote_working_state" 5 "High_voltage_discharge_state" 6 "Delay_state" 7 "Reserved" 8 "Reserved" 9 "Reserved" 10 "Reserved" 11 "Reserved" 12 "Reserved" 13 "Reserved" 14 "Reserved" 15 "Reserved" ;
VAL_ 883 ECC_IninSts 0 "Incomplete_initialization" 1 "initialization_completed" ;
VAL_ 883 ECC_PwrSysHeatMngtSts 0 "No_action" 1 "Self_circulation_state" 2 "Forced_cooling" 3 "Reserved" ;
VAL_ 883 ECC_ACSts 0 "Off_state" 1 "ON_state" ;
VAL_ 883 ECC_AirClnSts 0 "Not_ON" 1 "On" ;
VAL_ 883 ECC_WindSpdSts 0 "Windless_gear" 1 "First_gear_of_wind_speed" 2 "Wind_speed_second_gear" 3 "third_gear_of_wind_speed" 4 "wind_speed_fourth_gear" 5 "Wind_speed_fifth_gear" 6 "Wind_speed_six" 7 "Wind_speed_seven_gear" 8 "Reserved" 9 "Reserved" 10 "Reserved" 11 "Reserved" 12 "Reserved" 13 "Reserved" 14 "Reserved" 15 "Reserved" ;
VAL_ 883 ECC_BackRowAirOutlModSts 0 "Rear_face_blowing" 1 "Face_blowing_foot_blowing_of_rear_row" 2 "Foot_blowing_of_rear_row" 3 "Back_row_cutoff" 4 "Reserved" 5 "Reserved" 6 "Reserved" 7 "Reserved" ;
VAL_ 883 ECC_DrvrTSetSts 0 "Inactive" 1 "Low" 2 "Low" 3 "Low" 4 "Low" 5 "Low" 6 "Low" 7 "Low" 8 "Low" 9 "Low" 10 "Low" 11 "Low" 12 "Low" 13 "Low" 14 "Low" 15 "Low" 16 "Low" 17 "Low" 18 "Low" 19 "Low" 20 "Low" 21 "Low" 22 "Low" 23 "Low" 24 "Low" 25 "Low" 26 "Low" 27 "Low" 28 "Low" 29 "Low" 30 "Low" 31 "Low" 32 "Low" 33 "Low" 34 "Low" 35 "Low" 36 "18ï¿½ï¿½" 37 "18.5ï¿½ï¿½" 38 "19ï¿½ï¿½" 39 "19.5ï¿½ï¿½" 40 "20ï¿½ï¿½" 41 "20.5ï¿½ï¿½" 42 "21ï¿½ï¿½" 43 "21.5ï¿½ï¿½" 44 "22ï¿½ï¿½" 45 "22.5ï¿½ï¿½" 46 "23ï¿½ï¿½" 47 "23.5ï¿½ï¿½" 48 "24ï¿½ï¿½" 49 "24.5ï¿½ï¿½" 50 "25ï¿½ï¿½" 51 "25.5ï¿½ï¿½" 52 "26ï¿½ï¿½" 53 "26.5ï¿½ï¿½" 54 "27ï¿½ï¿½" 55 "27.5ï¿½ï¿½" 56 "28ï¿½ï¿½" 57 "28.5ï¿½ï¿½" 58 "29ï¿½ï¿½" 59 "29.5ï¿½ï¿½" 60 "30ï¿½ï¿½" 61 "30.5ï¿½ï¿½" 62 "31ï¿½ï¿½" 63 "31.5ï¿½ï¿½" 64 "32ï¿½ï¿½" 65 "High" 66 "High" 67 "High" 68 "High" 69 "High" 70 "High" 71 "High" 72 "High" 73 "High" 74 "High" 75 "High" 76 "High" 77 "High" 78 "High" 79 "High" 80 "High" 81 "High" 82 "High" 83 "High" 84 "High" 85 "High" 86 "High" 87 "High" 88 "High" 89 "High" 90 "High" 91 "High" 92 "High" 93 "High" 94 "High" 95 "High" 96 "High" 97 "High" 98 "High" 99 "High" 100 "High" 101 "High" 102 "High" 103 "High" 104 "High" 105 "High" 106 "High" 107 "High" 108 "High" 109 "High" 110 "High" 111 "High" 112 "High" 113 "High" 114 "High" 115 "High" 116 "High" 117 "High" 118 "High" 119 "High" 120 "High" 121 "High" 122 "High" 123 "High" 124 "High" 125 "High" 126 "High" 127 "High" 128 "High" 129 "High" 130 "High" 131 "High" 132 "High" 133 "High" 134 "High" 135 "High" 136 "High" 137 "High" 138 "High" 139 "High" 140 "High" 141 "High" 142 "High" 143 "High" 144 "High" 145 "High" 146 "High" 147 "High" 148 "High" 149 "High" 150 "High" 151 "High" 152 "High" 153 "High" 154 "High" 155 "High" 156 "High" 157 "High" 158 "High" 159 "High" 160 "High" 161 "High" 162 "High" 163 "High" 164 "High" 165 "High" 166 "High" 167 "High" 168 "High" 169 "High" 170 "High" 171 "High" 172 "High" 173 "High" 174 "High" 175 "High" 176 "High" 177 "High" 178 "High" 179 "High" 180 "High" 181 "High" 182 "High" 183 "High" 184 "High" 185 "High" 186 "High" 187 "High" 188 "High" 189 "High" 190 "High" 191 "High" 192 "High" 193 "High" 194 "High" 195 "High" 196 "High" 197 "High" 198 "High" 199 "High" 200 "High" 201 "High" 202 "High" 203 "High" 204 "High" 205 "High" 206 "High" 207 "High" 208 "High" 209 "High" 210 "High" 211 "High" 212 "High" 213 "High" 214 "High" 215 "High" 216 "High" 217 "High" 218 "High" 219 "High" 220 "High" 221 "High" 222 "High" 223 "High" 224 "High" 225 "High" 226 "High" 227 "High" 228 "High" 229 "High" 230 "High" 231 "High" 232 "High" 233 "High" 234 "High" 235 "High" 236 "High" 237 "High" 238 "High" 239 "High" 240 "High" 241 "High" 242 "High" 243 "High" 244 "High" 245 "High" 246 "High" 247 "High" 248 "High" 249 "High" 250 "High" 251 "High" 252 "High" 253 "High" 254 "High" 255 "Invalid" ;
VAL_ 883 ECC_PassTSetSts 0 "Inactive" 1 "Low" 2 "Low" 3 "Low" 4 "Low" 5 "Low" 6 "Low" 7 "Low" 8 "Low" 9 "Low" 10 "Low" 11 "Low" 12 "Low" 13 "Low" 14 "Low" 15 "Low" 16 "Low" 17 "Low" 18 "Low" 19 "Low" 20 "Low" 21 "Low" 22 "Low" 23 "Low" 24 "Low" 25 "Low" 26 "Low" 27 "Low" 28 "Low" 29 "Low" 30 "Low" 31 "Low" 32 "Low" 33 "Low" 34 "Low" 35 "Low" 36 "18ï¿½ï¿½" 37 "18.5ï¿½ï¿½" 38 "19ï¿½ï¿½" 39 "19.5ï¿½ï¿½" 40 "20ï¿½ï¿½" 41 "20.5ï¿½ï¿½" 42 "21ï¿½ï¿½" 43 "21.5ï¿½ï¿½" 44 "22ï¿½ï¿½" 45 "22.5ï¿½ï¿½" 46 "23ï¿½ï¿½" 47 "23.5ï¿½ï¿½" 48 "24ï¿½ï¿½" 49 "24.5ï¿½ï¿½" 50 "25ï¿½ï¿½" 51 "25.5ï¿½ï¿½" 52 "26ï¿½ï¿½" 53 "26.5ï¿½ï¿½" 54 "27ï¿½ï¿½" 55 "27.5ï¿½ï¿½" 56 "28ï¿½ï¿½" 57 "28.5ï¿½ï¿½" 58 "29ï¿½ï¿½" 59 "29.5ï¿½ï¿½" 60 "30ï¿½ï¿½" 61 "30.5ï¿½ï¿½" 62 "31ï¿½ï¿½" 63 "31.5ï¿½ï¿½" 64 "32ï¿½ï¿½" 65 "High" 66 "High" 67 "High" 68 "High" 69 "High" 70 "High" 71 "High" 72 "High" 73 "High" 74 "High" 75 "High" 76 "High" 77 "High" 78 "High" 79 "High" 80 "High" 81 "High" 82 "High" 83 "High" 84 "High" 85 "High" 86 "High" 87 "High" 88 "High" 89 "High" 90 "High" 91 "High" 92 "High" 93 "High" 94 "High" 95 "High" 96 "High" 97 "High" 98 "High" 99 "High" 100 "High" 101 "High" 102 "High" 103 "High" 104 "High" 105 "High" 106 "High" 107 "High" 108 "High" 109 "High" 110 "High" 111 "High" 112 "High" 113 "High" 114 "High" 115 "High" 116 "High" 117 "High" 118 "High" 119 "High" 120 "High" 121 "High" 122 "High" 123 "High" 124 "High" 125 "High" 126 "High" 127 "High" 128 "High" 129 "High" 130 "High" 131 "High" 132 "High" 133 "High" 134 "High" 135 "High" 136 "High" 137 "High" 138 "High" 139 "High" 140 "High" 141 "High" 142 "High" 143 "High" 144 "High" 145 "High" 146 "High" 147 "High" 148 "High" 149 "High" 150 "High" 151 "High" 152 "High" 153 "High" 154 "High" 155 "High" 156 "High" 157 "High" 158 "High" 159 "High" 160 "High" 161 "High" 162 "High" 163 "High" 164 "High" 165 "High" 166 "High" 167 "High" 168 "High" 169 "High" 170 "High" 171 "High" 172 "High" 173 "High" 174 "High" 175 "High" 176 "High" 177 "High" 178 "High" 179 "High" 180 "High" 181 "High" 182 "High" 183 "High" 184 "High" 185 "High" 186 "High" 187 "High" 188 "High" 189 "High" 190 "High" 191 "High" 192 "High" 193 "High" 194 "High" 195 "High" 196 "High" 197 "High" 198 "High" 199 "High" 200 "High" 201 "High" 202 "High" 203 "High" 204 "High" 205 "High" 206 "High" 207 "High" 208 "High" 209 "High" 210 "High" 211 "High" 212 "High" 213 "High" 214 "High" 215 "High" 216 "High" 217 "High" 218 "High" 219 "High" 220 "High" 221 "High" 222 "High" 223 "High" 224 "High" 225 "High" 226 "High" 227 "High" 228 "High" 229 "High" 230 "High" 231 "High" 232 "High" 233 "High" 234 "High" 235 "High" 236 "High" 237 "High" 238 "High" 239 "High" 240 "High" 241 "High" 242 "High" 243 "High" 244 "High" 245 "High" 246 "High" 247 "High" 248 "High" 249 "High" 250 "High" 251 "High" 252 "High" 253 "High" 254 "High" 255 "Invalid" ;
VAL_ 883 ECC_HeatSts 0 "Off_state" 1 "ON_state" ;
VAL_ 883 ECC_AUTOSts 0 "Off" 1 "On" ;
VAL_ 883 ECC_SYNCSts 0 "Off" 1 "On" ;
VAL_ 883 ECC_InfoSysWrmColdDisp 0 "No_action" 1 "Natural_wind" 2 "Cold_air" 3 "Hot_air" ;
VAL_ 883 ECC_CircSts 0 "Inner_circulation_state" 1 "outer_circulation_state" ;
VAL_ 883 ECC_ParticleConcVld 0 "Initializing" 1 "Valid" 2 "Invalid" 3 "Reserved" ;
VAL_ 883 ECC_OutdT 255 "Invalid" ;
VAL_ 883 ECC_OutdTVld 0 "Initializing" 1 "Valid" 2 "Invalid" 3 "Reserved" ;
VAL_ 883 ECC_MaxFrntDefrst 0 "Not_opened" 1 "Open" ;
VAL_ 883 ECC_HeatMngtSysFlt 0 "Normal" 1 "Fault" ;
VAL_ 883 ECC_HeatMngtFctLim 0 "Functional" 1 "function_limit" ;
VAL_ 883 ECC_DrvrAirOutlMod 0 "Reserved" 1 "driver_face_blowing_mode" 2 "driver_face_blowing/foot_blowing_mode" 3 "Driver_foot_blowing_mode" 4 "driver_foot/window_mode" 5 "Window_blowing_mode" 6 "Reserved" 7 "Reserved" ;
VAL_ 883 ECC_PassAirOutlMod 0 "Reserved" 1 "front_passenger_face_blowing_mode" 2 "front_passenger_face_blowing/foot_blowing_mode" 3 "Front_passenger_foot_mode" 4 "Front_passenger_foot/window_mode" 5 "Reserved" 6 "Reserved" 7 "Reserved" ;
VAL_ 883 ECC_RemSts 0 "Standby" 1 "Working" 2 "Fault" 3 "Reserved" ;
VAL_ 883 ECC_OTAInhbRdy 0 "Initial" 1 "Inhibit" 2 "Not_Inhibit" 3 "Invalid" ;
VAL_ 1137 PLGM_UsrSetTrMaxHei 0 "Inactive" 1 "Reserved" 2 "Reserved" 3 "Reserved" 4 "Reserved" 5 "Reserved" 6 "Reserved" 7 "Reserved" 8 "Reserved" 9 "Reserved" 10 "Reserved" 11 "Reserved" 12 "Reserved" 13 "Reserved" 14 "Reserved" 15 "Reserved" 16 "Reserved" 17 "Reserved" 18 "Reserved" 19 "Reserved" 20 "Reserved" 21 "Reserved" 22 "Reserved" 23 "Reserved" 24 "Reserved" 25 "Reserved" 26 "Reserved" 27 "Reserved" 28 "Reserved" 29 "Reserved" 30 "Reserved" 31 "Reserved" 32 "Reserved" 33 "Reserved" 34 "Reserved" 35 "Reserved" 36 "Reserved" 37 "Reserved" 38 "Reserved" 39 "Reserved" 40 "Reserved" 41 "Reserved" 42 "Reserved" 43 "Reserved" 44 "Reserved" 45 "Reserved" 46 "Reserved" 47 "Reserved" 48 "Reserved" 49 "Reserved" 50 "MaxHeight_Setting" 51 "MaxHeight_Setting" 52 "MaxHeight_Setting" 53 "MaxHeight_Setting" 54 "MaxHeight_Setting" 55 "MaxHeight_Setting" 56 "MaxHeight_Setting" 57 "MaxHeight_Setting" 58 "MaxHeight_Setting" 59 "MaxHeight_Setting" 60 "MaxHeight_Setting" 61 "MaxHeight_Setting" 62 "MaxHeight_Setting" 63 "MaxHeight_Setting" 64 "MaxHeight_Setting" 65 "MaxHeight_Setting" 66 "MaxHeight_Setting" 67 "MaxHeight_Setting" 68 "MaxHeight_Setting" 69 "MaxHeight_Setting" 70 "MaxHeight_Setting" 71 "MaxHeight_Setting" 72 "MaxHeight_Setting" 73 "MaxHeight_Setting" 74 "MaxHeight_Setting" 75 "MaxHeight_Setting" 76 "MaxHeight_Setting" 77 "MaxHeight_Setting" 78 "MaxHeight_Setting" 79 "MaxHeight_Setting" 80 "MaxHeight_Setting" 81 "MaxHeight_Setting" 82 "MaxHeight_Setting" 83 "MaxHeight_Setting" 84 "MaxHeight_Setting" 85 "MaxHeight_Setting" 86 "MaxHeight_Setting" 87 "MaxHeight_Setting" 88 "MaxHeight_Setting" 89 "MaxHeight_Setting" 90 "MaxHeight_Setting" 91 "MaxHeight_Setting" 92 "MaxHeight_Setting" 93 "MaxHeight_Setting" 94 "MaxHeight_Setting" 95 "MaxHeight_Setting" 96 "Reserved" 97 "Reserved" 98 "Reserved" 99 "Reserved" 100 "Reserved" 101 "Reserved" 102 "Reserved" 103 "Reserved" 104 "Reserved" 105 "Reserved" 106 "Reserved" 107 "Reserved" 108 "Reserved" 109 "Reserved" 110 "Reserved" 111 "Reserved" 112 "Reserved" 113 "Reserved" 114 "Reserved" 115 "Reserved" 116 "Reserved" 117 "Reserved" 118 "Reserved" 119 "Reserved" 120 "Reserved" 121 "Reserved" 122 "Reserved" 123 "Reserved" 124 "Reserved" 125 "Reserved" 126 "Reserved" 127 "Reserved" 128 "Reserved" 129 "Reserved" 130 "Reserved" 131 "Reserved" 132 "Reserved" 133 "Reserved" 134 "Reserved" 135 "Reserved" 136 "Reserved" 137 "Reserved" 138 "Reserved" 139 "Reserved" 140 "Reserved" 141 "Reserved" 142 "Reserved" 143 "Reserved" 144 "Reserved" 145 "Reserved" 146 "Reserved" 147 "Reserved" 148 "Reserved" 149 "Reserved" 150 "Reserved" 151 "Reserved" 152 "Reserved" 153 "Reserved" 154 "Reserved" 155 "Reserved" 156 "Reserved" 157 "Reserved" 158 "Reserved" 159 "Reserved" 160 "Reserved" 161 "Reserved" 162 "Reserved" 163 "Reserved" 164 "Reserved" 165 "Reserved" 166 "Reserved" 167 "Reserved" 168 "Reserved" 169 "Reserved" 170 "Reserved" 171 "Reserved" 172 "Reserved" 173 "Reserved" 174 "Reserved" 175 "Reserved" 176 "Reserved" 177 "Reserved" 178 "Reserved" 179 "Reserved" 180 "Reserved" 181 "Reserved" 182 "Reserved" 183 "Reserved" 184 "Reserved" 185 "Reserved" 186 "Reserved" 187 "Reserved" 188 "Reserved" 189 "Reserved" 190 "Reserved" 191 "Reserved" 192 "Reserved" 193 "Reserved" 194 "Reserved" 195 "Reserved" 196 "Reserved" 197 "Reserved" 198 "Reserved" 199 "Reserved" 200 "Reserved" 201 "Reserved" 202 "Reserved" 203 "Reserved" 204 "Reserved" 205 "Reserved" 206 "Reserved" 207 "Reserved" 208 "Reserved" 209 "Reserved" 210 "Reserved" 211 "Reserved" 212 "Reserved" 213 "Reserved" 214 "Reserved" 215 "Reserved" 216 "Reserved" 217 "Reserved" 218 "Reserved" 219 "Reserved" 220 "Reserved" 221 "Reserved" 222 "Reserved" 223 "Reserved" 224 "Reserved" 225 "Reserved" 226 "Reserved" 227 "Reserved" 228 "Reserved" 229 "Reserved" 230 "Reserved" 231 "Reserved" 232 "Reserved" 233 "Reserved" 234 "Reserved" 235 "Reserved" 236 "Reserved" 237 "Reserved" 238 "Reserved" 239 "Reserved" 240 "Reserved" 241 "Reserved" 242 "Reserved" 243 "Reserved" 244 "Reserved" 245 "Reserved" 246 "Reserved" 247 "Reserved" 248 "Reserved" 249 "Reserved" 250 "Reserved" 251 "Reserved" 252 "Reserved" 253 "Reserved" 254 "Reserved" 255 "Reserved" ;
VAL_ 1137 PLGM_LiRemdngReq_BCM 0 "No_Blink" 1 "Open" 2 "Closed" 3 "Set_MaxHeight_Successfully" 4 "Reserved" 5 "Reserved" 6 "Reserved" 7 "Reserved" ;
VAL_ 1137 PLGM_SoundRemdngReq_EHU 0 "No_whistle" 1 "moving_process_opening" 2 "Set_maxHeight_successfully" 3 "For_Anti-pinch" 4 "moving_process_closing" 5 "Key_fob/smartphone_in_trunk" 6 "Reserved" 7 "Reserved" ;
VAL_ 1137 PLGM_FctEnaRes 0 "Inactive" 1 "Active" ;
VAL_ 1137 PLGM_SysFltIndcn 0 "No_Failure" 1 "Failure_happened" ;
VAL_ 1137 PLGM_TrActnHandCmd 0 "Inactive" 1 "Open_Request_(Pulling_Up_By_Hand)" 2 "Close_Request_(Pulling_Down_By_Hand)" 3 "Reserved" ;
VAL_ 1137 PLGM_TrSwtStsIndcn 0 "Trunk_Closed" 1 "Trunk_Open_Fully" 2 "Trunk_Halt" 3 "Trunk_Opening" 4 "Trunk_Closing" 5 "Reserved" 6 "Reserved" 7 "Reserved" ;
VAL_ 1137 PLGM_TrLtchStsIndcn 0 "Full_Latched_PawlSwOff_tail_door_lock_full_locking_state" 1 "HalfLatched_StrikerLeverSwOn_LockProcess_The_tail_door_lock_is_half-locked" 2 "Open_PawlSwOn_tail_door_lock_fully_open_state" 3 "Initializing_the_door_lock_power-on_initialization_process" 4 "HalfLatched_StrikerLeverSwOn_Release" 5 "Snowload_tail_door_lock_'snow_load'_state" 6 "Reserved" 7 "Reserved" ;
VAL_ 1137 PLGM_TrSwtTrigOpenReq 0 "Inactive" 1 "Active" ;
VAL_ 1137 PLGM_OperMod 0 "Not_Learnt" 1 "Learnt,_But_Shipping_Mode,_With_Power_Lifting_Or_Closing_Function_Forbidden" 2 "Learnt,_With_Maximum_Height_Customization_Allowed" 3 "Reserved" ;
VAL_ 1137 PLGM_TrSwtSts 0 "Inactive" 1 "Active" ;
VAL_ 1137 PLGM_LimpHomeSts 0 "Inactive" 1 "Active" ;
VAL_ 1137 PLGM_DrvrSwtSts 0 "Inactive" 1 "Active" ;
VAL_ 1137 PLGM_TrInnrSwtSts 0 "Inactive" 1 "ShortPressed_TriggerTrunkAction" 2 "LongPressed_SetUserMaxHeight" 3 "Reserved" ;
VAL_ 1137 PLGM_AntipinchSts 0 "No_Pinch" 1 "Anti-pinch_Happened" ;
VAL_ 1137 PLGM_TrSts 0 "Closed" 1 "Open" ;
VAL_ 1137 PLGM_OTAInhbRdy 0 "Initial" 1 "Inhibit" 2 "Not_Inhibit" 3 "Invalid" ;
VAL_ 1137 PLGM_OTARdy_Fb 0 "Initial" 1 "Ready" 2 "Not_Ready" 3 "Invalid" ;
VAL_ 1137 PLGM_Tindcn_NTC 110 "Invalid" ;
VAL_ 1153 ADAS_ECUUnexpectedRst 0 "Normal" 1 "Abnormal" ;
VAL_ 1153 ADAS_ChkBattVoltFlt 0 "Normal" 1 "Abnormal" ;
VAL_ 1153 ADAS_1V25UnderOrOverVolt 0 "Normal" 1 "Abnormal" ;
VAL_ 1153 ADAS_3V3UnderOrOverVolt 0 "Normal" 1 "Abnormal" ;
VAL_ 1153 ADAS_5V0UnderOrOverVolt 0 "Normal" 1 "Abnormal" ;
VAL_ 1153 ADAS_BusHwErr 0 "Normal" 1 "Abnormal" ;
VAL_ 1153 ADAS_BusHwErr_FCM 0 "Normal" 1 "Abnormal" ;
VAL_ 1153 ADAS_BusHwErr_MRR 0 "Normal" 1 "Abnormal" ;
VAL_ 1153 ADAS_BusHwErr_CMRR_FL 0 "Normal" 1 "Abnormal" ;
VAL_ 1153 ADAS_BusDiagHwErr_CMRR_FR 0 "Normal" 1 "Abnormal" ;
VAL_ 1153 ADAS_ChkInvldSig_FCM 0 "Normal" 1 "Abnormal" ;
VAL_ 1153 ADAS_ChkInvldSig_CMRR_RL 0 "Normal" 1 "Abnormal" ;
VAL_ 1153 ADAS_ChkInvldSig_CMRR_FR 0 "Normal" 1 "Abnormal" ;
VAL_ 1153 ADAS_ChkInvldSig_CMRR_FL 0 "Normal" 1 "Abnormal" ;
VAL_ 1153 ADAS_ChkInvldSig_CMRR_RR 0 "Normal" 1 "Abnormal" ;
VAL_ 1153 ADAS_ChkInvldSig_MRR 0 "Normal" 1 "Abnormal" ;
VAL_ 1153 ADAS_ChkInvldSig_ESP 0 "Normal" 1 "Abnormal" ;
VAL_ 1153 ADAS_ChkInvldSig_ACU 0 "Normal" 1 "Abnormal" ;
VAL_ 1153 ADAS_ChkInvldSig_EPS 0 "Normal" 1 "Abnormal" ;
VAL_ 1153 ADAS_ChkInvldSig_iBooster 0 "Normal" 1 "Abnormal" ;
VAL_ 1153 ADAS_ChkInvldSig_YRS 0 "Normal" 1 "Abnormal" ;
VAL_ 1153 ADAS_ChkInvldSig_BCM 0 "Normal" 1 "Abnormal" ;
VAL_ 1153 ADAS_ChkInvldSig_ECC 0 "Normal" 1 "Abnormal" ;
VAL_ 1153 ADAS_ChkInvldSig_TBOX 0 "Normal" 1 "Abnormal" ;
VAL_ 1153 ADAS_ChkInvldSig_MCU_F 0 "Normal" 1 "Abnormal" ;
VAL_ 1153 ADAS_ChkInvldSig_MCU_R 0 "Normal" 1 "Abnormal" ;
VAL_ 1153 ADAS_ChkInvldSig_PLGM 0 "Normal" 1 "Abnormal" ;
VAL_ 1153 ADAS_ChkInvldSig_CIM 0 "Normal" 1 "Abnormal" ;
VAL_ 1153 ADAS_ChkInvldSig_VCU 0 "Normal" 1 "Abnormal" ;
VAL_ 1153 ADAS_ChkInvldSig_ICC 0 "Normal" 1 "Abnormal" ;
VAL_ 1153 ADAS_ChkInvldSig_PEPS 0 "Normal" 1 "Abnormal" ;
VAL_ 1153 ADAS_ChkInvldSig_TPMS 0 "Normal" 1 "Abnormal" ;
VAL_ 1153 ADAS_ChkInvldSig_AVAP 0 "Normal" 1 "Abnormal" ;
VAL_ 1153 ADAS_ComE2EFlt 0 "Normal" 1 "Abnormal" ;
VAL_ 1153 ADAS_ComLostFlt_FCM 0 "Normal" 1 "Abnormal" ;
VAL_ 1153 ADAS_ComLostFlt_CMRR_RL 0 "Normal" 1 "Abnormal" ;
VAL_ 1153 ADAS_ComLostFlt_CMRR_FL 0 "Normal" 1 "Abnormal" ;
VAL_ 1153 ADAS_ComLostFlt_CMRR_RR 0 "Normal" 1 "Abnormal" ;
VAL_ 1153 ADAS_ComLostFlt_CMRR_FR 0 "Normal" 1 "Abnormal" ;
VAL_ 1153 ADAS_ComLostFlt_MRR 0 "Normal" 1 "Abnormal" ;
VAL_ 1153 ADAS_ComLostFlt_ESP 0 "Normal" 1 "Abnormal" ;
VAL_ 1153 ADAS_ComLostFlt_ACU 0 "Normal" 1 "Abnormal" ;
VAL_ 1153 ADAS_ComLostFlt_EPS 0 "Normal" 1 "Abnormal" ;
VAL_ 1153 ADAS_ComLostFlt_iBooster 0 "Normal" 1 "Abnormal" ;
VAL_ 1153 ADAS_ComLostFlt_YRS 0 "Normal" 1 "Abnormal" ;
VAL_ 1153 ADAS_ComLostFlt_BCM 0 "Normal" 1 "Abnormal" ;
VAL_ 1153 ADAS_ComLostFlt_ECC 0 "Normal" 1 "Abnormal" ;
VAL_ 1153 ADAS_ComLostFlt_TBOX 0 "Normal" 1 "Abnormal" ;
VAL_ 1153 ADAS_ComLostFlt_MCU_F 0 "Normal" 1 "Abnormal" ;
VAL_ 1153 ADAS_ComLostFlt_MCU_R 0 "Normal" 1 "Abnormal" ;
VAL_ 1153 ADAS_ComLostFlt_PLGM 0 "Normal" 1 "Abnormal" ;
VAL_ 1153 ADAS_ComLostFlt_CIM 0 "Normal" 1 "Abnormal" ;
VAL_ 1153 ADAS_ComLostFlt_VCU 0 "Normal" 1 "Abnormal" ;
VAL_ 1153 ADAS_ComLostFlt_ICC 0 "Normal" 1 "Abnormal" ;
VAL_ 1153 ADAS_ComLostFlt_PEPS 0 "Normal" 1 "Abnormal" ;
VAL_ 1153 ADAS_ComLostFlt_TPMS 0 "Normal" 1 "Abnormal" ;
VAL_ 1153 ADAS_ComLostFlt_AVAP 0 "Normal" 1 "Abnormal" ;
VAL_ 1153 ADAS_ChkPublicCANBusOff 0 "Normal" 1 "Abnormal" ;
VAL_ 1153 ADAS_MstRAMTestErr 0 "Normal" 1 "Abnormal" ;
VAL_ 1153 ADAS_MstNVRAMTestErr 0 "Normal" 1 "Abnormal" ;
VAL_ 1153 ADAS_NVMChipErr 0 "Normal" 1 "Abnormal" ;
VAL_ 1153 ADAS_NVMStructErr 0 "Normal" 1 "Abnormal" ;
VAL_ 1153 ADAS_MstWdgErr 0 "Normal" 1 "Abnormal" ;
VAL_ 1153 ADAS_MstSOPTErr 0 "Normal" 1 "Abnormal" ;
VAL_ 1154 ADAS_MstHwstartupErr 0 "Normal" 1 "Abnormal" ;
VAL_ 1154 ADAS_MstHwCycTest 0 "Normal" 1 "Abnormal" ;
VAL_ 1154 ADAS_EOLCalOutOfRng 0 "Normal" 1 "Abnormal" ;
VAL_ 1154 ADAS_ECUTFlt 0 "Normal" 1 "Abnormal" ;
VAL_ 1154 ADAS_PwrModFlt 0 "Normal" 1 "Abnormal" ;
VAL_ 1154 ADAS_ComLostFlt_MFS 0 "Normal" 1 "Abnormal" ;
VAL_ 1154 ADAS_PrivateCANComE2EFlt_FCM 0 "Normal" 1 "Abnormal" ;
VAL_ 1154 ADAS_PrivateCANComE2EFlt_MRR 0 "Normal" 1 "Abnormal" ;
VAL_ 1154 ADAS_PrivateCANComE2EFlt_CMRR_FL 0 "Normal" 1 "Abnormal" ;
VAL_ 1154 ADAS_PrivateCANComE2EFlt_CMRR_FR 0 "Normal" 1 "Abnormal" ;
VAL_ 1154 ADAS_PrivateCANComE2EFlt_CMRR_RL 0 "Normal" 1 "Abnormal" ;
VAL_ 1154 ADAS_PrivateCANComE2EFlt_CMRR_RR 0 "Normal" 1 "Abnormal" ;
VAL_ 1154 ADAS_PrivateCANComLostFlt_FCM 0 "Normal" 1 "Abnormal" ;
VAL_ 1154 ADAS_PrivateCANComLostFlt_MRR 0 "Normal" 1 "Abnormal" ;
VAL_ 1154 ADAS_PrivateCANComLost_CMRR_FL 0 "Normal" 1 "Abnormal" ;
VAL_ 1154 ADAS_PrivateCANComLost_CMRR_FR 0 "Normal" 1 "Abnormal" ;
VAL_ 1154 ADAS_PrivateCANComLost_CMRR_RL 0 "Normal" 1 "Abnormal" ;
VAL_ 1154 ADAS_PrivateCANComLost_CMRR_RR 0 "Normal" 1 "Abnormal" ;
VAL_ 1154 ADAS_PERChkIntFltInfo 0 "Normal" 1 "Abnormal" ;
VAL_ 1154 ADAS_HWAActvFlg 0 "Inactive" 1 "Activated" ;
VAL_ 1154 ADAS_HWASucFlg 0 "Not_completed" 1 "Complete" ;
VAL_ 1159 FCM_ComLostFlt_ESP 0 "Normal" 1 "Abnormal" ;
VAL_ 1159 FCM_ComLostFlt_iBooster 0 "Normal" 1 "Abnormal" ;
VAL_ 1159 FCM_ComLostFlt_EPS 0 "Normal" 1 "Abnormal" ;
VAL_ 1159 FCM_ComLostFlt_YRS 0 "Normal" 1 "Abnormal" ;
VAL_ 1159 FCM_ComLostFlt_BCM 0 "Normal" 1 "Abnormal" ;
VAL_ 1159 FCM_ComLostFlt_ECC 0 "Normal" 1 "Abnormal" ;
VAL_ 1159 FCM_ComLostFlt_TBOX 0 "Normal" 1 "Abnormal" ;
VAL_ 1159 FCM_ComLostFlt_CIM 0 "Normal" 1 "Abnormal" ;
VAL_ 1159 FCM_ComLostFlt_ICC 0 "Normal" 1 "Abnormal" ;
VAL_ 1159 FCM_ComLostFlt_MRR 0 "Normal" 1 "Abnormal" ;
VAL_ 1159 FCM_ComLostFlt_PEPS 0 "Normal" 1 "Abnormal" ;
VAL_ 1159 FCM_ComLostFlt_ADAS 0 "Normal" 1 "Abnormal" ;
VAL_ 1159 FCM_ComE2EFlt 0 "Normal" 1 "Abnormal" ;
VAL_ 1159 FCM_ChkInvldSig_ESP 0 "Normal" 1 "Abnormal" ;
VAL_ 1159 FCM_ChkInvldSig_iBooster 0 "Normal" 1 "Abnormal" ;
VAL_ 1159 FCM_ChkInvldSig_EPS 0 "Normal" 1 "Abnormal" ;
VAL_ 1159 FCM_ChkInvldSig_YRS 0 "Normal" 1 "Abnormal" ;
VAL_ 1159 FCM_ChkInvldSig_CIM 0 "Normal" 1 "Abnormal" ;
VAL_ 1159 FCM_ChkInvldSig_ECC 0 "Normal" 1 "Abnormal" ;
VAL_ 1159 FCM_ChkInvldSig_PEPS 0 "Normal" 1 "Abnormal" ;
VAL_ 1159 FCM_ChkInvldSig_ICC 0 "Normal" 1 "Abnormal" ;
VAL_ 1159 FCM_ChkPrivateCANBusOff 0 "Normal" 1 "Abnormal" ;
VAL_ 1159 FCM_ChkPublicCANBusOff 0 "Normal" 1 "Abnormal" ;
VAL_ 1159 FCM_BattVoltBelowThd 0 "Normal" 1 "Abnormal" ;
VAL_ 1159 FCM_BattVoltOverThd 0 "Normal" 1 "Abnormal" ;
VAL_ 1159 FCM_CamBli 0 "Normal" 1 "Abnormal" ;
VAL_ 1159 FCM_ECUTmpHiTProtn 0 "Normal" 1 "Abnormal" ;
VAL_ 1159 FCM_IntCircOutpVoltBelowThd 0 "Normal" 1 "Abnormal" ;
VAL_ 1159 FCM_IntCircOutpVoltOverThd 0 "Normal" 1 "Abnormal" ;
VAL_ 1159 FCM_IntCircPrmntFlt 0 "Normal" 1 "Abnormal" ;
VAL_ 1159 FCM_MatchParaErr 0 "Normal" 1 "Abnormal" ;
VAL_ 1159 FCM_VehCfgInfoErr 0 "Normal" 1 "Abnormal" ;
VAL_ 1159 FCM_IntCircFlt 0 "Normal" 1 "Abnormal" ;
VAL_ 1159 FCM_DLCFlt_ESP 0 "Normal" 1 "Abnormal" ;
VAL_ 1159 FCM_DLCFlt_iBooster 0 "Normal" 1 "Abnormal" ;
VAL_ 1159 FCM_DLCFlt_EPS 0 "Normal" 1 "Abnormal" ;
VAL_ 1159 FCM_DLCFlt_YRS 0 "Normal" 1 "Abnormal" ;
VAL_ 1159 FCM_DLCFlt_BCM 0 "Normal" 1 "Abnormal" ;
VAL_ 1159 FCM_DLCFlt_ECC 0 "Normal" 1 "Abnormal" ;
VAL_ 1159 FCM_DLCFlt_TBOX 0 "Normal" 1 "Abnormal" ;
VAL_ 1159 FCM_DLCFlt_CIM 0 "Normal" 1 "Abnormal" ;
VAL_ 1159 FCM_DLCFlt_ICC 0 "Normal" 1 "Abnormal" ;
VAL_ 1159 FCM_DLCFlt_MRR 0 "Normal" 1 "Abnormal" ;
VAL_ 1159 FCM_DLCFlt_PEPS 0 "Normal" 1 "Abnormal" ;
VAL_ 1159 FCM_DLCFlt_ADAS 0 "Normal" 1 "Abnormal" ;
VAL_ 1159 FCM_OnlineCalOutOfRng 0 "Normal" 1 "Abnormal" ;
VAL_ 1159 FCM_IniCalOutOfRng 0 "Normal" 1 "Abnormal" ;
VAL_ 1159 FCM_IniCalTimeout 0 "Normal" 1 "Abnormal" ;
VAL_ 1159 FCM_NotCal 0 "Normal" 1 "Abnormal" ;
VAL_ 1159 FCM_OTARdy_Fb 0 "Initial" 1 "Ready" 2 "Not_Ready" 3 "Invalid" ;
VAL_ 1300 MFS_LeBtnNorth 0 "No_Pressed" 1 "Pressed" 2 "Long_Press" 3 "Reserved" ;
VAL_ 1300 MFS_LeBtnSouth 0 "No_Pressed" 1 "Pressed" 2 "Long_Press" 3 "Reserved" ;
VAL_ 1300 MFS_LeBtnWest 0 "No_Pressed" 1 "Pressed" 2 "Long_Press" 3 "Reserved" ;
VAL_ 1300 MFS_LeBtnEast 0 "No_Pressed" 1 "Pressed" 2 "Long_Press" 3 "Reserved" ;
VAL_ 1300 MFS_LeRollUp 0 "No_Pressed_Not_pressed" 1 "1_unit_up_focus" 2 "2_units_focus_up" 3 "3_units_up_focus" 4 "4_units_focus_up" 5 "5_units_focus_up" 6 "6_units_in_focus_up" 7 "7_units_up_focus" ;
VAL_ 1300 MFS_LeRollDwn 0 "No_Pressed_Not_pressed" 1 "Focus_1_unit_down" 2 "Focus_by_2_units" 3 "Focus_3_units_down" 4 "4_units_down_focus" 5 "Focus_down_5_units" 6 "Focus_down:6_units" 7 "Focus_7_units_down" ;
VAL_ 1300 MFS_LeRollPress 0 "No_Pressed" 1 "Pressed" 2 "Reserved" 3 "Reserved" ;
VAL_ 1300 MFS_RiBtnNorth 0 "No_Pressed" 1 "Pressed" 2 "Long_Press" 3 "Reserved" ;
VAL_ 1300 MFS_RiBtnSouth 0 "No_Pressed" 1 "Pressed" 2 "Long_Press" 3 "Reserved" ;
VAL_ 1300 MFS_RiBtnWest 0 "No_Pressed" 1 "Pressed" 2 "Long_Press" 3 "Reserved" ;
VAL_ 1300 MFS_RiBtnEast 0 "No_Pressed" 1 "Pressed" 2 "Long_Press" 3 "Reserved" ;
VAL_ 1300 MFS_RiRollUp 0 "No_Pressed_Not_pressed" 1 "1_unit_up_focus" 2 "2_units_focus_up" 3 "3_units_up_focus" 4 "4_units_focus_up" 5 "5_units_focus_up" 6 "6_units_in_focus_up" 7 "7_units_up_focus" ;
VAL_ 1300 MFS_RiRollDwn 0 "No_Pressed_Not_pressed" 1 "Focus_1_unit_down" 2 "Focus_by_2_units" 3 "Focus_3_units_down" 4 "4_units_down_focus" 5 "Focus_down_5_units" 6 "Focus_down:6_units" 7 "Focus_7_units_down" ;
VAL_ 1300 MFS_RiRollPress 0 "No_Pressed" 1 "Pressed" 2 "Reserved" 3 "Reserved" ;
VAL_ 1300 MFS_Ri_Fail 0 "No_failure" 1 "Connection_failure" 2 "Button_stuck" 3 "Reserved" ;
VAL_ 1300 MFS_Le_Fail 0 "No_failure" 1 "Controller_failure" 2 "Button_stuck" 3 "Reserved" ;
VAL_ 1317 TBOX_GPSHei 1401 "Invalid" ;
VAL_ 1318 TBOX_GPSLongi -1 "Invalid" ;
VAL_ 1318 TBOX_GPSLati -1 "Invalid" ;
VAL_ 1319 ADAS_DrvrAttention_Zone 0 "UNKNOWN" 1 "ON_ROAD_CENTER" 2 "ON_ROAD_RIGHT" 3 "INSTRUMENT_CLUSTER" 4 "CENTER_CONSOLE" 5 "REAR_MIRROR" 6 "DRIVER_MIRROR" 7 "PASSENGER_MIRROR" 8 "DRIVER_LAP" 9 "PASSENGER_FOOTWELL" 10 "CUSTOM" 11 "OTHER" 12 "Not_Used_1" 13 "Not_Used_2" 14 "Not_Used_3" 15 "FAULTY" ;
VAL_ 1319 ADAS_DrvrAlert_State 0 "UNKNOWN" 1 "EYES_OPEN_ON_ROAD" 2 "EYES_OPEN_OFF_ROAD" 3 "EYES_CLOSED_OFF_ROAD" 4 "FAULTY" 5 "reserved" 6 "reserved" 7 "reserved" ;
VAL_ 1319 ADAS_DMS_Camera_Blockage_Status 0 "UNKNOWN" 1 "OK" 2 "BLOCKED" 3 "FAULTY" ;
VAL_ 1319 ADAS_DrvrEngagement_Level_Status 0 "UNKNOWN" 1 "ATTENTIVE" 2 "INATTENTIVE" 3 "DISTRACTED" 4 "DISENGAGED" 5 "NotUsed_1" 6 "NotUsed_2" 7 "FAULTY" ;
VAL_ 1319 ADAS_DMS_IR_Blockage_Status 0 "UNKNOWN" 1 "OK" 2 "BLOCKED" 3 "FAULTY" ;
VAL_ 1319 ADAS_DrvrEngagement_Level_Conf 0 "UNKNOWN" 1 "LOW" 2 "LOW_MEDIUM" 3 "MEDIUM" 4 "MEDIUM_HIGH" 5 "HIGH" 6 "NotUsed" 7 "FAULTY" ;
VAL_ 1319 ADAS_DrvrImpairment_Level_Stat 0 "UNKNOWN" 1 "ALERT" 2 "DROWSY" 3 "MICROSLEEP" 4 "ASLEEP" 5 "NotUsed_1" 6 "NotUsed_2" 7 "FAULTY" ;
VAL_ 1319 ADAS_DrvrImpairment_Level_Conf 0 "UNKNOWN" 1 "LOW" 2 "LOW_MEDIUM" 3 "MEDIUM" 4 "MEDIUM_HIGH" 5 "HIGH" 6 "NotUsed" 7 "FAULTY" ;
VAL_ 1319 ADAS_DrvrDrowsiness_Level 0 "UNKNOWN" 1 "NOT_DROWSY" 2 "DROWSY_1" 3 "DROWSY_2" 4 "DROWSY_3" 5 "DROWSY_4" 6 "DROWSY_5" 7 "DROWSY_6" 8 "DROWSY_7" 9 "DROWSY_8" 10 "DROWSY_9" 11 "DROWSY_10" 12 "NotUsed_1" 13 "NotUsed_2" 14 "NotUsed_3" 15 "FAULTY" ;
VAL_ 1319 ADAS_DCAA_DrvrDrowsinessVld 0 "No_confidence" 1 "Low_confidence" 2 "Medium_confidence" 3 "High_confidence" ;
VAL_ 1319 ADAS_DCAA_DrvrAttentionLvl 0 "No_level_detected" 1 "Attention_ok" 2 "A_ttention_not_OK" 3 "Reserved" ;
VAL_ 1319 ADAS_DCAA_DrvrAttentionVld 0 "No_confidence" 1 "Low_confidence" 2 "Medium_confidence" 3 "High_confidence" ;
VAL_ 1319 ADAS_DCAA_DrvrDrowsinessLvl 0 "No_level_deteced" 1 "Extremely_Alert" 2 "Very_Alert" 3 "Alert" 4 "Rather_alert" 5 "Neither_alert_nor_sleepy" 6 "Some_signs_of_sleepiness" 7 "Sleepy_no_effort_to_keep_awake" 8 "Sleepy_some_effort_to_keep_awake" 9 "Very_sleepy_great_effort_to_keep_awake_fighting_sleep" 10 "reserved" 11 "reserved" 12 "reserved" 13 "reserved" 14 "reserved" 15 "reserved" ;
VAL_ 1319 ADAS_DMSDrvrDetn 0 "Inactive" 1 "Unknown" 2 "No_Driver" 3 "Fake_Driver" 4 "Real_Driver" 5 "Real_Driver_Fake_Eyes" 6 "Possible_Driver" 7 "Faulty" ;
VAL_ 1319 ADAS_DMS_IRSts 0 "Inactive" 1 "Active" ;
VAL_ 1322 ICC_FACM_DynmcSenstvty 0 "On" 1 "Off" ;
VAL_ 1322 ICC_UsrProfTiGapSet 0 "Invalid" 1 "TimeGap_1_shortest" 2 "TimeGap_2" 3 "TimeGap_3" 4 "TimeGap_4_longest" 5 "Reserved" 6 "Reserved" 7 "Reserved" ;
VAL_ 1322 ICC_LKA_Setting 0 "Off" 1 "Warning_only" 2 "Warning_and_Steering" 3 "Reserved" ;
VAL_ 1322 ICC_FACM_Setting 0 "Off" 1 "Warning_only" 2 "Warning_and_Brake" 3 "Reserved" ;
VAL_ 1322 ICC_AEB_Sensitivity 0 "Normal" 1 "Early" 2 "Late_or_reduced" 3 "Reserved" ;
VAL_ 1322 ICC_BACM_Setting 0 "Off" 1 "Warning_only" 2 "Warning_and_Brake" 3 "Reserved" ;
VAL_ 1322 ICC_BACM_Sensitivity 0 "Normal" 1 "Early" 2 "Late_or_reduced" 3 "Reserved" ;
VAL_ 1322 ICC_AEB_JerkSetReq 0 "Off" 1 "On(Default)" 2 "Reserved" 3 "Reserved" ;
VAL_ 1322 ICC_ActvStyGlblSetting 0 "On" 1 "Off" ;
VAL_ 1322 ICC_TSR_Setting 0 "Off" 1 "On" ;
VAL_ 1322 ICC_ESA_Setting 0 "Off" 1 "On" ;
VAL_ 1322 ICC_ELKASteeringInterventionSet 0 "Off" 1 "On" ;
VAL_ 1322 ICC_LaneTrajectorySetting 0 "Off" 1 "On" ;
VAL_ 1322 ICC_ACCSwt 0 "Invalid" 1 "On" 2 "Off" 3 "reserved" ;
VAL_ 1322 ICC_ACCAutoSpdSts 0 "Off" 1 "On" ;
VAL_ 1322 ICC_ACCSpdStepSize 0 "Step_1_unit" 1 "Step_5_unit" ;
VAL_ 1322 ICC_ACCFuncTyp 0 "Default" 1 "Basic" 2 "Advanced" 3 "ISA" 4 "Fault" ;
VAL_ 1322 ICC_ACCSpdLimOffsTyp 0 "Exceeding_limit_not_allowed" 1 "Percentage" 2 "Speed_value" 3 "Reserved" ;
VAL_ 1322 ICC_ACCTerrainSetting 0 "Not_enabled" 1 "Enabled" ;
VAL_ 1322 ICC_ACCTiGapCfm 0 "Default/No_Selection" 1 "Driver_Accepted" 2 "Driver_Rejected" 3 "Reserved" ;
VAL_ 1322 ICC_ISASetting 0 "Off" 1 "Display_Warning_Only" 2 "Display_and_chime_warning" 3 "Display_and_Control" 4 "Display_and_chime_Warning_+_Control" ;
VAL_ 1322 ICC_FCTA_Sensitivity 0 "Normal" 1 "Early" 2 "Late_or_reduced" 3 "Reserved" ;
VAL_ 1322 ICC_ISAWarnStopReq 0 "No_Driver_ISA_warning_stop_request_(User_not_acknowledged)" 1 "Driver_ISA_warning_stop_request_(User_acknowledged)" ;
VAL_ 1322 ICC_TLR_Setting 0 "Off" 1 "On" 2 "chime_warning" 3 "chime_red_light" 4 "chime_green_light" ;
VAL_ 1322 ICC_FCTA_Setting 0 "Off" 1 "Warning_only" 2 "Warning_and_Brake" 3 "Reserved" ;
VAL_ 1329 ICC_TotMilgVld_ODO 0 "Value_OK" 1 "Value_Unreliable" ;
VAL_ 1329 ICC_DispVehSpdUnit 0 "KMH" 1 "MPH" ;
VAL_ 1329 ICC_ADASSigFlt 0 "No_Failure" 1 "Reversible_Failure" 2 "Irrversible_Failure" 3 "Reserved" ;
VAL_ 1329 ICC_DispFlt 0 "No_Error_No_error" 1 "Error_error" ;
VAL_ 1329 ICC_WorkshopMode 0 "Init" 1 "Active" 2 "Inactive" 3 "Invalid" ;
